VERSION ""

NS_ :

BS_:

BU_: ARM APIM_CDC APIM_CISM APIM ESPM DSP APIM_CIM FCIMB RACM_RCIM HUD_ADV WCM TRM_ITRM ACM GWM _delete IPC GENERIC TSTR
VAL_TABLE_ PwSysULoFalt_D_Stat 15 "Not_Used_6" 14 "LowBatterySOC" 13 "PSS_Shed2_Contin" 12 "Not_Used_4" 11 "Not_Used_3" 10 "Not_Used_2" 9 "BattMonitoringSensorFault" 8 "LowBattVoltDuringPwSrcOn" 7 "LowBatt2_PowerSaveMode" 6 "LowBatt1_Warning" 5 "Overvoltage" 4 "Fault_NoOutput" 3 "Fault_ReducedOutput" 2 "Fault_Nonspecific" 1 "Cluster_Proveout" 0 "No_Fault" ;
VAL_TABLE_ AccStopMde_D_Rq 3 "Stop_Mode_Active" 2 "EPBApplyOrBrakeReleaseWarn" 1 "Limit_Rolling_Speed" 0 "Stop_Mode_Not_Active" ;
VAL_TABLE_ Eng_D_Stat 3 "NotUsed" 2 "EngAutoStopped" 1 "EngOn" 0 "EngOff" ;
VAL_TABLE_ ElPw_D_Stat 7 "NotUsed_3" 6 "NotUsed_2" 5 "NotUsed_1" 4 "Fault_Limited" 3 "LV_Event_In_Progress" 2 "Not_Supported_Imminent" 1 "Supported" 0 "Not_Supported" ;
VAL_TABLE_ PwPckTq_D_Stat 3 "PwPckOn_TqAvailable" 2 "StartInPrgrss_TqNotAvail" 1 "PwPckOn_TqNotAvailable" 0 "PwPckOff_TqNotAvailable" ;
VAL_TABLE_ BattTracCool_D_Falt 3 "NotUsed" 2 "CoolSysPartialyOperational" 1 "Cooling_System_Faulted" 0 "Cooling_System_Operational" ;
VAL_TABLE_ Fault_FF 255 "Fault" ;
VAL_TABLE_ ElCmprOverTe_D_Stat 3 "OverTempStop" 2 "OverTempWarning" 1 "Normal" 0 "Undefined" ;
VAL_TABLE_ ElCmprUHi_D_Stat 3 "Overvoltage" 2 "Undervoltage" 1 "InRange" 0 "Undetermined" ;
VAL_TABLE_ ElCmpr_D_Stat 7 "Signal_Invalid" 6 "Comp_Off_ActlSpd_Abnormal" 5 "Comp_Off_TrgtSpd_OutRange" 4 "Comp_Shutdown" 3 "Comp_Stopped_Self_Protect" 2 "Comp_Degraded" 1 "Comp_On" 0 "Comp_Off" ;
VAL_TABLE_ Southern_Northern 3 "Fault" 2 "Northern" 1 "Southern" 0 "Invalid" ;
VAL_TABLE_ PsngrFrntDetct_D_Actl 3 "Unknown" 2 "Empty" 0 "Faulty" 1 "Occupied" ;
VAL_TABLE_ Inactive_Supported_NotSup 3 "Not_Used" 2 "Not_Supported" 1 "Supported" 0 "Inactive" ;
VAL_TABLE_ Normal_Mode1_2 3 "Undefined" 2 "Mode2" 1 "Mode1" 0 "Normal_Mode" ;
VAL_TABLE_ LaActvAvail 3 "LKA_LCA_LDW_Avail" 2 "LCA_LKA_Avail_LDW_Suppress" 1 "LCA_LKA_Suppress_LDW_Avail" 0 "LCA_LKA_LDW_Suppress" ;
VAL_TABLE_ LA_NotDenied 1 "LA_Denied" 0 "LA_Not_Denied" ;
VAL_TABLE_ HandsOn_Off 1 "Hands_Off" 0 "Hands_On" ;
VAL_TABLE_ Fault_3FF 1023 "Fault" ;
VAL_TABLE_ VedsEvnt_6 5 "Unused_3" 4 "Unused_2" 3 "Unused_1" 2 "NotBelted" 1 "Belted" 0 "NoEvent" 7 "Fault" 6 "NotSupported" ;
VAL_TABLE_ VedsEvnt_5 7 "Fault" 6 "NotSupported" 5 "Unused_3" 4 "Unused_2" 3 "Unused_1" 2 "ChildNotDetected" 1 "ChildDetected" 0 "NoEvent" ;
VAL_TABLE_ VedsEvnt_4 7 "Fault" 6 "NotSupported" 5 "Unused_3" 4 "Unused_2" 3 "Unused_1" 2 "NotDeployed" 1 "Deployed" 0 "NoEvent" ;
VAL_TABLE_ VedsEvnt_3 0 "NoEvent" 255 "Fault" 254 "NotSupported" ;
VAL_TABLE_ VedsEvnt_2 7 "Fault" 6 "NotSupported" 5 "Unused_3" 4 "Unused_2" 3 "Unused_1" 2 "Yes" 1 "No" 0 "NoEvent" ;
VAL_TABLE_ VedsEvnt_1 7 "Fault" 6 "NotSupported" 5 "Unused" 4 "Rolllover" 3 "Rear" 2 "Side" 1 "Frontal" 0 "NoEvent" ;
VAL_TABLE_ Fault_F 15 "Fault" ;
VAL_TABLE_ Fault_1F 31 "Fault" ;
VAL_TABLE_ TmsStatRqDsply 15 "Reserved4" 14 "Reserved3" 13 "Reserved2" 12 "Crawl_Mode_4LOW_Reqd" 11 "Economy_Mode_Select" 10 "ModeChangeNotAvailable" 9 "Terrain_Sys_Not_Avail" 8 "Terrain_System_Fault" 7 "Mode_Change_InProgress" 6 "Dynamics_Mode_Select" 5 "Rock_Crawl_Mode_Select" 4 "Sand_Mode_Select" 3 "Mud_Ruts_Mode_Select" 2 "Low_Mu_Mode_Select" 1 "Special_Modes_Off" 0 "No_Message" ;
VAL_TABLE_ LockInhibit 1 "Inhibit" 0 "No_Inhibit" ;
VAL_TABLE_ Temp_Units 2 "Fahrenheit" 1 "Celsius" 0 "Off" ;
VAL_TABLE_ DieslFuelBio_B_ActlDrv 1 "Biodiesel_User" 0 "Non_Biodiesel_User" ;
VAL_TABLE_ Invalid_FFF 4095 "Invalid" ;
VAL_TABLE_ Off_0x0 0 "Off" ;
VAL_TABLE_ ParkAid_Chime 15 "Zone15_Chime" 14 "Zone14_Chime" 13 "Zone13_Chime" 12 "Zone12_Chime" 11 "Zone11_Chime" 10 "Zone10_Chime" 9 "Zone9_Chime" 8 "Zone8_Chime" 7 "Zone7_Chime" 6 "Zone6_Chime" 5 "Zone5_Chime" 4 "Zone4_Chime" 3 "Zone3_Chime" 2 "Zone2_Chime" 1 "Zone1_Chime" 0 "No_Chime" ;
VAL_TABLE_ Shed_Feature_Group_ID 16 "PtcHeater" 30 "NotUsed_7" 29 "NotUsed_6" 28 "NotUsed_5" 27 "NotUsed_4" 26 "NotUsed_3" 25 "NotUsed_2" 24 "NotUsed_1" 23 "Dcac" 22 "UpFitter_6" 21 "UpFitter_5" 20 "UpFitter_4" 19 "UpFitter_3" 18 "UpFitter_2" 17 "UpFitter_1" 14 "HtdMirr" 13 "HvacRearBlwr_Third" 12 "HvacRearBlwr_Second" 11 "HvacRearBlwr_First" 31 "All LSHED1 Features" 10 "Htd_Windscrn" 9 "SpltHtdBcklight_HtdMirr" 8 "HtdBcklight_HtdMirr" 7 "HtdCoolSeat_FrtDriver" 6 "HtdCoolSeat_FrtPass" 5 "HtdCoolSeat_RearPass" 4 "HtdCoolSeat_RearDriver" 3 "SmartTrlrTowBattCharge" 2 "Htd_StrWhl" 1 "Htd_Washer_Fluid" 0 "No_LSHED1_Features" 15 "Engine_Coolant_Fan" ;
VAL_TABLE_ CoolantFanStepAct 31 "Unused7" 30 "Unused6" 29 "Unused5" 28 "Unused4" 27 "Unused3" 26 "Unused2" 25 "Unused1" 23 "Step23" 22 "Step22" 21 "Step21" 20 "Step20" 19 "Step19" 18 "Step18" 17 "Step17" 16 "Step16" 15 "Step15" 14 "Step14" 13 "Step13" 12 "Step12" 11 "Step11" 10 "Step10" 9 "Step9" 8 "Step8" 7 "Step7" 6 "Step6" 5 "Step5" 4 "Step4" 3 "Step3" 2 "Step2" 1 "Step1" 24 "Max_Fan_Speed_Req" 0 "Fan_Cmd_Off" ;
VAL_TABLE_ Null_Cancel 1 "Cancel" 0 "Null" ;
VAL_TABLE_ Null_Drive_EasyEntry 2 "Easy_Entry" 1 "Drive" 0 "Null" ;
VAL_TABLE_ Veh_Lock_Requestor 31 "Walk_Away_Locking" 30 "Remote_Park_Assist" 29 "DoorsOffToOn_Smart_Unlock" 28 "Rgtm_Shutlock_Switch" 27 "Boundary_Alert" 26 "Transit_Vehicle_Relock" 25 "Transit_Cargo_Relock" 24 "Transit_Ajar_Lock" 23 "Diagnostics" 22 "Console_Lock" 21 "Child_Lock" 20 "Double_Lock" 19 "Passive_Pasenger" 18 "Passive_Driver" 17 "Slam_Lock_Protect" 16 "SYNC" 15 "Passport" 14 "Passive_Smart_Unlock" 13 "Autorelock" 12 "RemoteStart" 0 "Null" 1 "Autolock" 11 "Smart_Unlock" 10 "Sliding_Door" 9 "Passive" 8 "Remote" 7 "Programming" 6 "Powerslide" 5 "Keypad" 4 "Key_Cylinder" 3 "Interior" 2 "Auto_Unlock" ;
VAL_TABLE_ EPAS_FAILURE 3 "SERVICE_POWER_STEERING_NOW" 2 "SERVICE_POWER_STEERING" 1 "POWER_STRG_ASSIST_FAULT" 0 "EPAS_OK_NO_MESSAGE" ;
VAL_TABLE_ Perimeter_Alarm_Mode 3 "Activated" 2 "Armed" 1 "Prearmed" 0 "Disarmed" ;
VAL_TABLE_ Invalid_FFFF 65535 "Invalid" ;
VAL_TABLE_ OilPressureWarning 1 "Low_Pressure_Lamp_On" 0 "Normal_Pressure_Lamp_Off" ;
VAL_TABLE_ MyKey_KeyTypeChangeReq 3 "Search_PE_BackupSlot" 2 "Clear_All_MyKeys" 1 "Request_New_MyKey" 0 "None" ;
VAL_TABLE_ MyKey_Key_Count 13 "Thirteen" 12 "Twelve" 11 "Eleven" 10 "Ten" 9 "Nine" 8 "Eight" 7 "Seven" 6 "Six" 5 "Five" 4 "Four" 3 "Three" 2 "Two" 1 "One" 0 "Zero" 15 "Invalid" 14 "Unlimited" ;
VAL_TABLE_ GearEngag_D_Actl 7 "Undefined" 6 "Fwd_Clutch_Fully_Engaged" 5 "Neutral_Idle" 4 "Disengaged_to_Neutral_Idle" 3 "Disengaged_to_Neutral_Park" 2 "Engagement_in_Progress" 1 "InitializeFwdClutchEngagmt" 0 "Park_Neutral" ;
VAL_TABLE_ Shed_Level_Req 7 "SHED3" 6 "Loads_On" 5 "SHED_ENG_OFF" 4 "SOON_ENG_OFF" 3 "SHED2_CONTIN" 2 "SHED2_TRANS" 1 "SHED1" 0 "NO_SHED" ;
VAL_TABLE_ BpedMove_D_Actl 3 "Unknown" 2 "DriverApplyingBrakePedal" 1 "NoAutonomousBrkPdlMovement" 0 "AutonomousBrkPedalMove" ;
VAL_TABLE_ Eastern_Western 0 "Invalid" 1 "Eastern" 2 "Western" 3 "Fault" ;
VAL_TABLE_ EATC_Temp_Digit3 2 "_5" 1 "_0" 0 "OFF" ;
VAL_TABLE_ EATC_Units 2 "Fahrenheit" 1 "Celsius" 0 "Off" ;
VAL_TABLE_ Invalid_1FF 511 "Invalid" ;
VAL_TABLE_ ChargeMode 7 "Undefined_2" 6 "Undefined_1" 5 "Battery_Identify" 4 "Battery_Refresh" 3 "SlowRegenAllowNoDischarge" 2 "Fast_Regen_Allowed" 1 "Slow_Regen_Allowed" 0 "Conventional_Charging" ;
VAL_TABLE_ Unknown_FFFE_Invalid_FFFF 65535 "Invalid" 65534 "Unknown" ;
VAL_TABLE_ eCallNotification 3 "Not_Used" 2 "Active" 1 "Normal" 0 "Not_Supported" ;
VAL_TABLE_ eCallConfirmation 7 "Unused_2" 6 "CallComplete_DTMF_Timeout" 5 "eCall_Configured_Off" 4 "Call_Unsuccessful" 3 "Call_Cancelled" 2 "Call_Completed" 1 "Call_In_Progress" 0 "Normal" ;
VAL_TABLE_ SAPPAngleControlStat5 1 "StrgColTorqueExceed_EAROn" 0 "ExternalSigContentOKforEAC" ;
VAL_TABLE_ Closed_Open_Active_Fault 3 "Fault" 2 "Active" 1 "Open" 0 "Closed" ;
VAL_TABLE_ SAPPAngleControlStat2 1 "Rel_ExtSteeringAngleReqx" 0 "NoRel_ExtSteeringAngleReqx" ;
VAL_TABLE_ SAPPAngleControlStat3 1 "EARactiveNoReverseEngage" 0 "ExternalSigContentOKforEAC" ;
VAL_TABLE_ RstrnImpactEvntStatus 7 "Invalid" 6 "Not_Used_4" 5 "Threshold_2_Exceeded" 4 "Not_Used_3" 3 "Threshold_1_Exceeded" 2 "Not_Used_2" 1 "Not_Used_1" 0 "Normal" ;
VAL_TABLE_ EDRTriggerEvntSync 1 "Threshold_Exceeded" 0 "Normal" ;
VAL_TABLE_ EngTeColdPrtct_D_Stats 3 "Engine_Warm_RdcPwr" 2 "OK_to_Drive" 1 "Engine_Warm_PlsWait" 0 "Normal_Operation" ;
VAL_TABLE_ HILL_DESC_MC 7 "Fault_Detected" 6 "Cooling_Down" 5 "Abort_Apply_Brakes" 4 "Active" 3 "Disabled" 2 "Enabled" 1 "Off_Road" 0 "Normal" ;
VAL_TABLE_ Closed_Ajar 1 "Ajar" 0 "Closed" ;
VAL_TABLE_ CADS_Autio_Mute 7 "Unknown" 6 "Attenuation_6" 5 "Attenuation_5" 4 "Attenuation_4" 3 "Attenuation_3" 2 "Attenuation_2" 1 "Attenuation_1" 0 "No_Attenuation_of_Audio" ;
VAL_TABLE_ Quality_Factor 3 "OK" 2 "Not_Within_Specifications" 1 "No_Data_Exists" 0 "Faulty" ;
VAL_TABLE_ Null_Day_Night 3 "NotUsed" 2 "Night" 1 "Day" 0 "Null" ;
VAL_TABLE_ Null_Flash_High 3 "NotUsed" 2 "High" 1 "Flash_to_Pass" 0 "Null" ;
VAL_TABLE_ GearPos_D_Actl 15 "Unknown" 14 "Reverse" 13 "Undefined_5" 12 "Undefined_4" 11 "Undefined_3" 10 "Tenth" 9 "Ninth" 8 "Eighth" 7 "Seventh" 6 "Sixth" 5 "Fifth" 4 "Fourth" 3 "Third" 2 "Second" 1 "First" 0 "Neutral" ;
VAL_TABLE_ OffOn_SlowFast_Flash 3 "Fast_Flash" 2 "Slow_Flash" 1 "On" 0 "Off" ;
VAL_TABLE_ AwdStat_D_RqDsply 31 "Rear_Diff_Lock_Not_Avail" 30 "_4wd_Lock_Required" 29 "Cfg_Perf_Redc_See_Manual" 28 "To_Engage_4x4_Release_Aped" 27 "To_Engage_4x4_Slow_To_3MPH" 26 "Shift_To_Neutral" 25 "Lkr_Mode_Unavail_TMS" 24 " _4x4_Mode_Unavail_TMS" 23 "Out_of_4Low_Crawl" 22 "AWD_PTU_Oil_Changed" 21 "Change_AWD_PTU_Oil" 20 "Neutral_Tow_Disabled" 19 "Neutral_Tow_Enabled" 18 "AWD_OFF" 17 "_4x4_Off_Road_Speed" 16 "_4x4_Extreme_Off_Road_Mode" 15 "_4x4_Exiting_Off_Road" 14 "_4x4_Off_Road_Mode" 10 "_4x4_Locked_Temporarily" 9 "Shift_In_Progress" 13 "Blocked_Shift_Assist" 12 "_4x4_Auto_Restored" 11 "_4x4_Disabled_Temporarily" 7 "Out_of_4Low__Neutral" 6 "Out_of_4Low__Brake" 5 "Out_of_4Low__Speed" 4 "Into_4Low__Clutch" 3 "Into_4Low__Neutral" 2 "Into_4Low__Brake" 1 "Into_4Low__Speed" 0 "Normal__No_Message" 8 "Out_of_4Low__Clutch" ;
VAL_TABLE_ AngleReached 1 "RequestedAngleNotReached" 0 "RequestedAngleCanBeReached" ;
VAL_TABLE_ WhlDir 3 "Faulty" 2 "NoDataExists" 1 "Backward" 0 "Forward" ;
VAL_TABLE_ VehVLimStat_D_Actl 7 "Undefined_3" 6 "Undefined_2" 5 "Undefined_1" 4 "ASL_Fault_Condition" 3 "Active_and_Limiting" 2 "Active_but_Not_Limiting" 1 "Standby" 0 "Off" ;
VAL_TABLE_ Unknown_Fault_1FE_1FF 511 "Fault" 510 "Unknown" ;
VAL_TABLE_ Fault_NoFault 1 "Fault" 0 "No_Fault" ;
VAL_TABLE_ TrnIpcDsplyMde_D_Actl 7 "Manual_3" 6 "Manual_2" 5 "Manual_1_Low" 4 "Sport" 3 "Drive" 2 "Neutral" 1 "Reverse" 0 "Park" ;
VAL_TABLE_ TrnIpcDsplyMde_D_Stat 3 "Reserved_Blank_No_Display" 2 "Flash" 1 "On" 0 "Blank_No_Display" ;
VAL_TABLE_ TrnIpcDsplyGear_D_Actl 15 "No_Gear_Selected" 14 "_14th_Gear" 13 "_13th_Gear" 12 "_12th_Gear" 11 "_11th_Gear" 10 "_10th_Gear" 9 "_9th_Gear" 8 "_8th_Gear" 7 "_7th_Gear" 6 "_6th_Gear" 5 "_5th_Gear" 4 "_4th_Gear" 3 "_3rd_Gear" 2 "_2nd_Gear" 1 "_1st_Gear" 0 "Neutral" ;
VAL_TABLE_ TerrMde_D_Actl 7 "Fail_Safe_Default" 6 "Dynamic_Mode" 5 "Rock_Crawl_Mode" 4 "Mud_Ruts_Mode" 3 "Sand_Mode" 2 "Undefined" 1 "Low_Mu_Mode" 0 "Special_Operating_Mode_Off" ;
VAL_TABLE_ TerrMdeChng_D_Rdy 7 "Fault" 6 "Undefined_2" 5 "Undefined_1" 4 "ModeUnavailDrInputRqd" 3 "SpOpModes_NotSupported" 2 "ModeUnavailDynamicCond" 1 "Module_In_Initialization" 0 "Mode_Change_Available" ;
VAL_TABLE_ Unknown_Fault_FFFE_FFFF 65535 "Fault" 65534 "Unknown" ;
VAL_TABLE_ Invalid_FFFFFF 16777215 "Invalid" ;
VAL_TABLE_ AutoParkSpdExitCond 1 "SpeedLimitExceededEAROn" 0 "ExternalSigContentOKforEAC" ;
VAL_TABLE_ EngOilLvlDsply_D_Rq 15 "EngOil_LevelSys_CheckFault" 14 "Reserved_2" 13 "Reserved_1" 12 "Conditions_Unsuitable" 11 "Dipstick_Below_Minimum" 10 "Dipstick_Above_Maximum" 9 "Dipstick_Minimum" 8 "Dipstick_12_5_MinMaxRange" 7 "Dipstick_25_MinMaxRange" 6 "Dipstick_37_5_MinMaxRange" 5 "Dipstick_50_MinMaxRange" 4 "Dipstick_62_5_MinMaxRange" 3 "Dipstick_75_MinMaxRange" 2 "Dipstick_87_5_MinMaxRange" 1 "Dipstick_Maximum_Displayed" 0 "No_Message" ;
VAL_TABLE_ HdcMde_D_Actl 7 "Fault" 6 "Temporarily_Unavailable" 5 "NotEnabled_WrongGearSel" 4 "NotEnabled_SpdLimitExceed" 3 "Active_Braking" 2 "Not_Active_Braking" 1 "Off" 0 "Undefined" ;
VAL_TABLE_ GearLvrPos_D_Actl 15 "Fault" 14 "Unknown_Position" 13 "Undefined_Treat_as__Fault" 12 "Undefined_Treat_as_Fault" 11 "sixth" 10 "fifth" 9 "fourth" 8 "third" 7 "second" 6 "first" 5 "Low" 4 "Sport_DriveSport" 3 "Drive" 2 "Neutral" 1 "Reverse" 0 "Park" ;
VAL_TABLE_ FcwMsgTxt_D_Rq 7 "Undefined_3" 6 "Undefined_2" 5 "Low_Visibility" 4 "Unavailable_DueTo_LowSpeed" 3 "Available" 2 "Unavailable" 1 "Off" 0 "No_Text" ;
VAL_TABLE_ FcwSens_B_Actl 3 "FCW_Sensitivity_3" 2 "FCW_Sensitivity_2" 1 "FCW_Sensitivity_1" 0 "Not_Used" ;
VAL_TABLE_ EngTurboMde_D_Actl 3 "Fault" 2 "One_Turbo_Active" 1 "Two_Turbos_Active" 0 "Initializing" ;
VAL_TABLE_ DrvHdcMsg_D_Rq 7 "Undefined" 6 "Speed_too_High" 5 "Temporarily_Unavailable" 4 "System_Fault" 3 "Select_Gear" 2 "Off" 1 "On" 0 "No_Message" ;
VAL_TABLE_ CcStat_D_Actl 7 "Undefined_2" 6 "Undefined_1" 5 "Active" 4 "Active_Que_Assist" 3 "Standby" 2 "Standby_Denied" 1 "Denied" 0 "Off" ;
VAL_TABLE_ BpedDrvAppl_D_Actl 3 "_Not_Allowed" 2 "Driver_Braking" 1 "Driver_Not_Braking" 0 "Not_Allowed" ;
VAL_TABLE_ AslIconDsply_D_Rq 3 "On_Passive_Overridden" 2 "On_Active" 1 "On_Passive" 0 "Off" ;
VAL_TABLE_ Unknown_Fault_3E_3F 63 "Fault" 62 "Unknown" ;
VAL_TABLE_ AccWarn_D_Dsply 3 "BrakeReleaseWarn_In_StopMd" 2 "Brake_Capacity_Warning" 1 "Cancel_Warning" 0 "No_Warning" ;
VAL_TABLE_ AccTrgDist2_D_Dsply 15 "DIST_ACTIVE_13_Farthest" 14 "DIST_ACTIVE_12" 13 "DIST_ACTIVE_11" 12 "DIST_ACTIVE_10" 11 "DIST_ACTIVE_9" 10 "DIST_ACTIVE_8" 9 "DIST_ACTIVE_7" 8 "DIST_ACTIVE_6" 7 "DIST_ACTIVE_5" 6 "DIST_ACTIVE_4" 5 "DIST_ACTIVE_3" 4 "DIST_ACTIVE_2" 3 "DIST_ACTIVE_1_Closest" 2 "DIST_ACTIVE_No_Target" 1 "DIST_STANDBY" 0 "DIST_OFF" ;
VAL_TABLE_ AccTGap_D_Dsply 7 "Undefined_2" 6 "Undefined_1" 5 "Time_Gap_5" 4 "Time_Gap_4" 3 "Time_Gap_3" 2 "Time_Gap_2" 1 "Time_Gap_1" 0 "Not_Used" ;
VAL_TABLE_ AccEngStat_D_Actl 7 "Undefined_2" 6 "Undefined_1" 5 "ACCSoonCancel_due_Low_Spd" 4 "Shift_Down_Recommendation" 3 "Shift_Up_Recommendation" 2 "ACCNotAllowedToBeActivated" 1 "ACCStandby_due_Auto_Cancel" 0 "Normal_Operation" ;
VAL_TABLE_ NotPressed_Pressed 1 "Pressed" 0 "Not_Pressed" ;
VAL_TABLE_ TrnGear_D_RqDrv 31 "Fault" 30 "NotUsed_25" 29 "NotUsed_24" 28 "NotUsed_23" 27 "NotUsed_22" 26 "NotUsed_21" 25 "NotUsed_20" 24 "NotUsed_19" 23 "NotUsed_18" 22 "NotUsed_17" 21 "Return_To_Park" 20 "NotUsed_15" 19 "NotUsed_14" 18 "NotUsed_13" 17 "NotUsed_12" 16 "Manual" 15 "Not_Used11" 14 "Not_Used10" 13 "NotUsed_9" 12 "NotUsed_8" 11 "NotUsed_7" 10 "NotUsed_6" 9 "NotUsed_5" 8 "Drive" 7 "NotUsed_4" 6 "NotUsed_3" 5 "NotUsed_2" 4 "Neutral" 3 "NotUsed_1" 2 "Reverse" 1 "Park" 0 "No_Gear" ;
VAL_TABLE_ Open_Close 1 "Close" 0 "Open" ;
VAL_TABLE_ DasWarn 3 "Undefined" 2 "Warning_Level_2" 1 "Warning_Level_1" 0 "No_Warning" ;
VAL_TABLE_ DasAlert 5 "Alertness_Level_5" 4 "Alertness_Level_4" 3 "Alertness_Level_3" 2 "Alertness_Level_2" 1 "Alertness_Level_1" 0 "Undefined" ;
VAL_TABLE_ DasStat 3 "Available" 2 "Unavailable_Other" 1 "Feedback_due_to_Speed" 0 "Off" ;
VAL_TABLE_ No_Crank_Req 1 "Crank_Request" 0 "No_Crank_Request" ;
VAL_TABLE_ DrvSlipCtlMde_D_Rq 3 "App_Specific_Off_Mode_3" 2 "App_Specific_Off_Mode_2" 1 "App_Specific_Off_Mode_1" 0 "Default_Mode" ;
VAL_TABLE_ AwdOffRoadMode 3 "Invalid" 2 "Extreme_Off_Road" 1 "Off_Road" 0 "Normal_Mode" ;
VAL_TABLE_ NotQuiet_Quiet 1 "Quiet" 0 "Not_Quiet" ;
VAL_TABLE_ Normal_AdaptiveCruise 1 "Adaptive_Cruise" 0 "Normal_Cruise" ;
VAL_TABLE_ Remote_Device_Feedback 7 "Unused3" 6 "Unused2" 5 "Unused1" 4 "Shutdown" 3 "Running" 2 "Starting" 1 "Acknowledge" 0 "Null" ;
VAL_TABLE_ TrnManShif_D_IndDrv 7 "Undefined_3" 6 "Undefined_2" 5 "Shift_to_Neutral" 4 "Downshift_Recommendation" 3 "Upshift_Warning" 2 "Upshift_Performance" 1 "Upshift_Fuel_Economy" 0 "No_Indication" ;
VAL_TABLE_ Unlock_Lock 1 "Locked" 0 "Unlock" ;
VAL_TABLE_ DieslPrtc_D_RqDsply 7 "Unused_2" 6 "Unused_1" 5 "DPF_SOOT_Level3_Blocked" 4 "DPFSootLvl2_SevereOverload" 3 "DPFRegen_ExhFilterComplete" 2 "DPFRegen_CleanExhFilter" 1 "DPF_Soot_Level1_Overloaded" 0 "DPF_OK_Normal_Operation" ;
VAL_TABLE_ PE_BackupSlot_Status 3 "No_Valid_FOB_In_Slot" 2 "MyKey_FOB_In_Slot" 1 "Standard_FOB_In_Slot" 0 "Null" ;
VAL_TABLE_ Unknown_Fault_FFE_FFF 4095 "Fault" 4094 "Unknown" ;
VAL_TABLE_ Unknown_Fault_1FFE_1FFF 8191 "Fault" 8190 "Unknown" ;
VAL_TABLE_ TrnCnvtClu_D_Actl 3 "Transition_or_Micro_Slip" 2 "Lock_Up_Fixed" 1 "Lock_Up_Slip" 0 "No_Lock_Up" ;
VAL_TABLE_ InhibitNoinhibit 1 "Inhibit" 0 "No_Inibit" ;
VAL_TABLE_ DisableEnable 1 "Enable" 0 "Disable" ;
VAL_TABLE_ Unknown_Fault_7FFE_7FFF 32767 "Fault" 32766 "Unknown" ;
VAL_TABLE_ Side_Detect_Sn_State 3 "Second_Warning_Audio" 2 "System_Failure" 1 "Blocked" 0 "Clear" ;
VAL_TABLE_ Litval_values 255 "Invalid" 254 "Unknown" 5 "Day" 4 "Twilight_4" 3 "Twilight_3" 2 "Twilight_2" 1 "Twilight_1" 0 "Night" ;
VAL_TABLE_ Dimming_Lvl 255 "Invalid" 254 "Unknown" 18 "Day_6" 17 "Day_5" 16 "Day_4" 15 "Day_3" 14 "Day_2" 13 "Day_1" 12 "Night_12" 11 "Night_11" 10 "Night_10" 9 "Night_9" 8 "Night_8" 7 "Night_7" 6 "Night_6" 5 "Night_5" 4 "Night_4" 3 "Night_3" 2 "Night_2" 1 "Night_1" 0 "Off" ;
VAL_TABLE_ NotOperating 1 "Operating" 0 "Not_Operating" ;
VAL_TABLE_ CamraStat 3 "FrtCam_TempUnavailOther" 2 "FrtCam_TempUnavailVisibile" 1 "Front_Camera_Service_Reqd" 0 "Front_Camera_OK" ;
VAL_TABLE_ EngPtoMde_D_Actl 7 "Undefined" 6 "Split_Shaft_Stationary" 5 "Not_Used_2" 4 "PTO_Mobile" 3 "Not_Used_1" 2 "PTO_Stationary" 1 "BCP" 0 "Off" ;
VAL_TABLE_ ManRgen_D_Rq 3 "NotUsed2" 2 "NotUsed1" 1 "CustInitManExhFilterClean" 0 "No_Customer_Request" ;
VAL_TABLE_ Remote_Start_Status 3 "Invalid" 2 "Unknown" 1 "Remote" 0 "Null" ;
VAL_TABLE_ Enabled_Active_Disabled 3 "Unused" 2 "Disabled" 1 "Active" 0 "Enabled_Inactive" ;
VAL_TABLE_ Lock_Subld 15 "Unused7" 14 "Unused6" 13 "Unused5" 12 "Unused4" 11 "Unused3" 10 "Unused2" 9 "Unused1" 8 "Customer_8" 7 "Customer_7" 6 "Customer_6" 5 "Customer_5" 4 "Customer_4" 3 "Customer_3" 2 "Customer_2" 1 "Customer_1" 0 "Null" ;
VAL_TABLE_ Brake_Fluid 3 "Invalid" 2 "Unknown" 1 "Low" 0 "OK" ;
VAL_TABLE_ Unknown_Invalid_FE_FF 255 "Invalid" 254 "Unknown" ;
VAL_TABLE_ Invalid_FF 255 "Invalid" ;
VAL_TABLE_ NotLow_Low 1 "Low" 0 "Not_Low" ;
VAL_TABLE_ Disabled_Enabled_Status 2 "Status" 3 "NotUsed" 1 "Enabled" 0 "Disabled" ;
VAL_TABLE_ Key_In_Ignition_Status 1 "In" 0 "Out" ;
VAL_TABLE_ Ignition_Status 0 "Unknown" 1 "Off" 15 "Invalid" 8 "Start" 4 "Run" 2 "Accessory" ;
VAL_TABLE_ Disabled_Enabled_Faulted 3 "Faulted" 2 "Unused" 1 "Enabled" 0 "Disabled" ;
VAL_TABLE_ Disabled_Enabled_NoSupport 2 "Unused" 3 "Not_Supported" 1 "Enabled" 0 "Disabled" ;
VAL_TABLE_ Unknown_Fault_FE_FF 255 "Fault" 254 "Unknown" ;
VAL_TABLE_ Null_Unlock 1 "Unlock" 0 "Null" ;
VAL_TABLE_ Null_Active 1 "Active" 0 "Null" ;
VAL_TABLE_ MemoryCmd 7 "Recall_3" 4 "Store_4" 3 "Store_3" 6 "Recall_2" 5 "Recall_1" 2 "Store_2" 1 "Store_1" 0 "Null" 8 "Recall_4" ;
VAL_TABLE_ HsaStat_D_Actl 7 "Faulty" 6 "FaultyWithDriverIndication" 5 "SlowRelease" 4 "FastRelease" 3 "ActiveBrakePedalReleased" 2 "ActiveBrakePedalPressed" 1 "FindingGradient" 0 "Inactive" ;
VAL_TABLE_ Off_Auto_Manual 3 "Undefined" 2 "Manual" 1 "Automatic" 0 "Off" ;
VAL_TABLE_ HsaStat_D_Dsply 7 "NotUsed3" 6 "NotUsed2" 5 "NotUsed1" 4 "NotAvailable" 3 "SlowReleaseWithChime" 2 "SlowReleaseWithoutChime" 1 "Active" 0 "Inactive" ;
VAL_TABLE_ EngMsgTxt_D_Rq 3 "Undefined_2" 2 "Undefined_1" 1 "Power_Reduced_to_LowerTemp" 0 "No_Message" ;
VAL_TABLE_ PassRstrnInd_Stat 7 "Invalid" 6 "Unused_2" 5 "Unused_1" 4 "Both_Indicators_Faulted" 3 "AirbagOff_Indicator_fault" 2 "AirbagOn_Indicator_fault" 1 "Normal" 0 "Not_Supported" ;
VAL_TABLE_ PassRstrnInd_Req 3 "ABOnNotIllum_OffNotIllum" 2 "AirbagOnNot_Illum_OffIllum" 1 "AirbagOn_Illum_OffNotIllum" 0 "AirbagOn_Illum_Off_Illum" ;
VAL_TABLE_ RearDiffLckMsg_D_Rq 7 "Locker_Disabled" 6 "Locker_Enabled" 5 "Locker_Accel_Pedal" 4 "Speed4" 3 "Speed3" 2 "Spee2" 1 "Speed1" 0 "Normal__No_Message " ;
VAL_TABLE_ GPS_dimension 2 "_3D" 1 "_2D" 0 "No_Fix" ;
VAL_TABLE_ GPS_Compass_dirctn 7 "NorthWest" 6 "West" 5 "SouthWest" 4 "South" 3 "SouthEast" 2 "East" 1 "NorthEast" 0 "North" ;
VAL_TABLE_ GPS_Actual_Infer 1 "Inferred_Position" 0 "Actual_Postition" ;
VAL_TABLE_ DrvHdcWarnInfo_D_Rq 3 "Undefined" 2 "Lamp_On_Continuously" 1 "Lamp_Flashing" 0 "Lamp_Off_Continuously" ;
VAL_TABLE_ DieslPrtcRgen_D_Actl 3 "Undefined" 2 "Regen_Level_2" 1 "Regen_Level_1" 0 "No_regen" ;
VAL_TABLE_ Off_On 1 "On" 0 "Off" ;
VAL_TABLE_ CcMde_D_Actl 7 "TapDownWaiting" 6 "TapUpWaiting" 5 "Resuming_Low" 4 "Resuming_High" 3 "Decelerating" 2 "Accelerating" 1 "Keeping_Speed" 0 "Not_Active" ;
VAL_TABLE_ InactiveActive 1 "Active" 0 "Inactive" ;
VAL_TABLE_ ManRgenTxt_D_RqDsply 7 "NotUsed3" 6 "NotUsed2" 5 "NotUsed1" 4 "Cleaning_Aborted_Stopped" 3 "Cleaning_Completed" 2 "Cleaning_In_Progress" 1 "Cleaning_Allowed" 0 "Cleaning_Not_Allowed" ;
VAL_TABLE_ Fault_FFFF 65535 "Fault" ;
VAL_TABLE_ Fault_7F 127 "Fault" ;
VAL_TABLE_ EngOilLvlWarn_D_Rq 7 "Undefined_3" 6 "Undefined_2" 5 "Engine_Oil_Monitor_Fault" 3 "Engine_Oil_High" 2 "Engine_Oil_Critical_Low" 1 "Engine_Oil_Low" 0 "No_Message" 4 "Engine_Oil_Critical_High" ;
VAL_TABLE_ UreaQltySys_D_RqDsply 7 "Undefined" 6 "ZZ_Overrides" 5 "EngineIdled" 4 "Engine_Idle_Upon_Refuel" 3 "SPEED_LIMITED_to_YY_mph" 2 "YY_MPH_MAX_UPON_Restart" 1 "CONTAMINATED_ExhFluid" 0 "NoQualityProblem" ;
VAL_TABLE_ Unknown_Invalid_1E_1F 31 "Invalid" 30 "Unknown" ;
VAL_TABLE_ Unknown_Invalid_3FFE_3FFF 16383 "Invalid" 16382 "Unknown" ;
VAL_TABLE_ NoYes 1 "Yes" 0 "No" ;
VAL_TABLE_ AwdRnge_D_Actl 7 "Unknown" 6 "High_Range_2wd" 5 "High_Range_Auto" 4 "High_Range_Locked" 3 "Neutral" 2 "Low_Range_2wd" 1 "Low_Range_Auto" 0 "Low_Range_Locked" ;
VAL_TABLE_ AwdLck_D_Stat 9 "Undefined" 8 "Under_External_Torque_Ctrl" 7 "Torque_Limited_by_Cmd" 6 "Fully_Locked_by_Cmd" 5 "Disabled" 4 "Warning" 3 "Fault" 2 "Inactive" 1 "Completely_Opened_by_Cmd" 0 "OK" ;
VAL_TABLE_ Unknown_Fault_3FE_3FF 1023 "Fault" 1022 "Unknown" ;
VAL_TABLE_ LockSwStat 3 "Invalid" 2 "Unlock" 1 "Lock" 0 "Null" ;
VAL_TABLE_ Null_Override 1 "Override" 0 "Null" ;
VAL_TABLE_ Off_On_Flash 3 "Not_Used" 2 "Flash" 1 "On" 0 "Off" ;
VAL_TABLE_ BeltBuckle 3 "Unknown" 2 "Unbelted" 1 "Belted" 0 "Faulty" ;
VAL_TABLE_ RILStat 3 "Fault" 2 "Plant_Mode" 1 "On" 0 "Off" ;
VAL_TABLE_ RILReqCoding 3 "Not_Used" 2 "Plant_Mode" 1 "On" 0 "Off" ;
VAL_TABLE_ Update_Bit 1 "Fresh_data" 0 "Unchanged_data" ;
VAL_TABLE_ Tire_Pressure_Stat 4 "Alert" 15 "Not_Supported" 3 "Fault" 2 "Low" 1 "Normal" 0 "Unknown" ;
VAL_TABLE_ Tire_Pressure_System2 13 "Training_Complete" 12 "Train_InsideLeftRear_tire" 11 "Train_OutsideLeftRear_tire" 10 "Train_LeftRear_tire" 9 "Train_InsideRtRear_tire" 8 "Train_OutsideRtRear_tire" 7 "Train_RightRear_tire" 14 "Tires_not_trained" 6 "Train_RightFront_tire" 5 "Train_LeftFront_tire" 4 "Systm_Activ_Composite_Stat" 3 "Low_Composite_Stat" 2 "Sensr_Fault_Composite_Stat" 1 "Systm_Fault_Composite_Stat" 0 "Unknown_Composite_Stat" ;
VAL_TABLE_ Running_Board 3 "Unused" 2 "Manually_Deployed" 1 "All_Enabled" 0 "All_Disabled" ;
VAL_TABLE_ Turn_Seq 3 "Seq" 2 "On" 1 "Off" 0 "Null" ;
VAL_TABLE_ Invalid_Active_Inactive 3 "Not_Used" 2 "Inactive" 1 "Active" 0 "Invalid" ;
VAL_TABLE_ Rvc_Zoom 7 "Unknown" 6 "Invalid" 5 "Zoom_Level_V" 4 "Zoom_Level_IV" 3 "Zoom_Level_III" 2 "Zoom_Level_II" 1 "Zoom_Level_I" 0 "Off" ;
VAL_TABLE_ NotPark 1 "Park" 0 "Not_Park" ;
VAL_TABLE_ Electric_EOH 1 "Electric_Over_Hydraulic" 0 "Electric" ;
VAL_TABLE_ PersOptIn 1 "OPTED_IN" 0 "NOT_OPTED_IN" ;
VAL_TABLE_ PersonalSetUp 3 "Non_Moveable_Person" 2 "Moveable_Person" 1 "Vehicle" 0 "Factory" ;
VAL_TABLE_ Full_Limited 1 "Limited" 0 "Full" ;
VAL_TABLE_ NoConflict_Conflict 1 "Conflict" 0 "No_Conflict" ;
VAL_TABLE_ Assoc_Confirm 0 "None" 7 "Associate" 6 "Keycode_Rejected" 5 "Keycode_Accepted" 4 "In_Progress" 3 "Erase" 2 "Duplicate" 1 "Disassociate" ;
VAL_TABLE_ Check_KeyCode 7 "Unused_2" 6 "Cancel" 5 "Set_Keycode" 4 "RKE" 3 "Null" 2 "Key" 1 "Erase_KeyCode" 0 "Check_KeyCode" ;
VAL_TABLE_ Complete_Inprogress 3 "Unused" 2 "Null" 1 "InProgress" 0 "Complete" ;
VAL_TABLE_ Null_Pers1_4 7 "Unused_3" 6 "Unused_2" 5 "Unused_1" 4 "PERS_4" 3 "PERS_3" 2 "PERS_2" 1 "PERS_1" 0 "Null" ;
VAL_TABLE_ Pers1_4 7 "Unused_3" 6 "Unused_2" 5 "Unused_1" 4 "Vehicle" 3 "PERS_4" 2 "PERS_3" 1 "PERS_2" 0 "PERS_1" ;
VAL_TABLE_ Null_Query 7 "Unused_2" 6 "Unused_1" 5 "Copy" 4 "Restore" 3 "Upload" 2 "Set" 1 "Query" 0 "Null" ;
VAL_TABLE_ EngExhBrkMde_D_Actl 6 "ExhBrkDisable_NoError" 5 "ExhBrkActive_AUTO" 4 "ExhBrkActive_ON" 3 "ExhBrkRequest_AUTO" 2 "ExhBrkRequest_ON" 1 "ExhBrkNoRequest_OFF" 0 "ExhBrkUnavailable_Error" ;
VAL_TABLE_ UreaLvlTxt_D_RqDsply 15 "NotUsed_4" 14 "NotUsed_3" 13 "NotUsed_2" 12 "NotUsed_1" 11 "System_Error" 10 "Engine_Idled_See_Manual" 9 "Engine_Idled_Upon_Refuel" 8 "Speed_Limited_To_XX_mph" 7 "XXmph_Max_Upon_Restart" 6 "Speed_Limited_To_YY_mph" 5 "YYmph_Max_Upon_Restart" 4 "SpdLimtd_YYmph_In_XXmiles" 3 "ExFlRange_XXMiles_ScndWarn" 2 "Exh_Fluid_Range_XX_Miles" 1 "Exh_Fluid_Under_Half_Full" 0 "Exh_Fluid_Over_Half_Full" ;
VAL_TABLE_ RearDiffFalt_D_Stat 3 "Diff_Failed_Closed" 2 "Diff_Failed_Open" 1 "Fault_Non_Specific" 0 "No_Fault" ;
VAL_TABLE_ CCOverridden 1 "Cruise_Overridden" 0 "Cruise_Req_Not_Overridden" ;
VAL_TABLE_ Ign_Key_Device_Type 15 "Invalid" 14 "Unknown" 3 "Key_Not_Prgrm_Read_Failure" 2 "Key_In_Ign_My_Key" 1 "Key_In_Ign_Standard_Key" 0 "Key_Read_In_Progress" ;
VAL_TABLE_ Off_No_Eff_Unknown_Invalid 3 "Invalid" 2 "Unknown" 1 "No_Effect" 0 "Off" ;
VAL_TABLE_ Null_Out 1 "Out" 0 "Null" ;
VAL_TABLE_ FUEL_SENSORS 1 "Dual_Sensors" 0 "Single_Sensor" ;

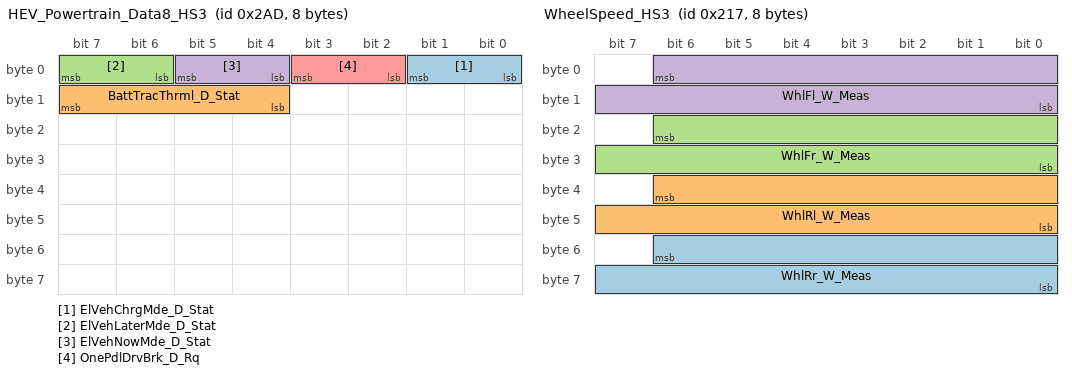
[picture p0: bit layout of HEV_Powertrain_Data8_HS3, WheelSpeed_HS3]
BO_ 685 HEV_Powertrain_Data8_HS3: 8 GWM
 SG_ ElVehChrgMde_D_Stat : 1|2@0+ (1,0) [0|3] "SED"  APIM
 SG_ BattTracThrml_D_Stat : 15|4@0+ (1,0) [0|15] "SED" Vector__XXX
 SG_ ElVehLaterMde_D_Stat : 7|2@0+ (1,0) [0|3] "SED" Vector__XXX
 SG_ ElVehNowMde_D_Stat : 5|2@0+ (1,0) [0|3] "SED" Vector__XXX
 SG_ OnePdlDrvBrk_D_Rq : 3|2@0+ (1,0) [0|3] "SED" Vector__XXX

BO_ 535 WheelSpeed_HS3: 8 GWM
 SG_ WhlRr_W_Meas : 54|15@0+ (0.01,0) [0|327.65] "rad/s"  ARM
 SG_ WhlRl_W_Meas : 38|15@0+ (0.01,0) [0|327.65] "rad/s"  ARM
 SG_ WhlFr_W_Meas : 22|15@0+ (0.01,0) [0|327.65] "rad/s"  ARM
 SG_ WhlFl_W_Meas : 6|15@0+ (0.01,0) [0|327.65] "rad/s"  ARM

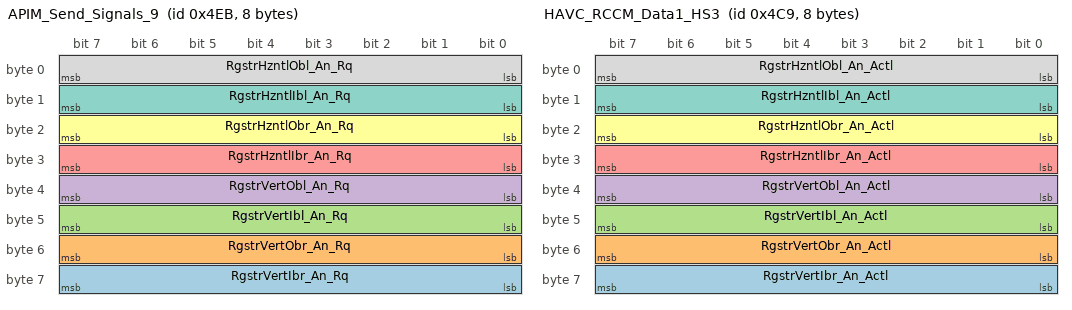
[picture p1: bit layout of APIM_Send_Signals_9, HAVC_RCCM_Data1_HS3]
BO_ 1259 APIM_Send_Signals_9: 8 APIM_CISM
 SG_ RgstrVertIbr_An_Rq : 63|8@0+ (1,0) [0|255] "degree"  GWM
 SG_ RgstrVertObr_An_Rq : 55|8@0+ (1,0) [0|255] "degree"  GWM
 SG_ RgstrVertIbl_An_Rq : 47|8@0+ (1,0) [0|255] "degree"  GWM
 SG_ RgstrVertObl_An_Rq : 39|8@0+ (1,0) [0|255] "degree"  GWM
 SG_ RgstrHzntlIbr_An_Rq : 31|8@0+ (1,0) [0|255] "degree"  GWM
 SG_ RgstrHzntlObr_An_Rq : 23|8@0+ (1,0) [0|255] "degree"  GWM
 SG_ RgstrHzntlIbl_An_Rq : 15|8@0+ (1,0) [0|255] "degree"  GWM
 SG_ RgstrHzntlObl_An_Rq : 7|8@0+ (1,0) [0|255] "degree"  GWM

BO_ 1225 HAVC_RCCM_Data1_HS3: 8 GWM
 SG_ RgstrVertIbr_An_Actl : 63|8@0+ (1,0) [0|255] "degree"  APIM,APIM_CDC,APIM_CIM,APIM_CISM
 SG_ RgstrVertObr_An_Actl : 55|8@0+ (1,0) [0|255] "degree"  APIM,APIM_CDC,APIM_CIM,APIM_CISM
 SG_ RgstrVertIbl_An_Actl : 47|8@0+ (1,0) [0|255] "degree"  APIM,APIM_CDC,APIM_CIM,APIM_CISM
 SG_ RgstrVertObl_An_Actl : 39|8@0+ (1,0) [0|255] "degree"  APIM,APIM_CDC,APIM_CIM,APIM_CISM
 SG_ RgstrHzntlIbr_An_Actl : 31|8@0+ (1,0) [0|255] "degree"  APIM,APIM_CDC,APIM_CIM,APIM_CISM
 SG_ RgstrHzntlObr_An_Actl : 23|8@0+ (1,0) [0|255] "degree"  APIM,APIM_CDC,APIM_CIM,APIM_CISM
 SG_ RgstrHzntlIbl_An_Actl : 15|8@0+ (1,0) [0|255] "degree"  APIM,APIM_CDC,APIM_CIM,APIM_CISM
 SG_ RgstrHzntlObl_An_Actl : 7|8@0+ (1,0) [0|255] "degree"  APIM,APIM_CDC,APIM_CIM,APIM_CISM

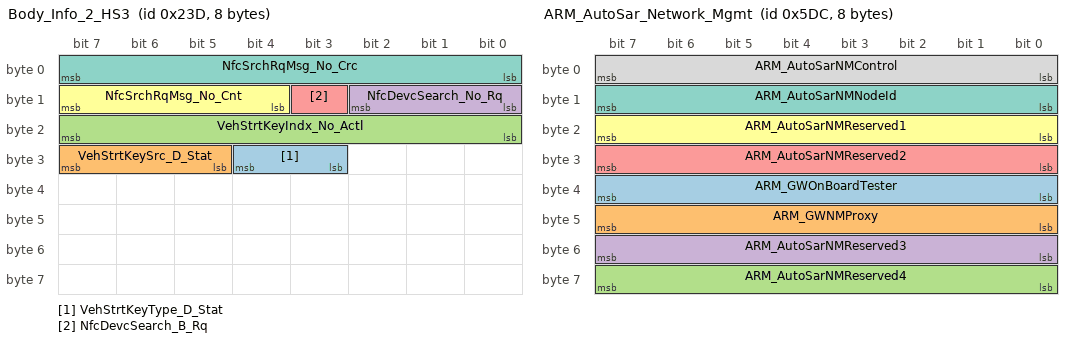
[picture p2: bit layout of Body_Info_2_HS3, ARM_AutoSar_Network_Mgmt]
BO_ 573 Body_Info_2_HS3: 8 GWM
 SG_ VehStrtKeyType_D_Stat : 28|2@0+ (1,0) [0|3] "SED"  APIM
 SG_ VehStrtKeySrc_D_Stat : 31|3@0+ (1,0) [0|7] "SED"  APIM
 SG_ VehStrtKeyIndx_No_Actl : 23|8@0+ (1,0) [0|255] "unitless"  APIM
 SG_ NfcDevcSearch_No_Rq : 10|3@0+ (1,0) [0|7] "unitless" Vector__XXX
 SG_ NfcDevcSearch_B_Rq : 11|1@0+ (1,0) [0|1] "SED" Vector__XXX
 SG_ NfcSrchRqMsg_No_Cnt : 15|4@0+ (1,0) [0|15] "unitless" Vector__XXX
 SG_ NfcSrchRqMsg_No_Crc : 7|8@0+ (1,0) [0|255] "unitless" Vector__XXX

BO_ 1500 ARM_AutoSar_Network_Mgmt: 8 ARM
 SG_ ARM_GWOnBoardTester : 39|8@0+ (1,0) [0|255] "unitless"  GENERIC
 SG_ ARM_GWNMProxy : 47|8@0+ (1,0) [0|255] "unitless"  GENERIC
 SG_ ARM_AutoSarNMReserved4 : 63|8@0+ (1,0) [0|255] "unitless"  GENERIC
 SG_ ARM_AutoSarNMReserved3 : 55|8@0+ (1,0) [0|255] "unitless"  GENERIC
 SG_ ARM_AutoSarNMReserved2 : 31|8@0+ (1,0) [0|255] "unitless"  GENERIC
 SG_ ARM_AutoSarNMReserved1 : 23|8@0+ (1,0) [0|255] "unitless"  GENERIC
 SG_ ARM_AutoSarNMNodeId : 15|8@0+ (1,0) [0|255] "unitless"  GENERIC
 SG_ ARM_AutoSarNMControl : 7|8@0+ (1,0) [0|255] "unitless"  GENERIC

BO_ 1885 TesterPhysicalResARM: 8 ARM
 SG_ TesterPhysicalResARM : 7|64@0+ (1,0) [0|1.84467E+019] "unitless"  TSTR

BO_ 1877 TesterPhysicalReqARM: 8 TSTR
 SG_ TesterPhysicalReqARM : 7|64@0+ (1,0) [0|1.84467E+019] "unitless"  ARM

BO_ 2610049240 OTAPhysGWM_ECGtoRACM: 8 GWM
 SG_ OTAPhysGWM_ECGtoRACM : 7|29@0+ (1,0) [0|536870911] "unitless"  RACM_RCIM

BO_ 2610126988 OTAPhysRACMtoGWM_ECG: 8 RACM_RCIM
 SG_ OTAPhysRACMtoGWM_ECG : 7|29@0+ (1,0) [0|536870911] "unitless"  GWM

BO_ 2611097816 PARSEDPhysGWM_ECGtoRACM: 8 GWM
 SG_ PARSEDPhysGWM_ECGtoRACM : 7|29@0+ (1,0) [0|536870911] "unitless"  RACM_RCIM

BO_ 2611175564 PARSEDPhysRACMtoGWM_ECG: 8 RACM_RCIM
 SG_ PARSEDPhysRACMtoGWM_ECG : 7|29@0+ (1,0) [0|536870911] "unitless"  GWM

BO_ 2612146392 PARSEDPushFcGWM_ECGtoRACM: 8 GWM
 SG_ PARSEDPushFcGWM_ECGtoRACM : 7|29@0+ (1,0) [0|536870911] "unitless"  RACM_RCIM

BO_ 2612224140 PARSEDPushRACMtoGWM_ECG: 8 RACM_RCIM
 SG_ PARSEDPushRACMtoGWM_ECG : 7|29@0+ (1,0) [0|536870911] "unitless"  GWM

BO_ 2613194968 SymKeyPhysGWM_ECGtoRACM: 8 GWM
 SG_ SymKeyPhysGWM_ECGtoRACM : 7|29@0+ (1,0) [0|536870911] "unitless"  RACM_RCIM

BO_ 2613272716 SymKeyPhysRACMtoGWM_ECG: 8 RACM_RCIM
 SG_ SymKeyPhysRACMtoGWM_ECG : 7|29@0+ (1,0) [0|536870911] "unitless"  GWM

BO_ 1212 Body_Info_19_HS3: 8 GWM
 SG_ PersPrfl_D_Stat : 39|3@0+ (1,0) [0|7] "SED"  APIM,APIM_CDC,APIM_CIM
 SG_ PersDgtlKey4_D_Stat : 31|8@0+ (1,0) [0|255] "SED"  APIM,APIM_CDC,APIM_CIM
 SG_ PersDgtlKey3_D_Stat : 23|8@0+ (1,0) [0|255] "SED"  APIM,APIM_CDC,APIM_CIM
 SG_ PersDgtlKey2_D_Stat : 15|8@0+ (1,0) [0|255] "SED"  APIM,APIM_CDC,APIM_CIM
 SG_ PersDgtlKey1_D_Stat : 7|8@0+ (1,0) [0|255] "SED"  APIM,APIM_CDC,APIM_CIM

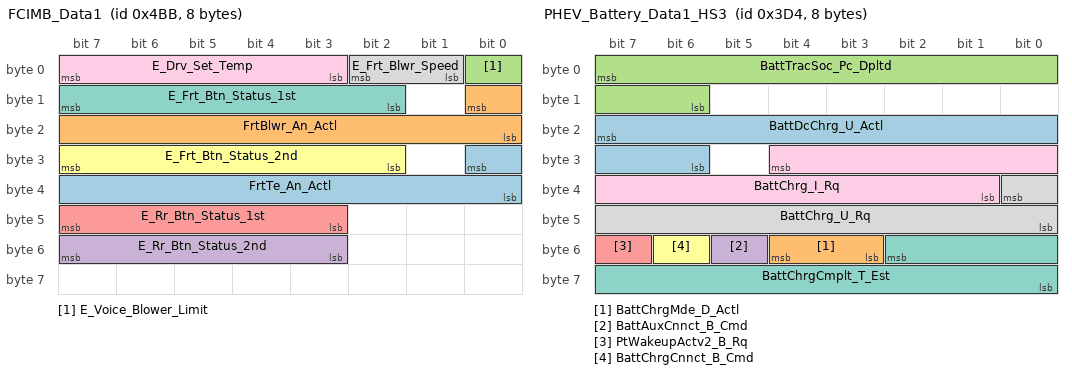
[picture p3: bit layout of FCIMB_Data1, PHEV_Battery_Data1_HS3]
BO_ 1211 FCIMB_Data1: 8 FCIMB
 SG_ FrtTe_An_Actl : 24|9@0+ (1,0) [0|510] "degrees"  GWM
 SG_ FrtBlwr_An_Actl : 8|9@0+ (1,0) [0|510] "degrees"  GWM
 SG_ E_Voice_Blower_Limit : 0|1@0+ (1,0) [0|1] "SED"  GWM
 SG_ E_Rr_Btn_Status_2nd : 55|5@0+ (1,0) [0|31] "SED"  GWM
 SG_ E_Rr_Btn_Status_1st : 47|5@0+ (1,0) [0|31] "SED"  GWM
 SG_ E_Frt_Btn_Status_2nd : 31|6@0+ (1,0) [0|63] "SED"  GWM
 SG_ E_Frt_Btn_Status_1st : 15|6@0+ (1,0) [0|63] "SED"  GWM
 SG_ E_Frt_Blwr_Speed : 2|2@0+ (1,0) [0|3] "SED"  GWM
 SG_ E_Drv_Set_Temp : 7|5@0+ (1,0) [0|31] "SED"  GWM

BO_ 509 Cluster_Info_2: 8 IPC
 SG_ TrakAppl_D_Stat : 7|3@0+ (1,0) [0|7] "SED"  APIM,APIM_CISM,GWM

BO_ 980 PHEV_Battery_Data1_HS3: 8 GWM
 SG_ BattDcChrg_U_Actl : 23|10@0+ (0.5,0) [0|510.5] "volt" Vector__XXX
 SG_ BattChrgMde_D_Actl : 52|2@0+ (1,0) [0|3] "SED" Vector__XXX
 SG_ BattTracSoc_Pc_Dpltd : 7|10@0+ (0.1,0) [0|102.3] "percent"  APIM_CDC,APIM,APIM_CIM,APIM_CISM
 SG_ BattAuxCnnct_B_Cmd : 53|1@0+ (1,0) [0|1] "SED" Vector__XXX
 SG_ PtWakeupActv2_B_Rq : 55|1@0+ (1,0) [0|1] "SED" Vector__XXX
 SG_ BattChrgCnnct_B_Cmd : 54|1@0+ (1,0) [0|1] "SED" Vector__XXX
 SG_ BattChrgCmplt_T_Est : 50|11@0+ (1,0) [0|2047] "minute" Vector__XXX
 SG_ BattChrg_U_Rq : 32|9@0+ (1,0) [0|511] "volt" Vector__XXX
 SG_ BattChrg_I_Rq : 28|12@0+ (0.1,0) [0|409.5] "ampere" Vector__XXX

BO_ 1310 GWM_Network_MgmtM_HS3: 8 GWM
 SG_ GWM_Network_Mgmt_HS3 : 7|64@0+ (1,0) [0|1.84467440737096E+019] "unitless"  GENERIC

BO_ 1304 RACM_REM3_Network_MgmtM: 8 RACM_RCIM
 SG_ RACM_REM3_Network_Mgmt : 7|64@0+ (1,0) [0|1.84467440737096E+019] "unitless"  GENERIC

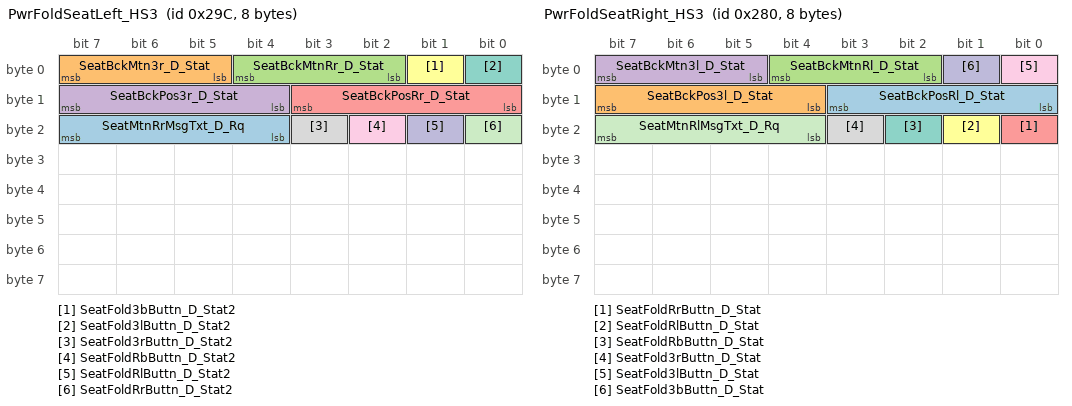
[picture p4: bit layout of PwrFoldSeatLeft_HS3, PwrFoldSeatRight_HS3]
BO_ 668 PwrFoldSeatLeft_HS3: 8 GWM
 SG_ SeatMtnRrMsgTxt_D_Rq : 23|4@0+ (1,0) [0|15] "SED"  APIM_CDC,APIM,APIM_CIM,APIM_CISM,IPC
 SG_ SeatBckMtn3r_D_Stat : 7|3@0+ (1,0) [0|7] "SED" Vector__XXX
 SG_ SeatBckMtnRr_D_Stat : 4|3@0+ (1,0) [0|7] "SED" Vector__XXX
 SG_ SeatBckPos3r_D_Stat : 15|4@0+ (1,0) [0|15] "SED" Vector__XXX
 SG_ SeatBckPosRr_D_Stat : 11|4@0+ (1,0) [0|15] "SED" Vector__XXX
 SG_ SeatFold3bButtn_D_Stat2 : 1|1@0+ (1,0) [0|1] "SED" Vector__XXX
 SG_ SeatFold3lButtn_D_Stat2 : 0|1@0+ (1,0) [0|1] "SED" Vector__XXX
 SG_ SeatFold3rButtn_D_Stat2 : 19|1@0+ (1,0) [0|1] "SED" Vector__XXX
 SG_ SeatFoldRbButtn_D_Stat2 : 18|1@0+ (1,0) [0|1] "SED" Vector__XXX
 SG_ SeatFoldRlButtn_D_Stat2 : 17|1@0+ (1,0) [0|1] "SED" Vector__XXX
 SG_ SeatFoldRrButtn_D_Stat2 : 16|1@0+ (1,0) [0|1] "SED" Vector__XXX

BO_ 640 PwrFoldSeatRight_HS3: 8 GWM
 SG_ SeatBckPosRl_D_Stat : 11|4@0+ (1,0) [0|15] "SED" Vector__XXX
 SG_ SeatBckPos3l_D_Stat : 15|4@0+ (1,0) [0|15] "SED" Vector__XXX
 SG_ SeatBckMtnRl_D_Stat : 4|3@0+ (1,0) [0|7] "SED" Vector__XXX
 SG_ SeatBckMtn3l_D_Stat : 7|3@0+ (1,0) [0|7] "SED" Vector__XXX
 SG_ SeatFoldRrButtn_D_Stat : 16|1@0+ (1,0) [0|1] "SED" Vector__XXX
 SG_ SeatFoldRlButtn_D_Stat : 17|1@0+ (1,0) [0|1] "SED" Vector__XXX
 SG_ SeatFoldRbButtn_D_Stat : 18|1@0+ (1,0) [0|1] "SED" Vector__XXX
 SG_ SeatFold3rButtn_D_Stat : 19|1@0+ (1,0) [0|1] "SED" Vector__XXX
 SG_ SeatFold3lButtn_D_Stat : 0|1@0+ (1,0) [0|1] "SED" Vector__XXX
 SG_ SeatFold3bButtn_D_Stat : 1|1@0+ (1,0) [0|1] "SED" Vector__XXX
 SG_ SeatMtnRlMsgTxt_D_Rq : 23|4@0+ (1,0) [0|15] "SED"  APIM_CDC,APIM,APIM_CIM,APIM_CISM,IPC

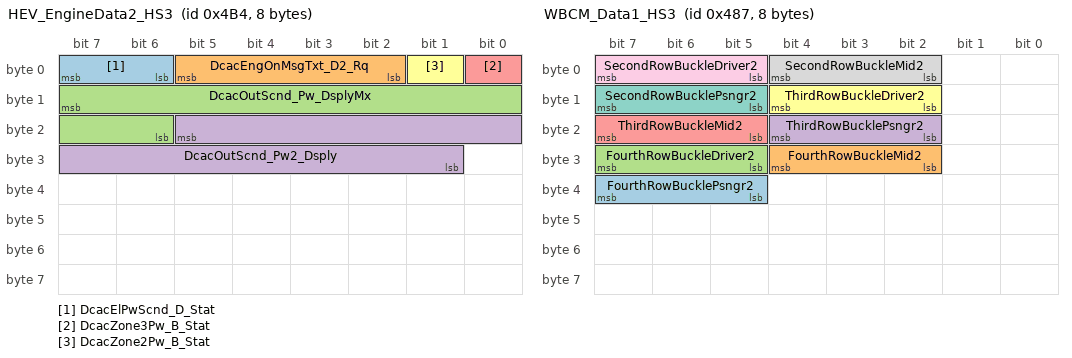
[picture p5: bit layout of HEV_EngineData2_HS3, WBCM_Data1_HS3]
BO_ 1204 HEV_EngineData2_HS3: 8 GWM
 SG_ DcacElPwScnd_D_Stat : 7|2@0+ (1,0) [0|3] "SED"  APIM_CDC,APIM,APIM_CIM
 SG_ DcacEngOnMsgTxt_D2_Rq : 5|4@0+ (1,0) [0|15] "SED"  APIM_CDC,APIM,APIM_CIM
 SG_ DcacOutScnd_Pw_DsplyMx : 15|10@0+ (10,0) [0|10220] "watts"  APIM_CDC,APIM,APIM_CIM
 SG_ DcacOutScnd_Pw2_Dsply : 21|13@0+ (1,0) [0|8189] "watts"  APIM_CDC,APIM,APIM_CIM
 SG_ DcacZone3Pw_B_Stat : 0|1@0+ (1,0) [0|1] "SED"  APIM_CDC,APIM,APIM_CIM
 SG_ DcacZone2Pw_B_Stat : 1|1@0+ (1,0) [0|1] "SED"  APIM_CDC,APIM,APIM_CIM

BO_ 826 Memory_Sw_StatM_HS3: 8 GWM
 SG_ Memory_3_Sw_Stat : 4|1@0+ (1,0) [0|1] "SED" Vector__XXX
 SG_ Memory_2_Sw_Stat : 5|1@0+ (1,0) [0|1] "SED" Vector__XXX
 SG_ Memory_1_Sw_Stat : 6|1@0+ (1,0) [0|1] "SED" Vector__XXX
 SG_ Mirror_Manual_Override : 0|1@0+ (1,0) [0|1] "SED"  APIM_CISM,APIM_CIM

BO_ 1159 WBCM_Data1_HS3: 8 GWM
 SG_ FourthRowBucklePsngr2 : 39|3@0+ (1,0) [0|7] "SED"  IPC
 SG_ FourthRowBuckleMid2 : 28|3@0+ (1,0) [0|7] "SED"  IPC
 SG_ FourthRowBuckleDriver2 : 31|3@0+ (1,0) [0|7] "SED"  IPC
 SG_ ThirdRowBucklePsngr2 : 20|3@0+ (1,0) [0|7] "SED"  IPC
 SG_ ThirdRowBuckleMid2 : 23|3@0+ (1,0) [0|7] "SED"  IPC
 SG_ ThirdRowBuckleDriver2 : 12|3@0+ (1,0) [0|7] "SED"  IPC
 SG_ SecondRowBucklePsngr2 : 15|3@0+ (1,0) [0|7] "SED"  IPC
 SG_ SecondRowBuckleMid2 : 4|3@0+ (1,0) [0|7] "SED"  IPC
 SG_ SecondRowBuckleDriver2 : 7|3@0+ (1,0) [0|7] "SED"  IPC

BO_ 1258 IPMB_Data1_HS3: 8 GWM
 SG_ TrlrCamraCalib_D_Stat : 3|2@0+ (1,0) [0|3] "SED"  APIM_CDC,APIM,APIM_CIM,APIM_CISM
 SG_ TrlrCamraView_D_Stat : 7|4@0+ (1,0) [0|15] "SED"  APIM_CDC,APIM,APIM_CIM,APIM_CISM

BO_ 648 APIM_Send_Signals_5: 8 APIM
 SG_ TrlrCamraCalib_D_Rq : 31|2@0+ (1,0) [0|3] "SED"  GWM
 SG_ HitchToTrlrBox_L_Actl : 23|7@0+ (25,0) [0|3175] "millimeter"  GWM
 SG_ TrlrWidth_L_Actl : 15|7@0+ (25,0) [0|3175] "millimeter"  GWM
 SG_ TrlrCamraHght_L_Actl : 7|8@0+ (25,0) [0|6375] "millimeter"  GWM

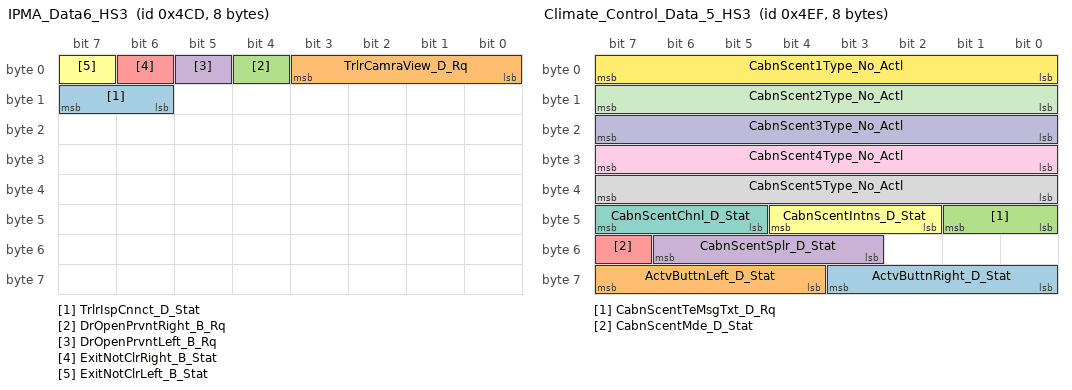
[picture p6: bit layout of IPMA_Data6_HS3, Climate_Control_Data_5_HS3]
BO_ 1229 IPMA_Data6_HS3: 8 GWM
 SG_ TrlrIspCnnct_D_Stat : 15|2@0+ (1,0) [0|3] "SED"  APIM_CDC,APIM,APIM_CIM,APIM_CISM
 SG_ TrlrCamraView_D_Rq : 3|4@0+ (1,0) [0|15] "SED" Vector__XXX
 SG_ DrOpenPrvntRight_B_Rq : 4|1@0+ (1,0) [0|1] "SED" Vector__XXX
 SG_ DrOpenPrvntLeft_B_Rq : 5|1@0+ (1,0) [0|1] "SED" Vector__XXX
 SG_ ExitNotClrRight_B_Stat : 6|1@0+ (1,0) [0|1] "SED" Vector__XXX
 SG_ ExitNotClrLeft_B_Stat : 7|1@0+ (1,0) [0|1] "SED" Vector__XXX

BO_ 1246 TRM_Data1: 8 TRM_ITRM
 SG_ TrlrBrkCtl2_B_Falt : 11|1@0+ (1,0) [0|1] "SED"  IPC,GWM
 SG_ TrlrBrkCtl2BFalt_No_Cnt : 15|4@0+ (1,0) [0|15] "unitless"  IPC,GWM
 SG_ TrlrBrkCtl2BFalt_No_Cs : 7|8@0+ (1,0) [0|255] "unitless"  IPC,GWM

BO_ 1157 BTT5GLH_Data1_HS3: 8 GWM
 SG_ SodAltLeft_D2_StatAft : 7|2@0+ (1,0) [0|3] "SED"  APIM_CDC,APIM,APIM_CIM,APIM_CISM

BO_ 1158 BTT5GRH_Data1_HS3: 8 GWM
 SG_ SodAltRight_D2_StatAft : 7|2@0+ (1,0) [0|3] "SED"  APIM_CDC,APIM,APIM_CIM,APIM_CISM

BO_ 1208 APIM_Send_Signals_4: 8 APIM
 SG_ StopStrtImccSel_B_Rq : 12|1@0+ (1,0) [0|1] "SED"  GWM
 SG_ StopStrtImccTxt_D_Stat : 15|3@0+ (1,0) [0|7] "SED"  GWM
 SG_ StopStrtImccSel_B_Falt : 0|1@0+ (1,0) [0|1] "SED"  GWM
 SG_ Btt_L2_Actl2 : 7|7@0+ (0.1,5.1) [5.1|17.6] "meter"  GWM

BO_ 1266 APIM_Send_Signals_8: 8 APIM_CISM
 SG_ CabnScentCalbType_No_Rq : 7|8@0+ (1,0) [0|0] "SED"  GWM
 SG_ CabnScentCalibVal_No_Rq : 23|16@0+ (1,0) [0|65535] "unitless"  GWM

BO_ 1263 Climate_Control_Data_5_HS3: 8 GWM
 SG_ ActvButtnRight_D_Stat : 59|4@0+ (1,0) [0|15] "SED"  APIM,APIM_CDC,APIM_CIM,APIM_CISM
 SG_ ActvButtnLeft_D_Stat : 63|4@0+ (1,0) [0|15] "SED"  APIM,APIM_CDC,APIM_CIM,APIM_CISM
 SG_ CabnScentTeMsgTxt_D_Rq : 41|2@0+ (1,0) [0|3] "SED"  APIM_CDC,APIM,APIM_CIM,APIM_CISM
 SG_ CabnScentSplr_D_Stat : 54|4@0+ (1,0) [0|15] "SED"  APIM_CDC,APIM,APIM_CIM,APIM_CISM
 SG_ CabnScentMde_D_Stat : 55|1@0+ (1,0) [0|1] "SED"  APIM_CDC,APIM,APIM_CIM,APIM_CISM
 SG_ CabnScentIntns_D_Stat : 44|3@0+ (1,0) [0|7] "SED"  APIM_CDC,APIM,APIM_CIM,APIM_CISM
 SG_ CabnScentChnl_D_Stat : 47|3@0+ (1,0) [0|7] "SED"  APIM_CDC,APIM,APIM_CIM,APIM_CISM
 SG_ CabnScent5Type_No_Actl : 39|8@0+ (1,0) [0|255] "unitless"  APIM_CDC,APIM,APIM_CIM,APIM_CISM
 SG_ CabnScent4Type_No_Actl : 31|8@0+ (1,0) [0|255] "unitless"  APIM_CDC,APIM,APIM_CIM,APIM_CISM
 SG_ CabnScent3Type_No_Actl : 23|8@0+ (1,0) [0|255] "unitless"  APIM_CDC,APIM,APIM_CIM,APIM_CISM
 SG_ CabnScent2Type_No_Actl : 15|8@0+ (1,0) [0|255] "unitless"  APIM_CDC,APIM,APIM_CIM,APIM_CISM
 SG_ CabnScent1Type_No_Actl : 7|8@0+ (1,0) [0|255] "unitless"  APIM_CDC,APIM,APIM_CIM,APIM_CISM

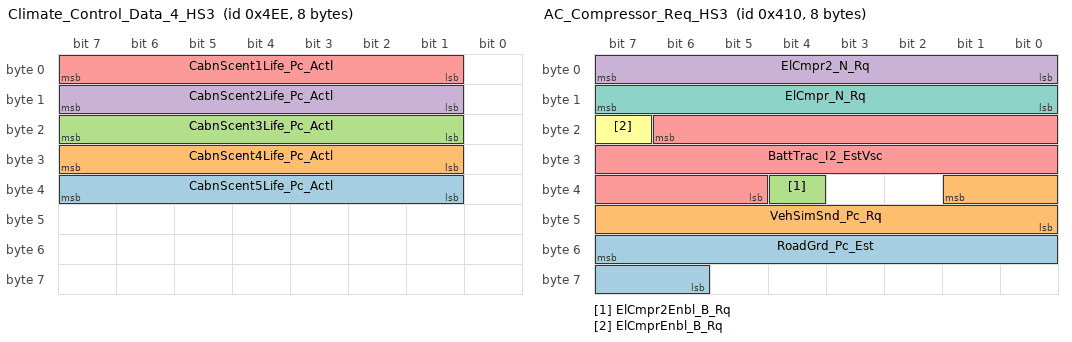
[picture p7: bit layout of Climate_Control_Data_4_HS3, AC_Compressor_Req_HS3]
BO_ 1262 Climate_Control_Data_4_HS3: 8 GWM
 SG_ CabnScent5Life_Pc_Actl : 39|7@0+ (1,0) [0|127] "unitless"  APIM_CDC,APIM,APIM_CIM,APIM_CISM
 SG_ CabnScent4Life_Pc_Actl : 31|7@0+ (1,0) [0|127] "unitless"  APIM_CDC,APIM,APIM_CIM,APIM_CISM
 SG_ CabnScent3Life_Pc_Actl : 23|7@0+ (1,0) [0|127] "unitless"  APIM_CDC,APIM,APIM_CIM,APIM_CISM
 SG_ CabnScent2Life_Pc_Actl : 15|7@0+ (1,0) [0|127] "unitless"  APIM_CDC,APIM,APIM_CIM,APIM_CISM
 SG_ CabnScent1Life_Pc_Actl : 7|7@0+ (1,0) [0|127] "unitless"  APIM_CDC,APIM,APIM_CIM,APIM_CISM

BO_ 667 APIM_NFAM_Word_Rx_HS3: 8 GWM
 SG_ APIM_NFAM_Word_Rx : 7|64@0+ (1,0) [0|1.84467440737096E+019] "unitless"  APIM,APIM_CISM,APIM_CIM

BO_ 659 APIM_NFAM_Word_Tx: 8 APIM_CIM
 SG_ APIM_NFAM_Word_Tx : 7|64@0+ (1,0) [0|1.84467440737096E+019] "unitless"  GWM

BO_ 645 ECG_Data5_HS3: 8 GWM
 SG_ VehImpactCode_No2_Actl : 7|16@0+ (1,0) [0|65535] "unitless"  APIM_CDC,APIM,APIM_CIM,APIM_CISM

BO_ 1040 AC_Compressor_Req_HS3: 8 GWM
 SG_ RoadGrd_Pc_Est : 55|10@0+ (0.2,-102) [-102|102.4] "percent" Vector__XXX
 SG_ VehSimSnd_Pc_Rq : 33|10@0+ (0.2,-102.2) [-102.2|102.4] "percent"  APIM_CISM,ACM,APIM_CIM
 SG_ ElCmpr2Enbl_B_Rq : 36|1@0+ (1,0) [0|1] "SED" Vector__XXX
 SG_ ElCmpr2_N_Rq : 7|8@0+ (50,0) [0|12750] "RPM" Vector__XXX
 SG_ BattTrac_I2_EstVsc : 22|18@0+ (0.05,-6553.52) [-6553.52|6553.53] "ampere" Vector__XXX
 SG_ ElCmprEnbl_B_Rq : 23|1@0+ (1,0) [0|1] "SED" Vector__XXX
 SG_ ElCmpr_N_Rq : 15|8@0+ (50,0) [0|12750] "RPM" Vector__XXX

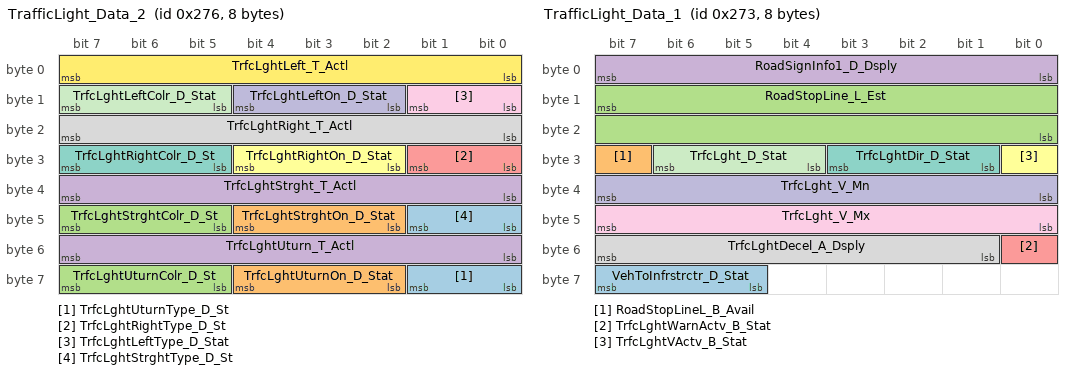
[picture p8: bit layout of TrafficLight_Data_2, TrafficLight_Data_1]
BO_ 630 TrafficLight_Data_2: 8 APIM_CIM
 SG_ TrfcLghtUturnType_D_St : 57|2@0+ (1,0) [0|3] "SED"  IPC,GWM
 SG_ TrfcLghtUturnOn_D_Stat : 60|3@0+ (1,0) [0|7] "SED"  IPC,GWM
 SG_ TrfcLghtUturnColr_D_St : 63|3@0+ (1,0) [0|7] "SED"  IPC,GWM
 SG_ TrfcLghtUturn_T_Actl : 55|8@0+ (1,0) [0|253] "second"  IPC,GWM
 SG_ TrfcLghtRightType_D_St : 25|2@0+ (1,0) [0|3] "SED"  IPC,GWM
 SG_ TrfcLghtRightOn_D_Stat : 28|3@0+ (1,0) [0|7] "SED"  IPC,GWM
 SG_ TrfcLghtRightColr_D_St : 31|3@0+ (1,0) [0|7] "SED"  IPC,GWM
 SG_ TrfcLghtRight_T_Actl : 23|8@0+ (1,0) [0|253] "second"  IPC,GWM
 SG_ TrfcLghtLeftType_D_Stat : 9|2@0+ (1,0) [0|3] "SED"  IPC,GWM
 SG_ TrfcLghtLeftOn_D_Stat : 12|3@0+ (1,0) [0|7] "SED"  IPC,GWM
 SG_ TrfcLghtLeftColr_D_Stat : 15|3@0+ (1,0) [0|7] "SED"  IPC,GWM
 SG_ TrfcLghtLeft_T_Actl : 7|8@0+ (1,0) [0|253] "second"  IPC,GWM
 SG_ TrfcLghtStrghtType_D_St : 41|2@0+ (1,0) [0|3] "SED"  IPC,GWM
 SG_ TrfcLghtStrghtOn_D_Stat : 44|3@0+ (1,0) [0|7] "SED"  IPC,GWM
 SG_ TrfcLghtStrghtColr_D_St : 47|3@0+ (1,0) [0|7] "SED"  IPC,GWM
 SG_ TrfcLghtStrght_T_Actl : 39|8@0+ (1,0) [0|253] "second"  IPC,GWM

BO_ 627 TrafficLight_Data_1: 8 APIM_CIM
 SG_ VehToInfrstrctr_D_Stat : 63|3@0+ (1,0) [0|7] "SED"  IPC,GWM
 SG_ RoadStopLineL_B_Avail : 31|1@0+ (1,0) [0|1] "SED"  IPC,GWM
 SG_ RoadStopLine_L_Est : 15|16@0+ (1,0) [0|65533] "cm"  IPC,GWM
 SG_ RoadSignInfo1_D_Dsply : 7|8@0+ (1,0) [0|255] "SED"  IPC,GWM
 SG_ TrfcLghtWarnActv_B_Stat : 48|1@0+ (1,0) [0|1] "SED"  IPC,GWM
 SG_ TrfcLghtVActv_B_Stat : 24|1@0+ (1,0) [0|1] "SED"  IPC,GWM
 SG_ TrfcLghtDir_D_Stat : 27|3@0+ (1,0) [0|7] "SED"  IPC,GWM
 SG_ TrfcLghtDecel_A_Dsply : 55|7@0+ (1,0) [0|125] "km/hour"  IPC,GWM
 SG_ TrfcLght_V_Mx : 47|8@0+ (1,0) [0|253] "km/hour"  IPC,GWM
 SG_ TrfcLght_V_Mn : 39|8@0+ (1,0) [0|253] "km/hour"  IPC,GWM
 SG_ TrfcLght_D_Stat : 30|3@0+ (1,0) [0|7] "SED"  IPC,GWM

BO_ 874 RemoteClimate_Data_HS3: 8 FCIMB
 SG_ E_Rr_Btn_Status_2nd : 55|5@0+ (1,0) [0|31] "SED"  APIM_CDC,APIM,APIM_CIM,GWM,APIM_CISM
 SG_ E_Rr_Btn_Status_1st : 47|5@0+ (1,0) [0|31] "SED"  APIM_CDC,APIM,APIM_CIM,GWM,APIM_CISM
 SG_ E_Frt_Btn_Status_2nd : 39|6@0+ (1,0) [0|63] "SED"  APIM_CDC,APIM,APIM_CIM,GWM,APIM_CISM
 SG_ E_Frt_Btn_Status_1st : 30|6@0+ (1,0) [0|63] "SED"  APIM_CDC,APIM,APIM_CIM,GWM,APIM_CISM

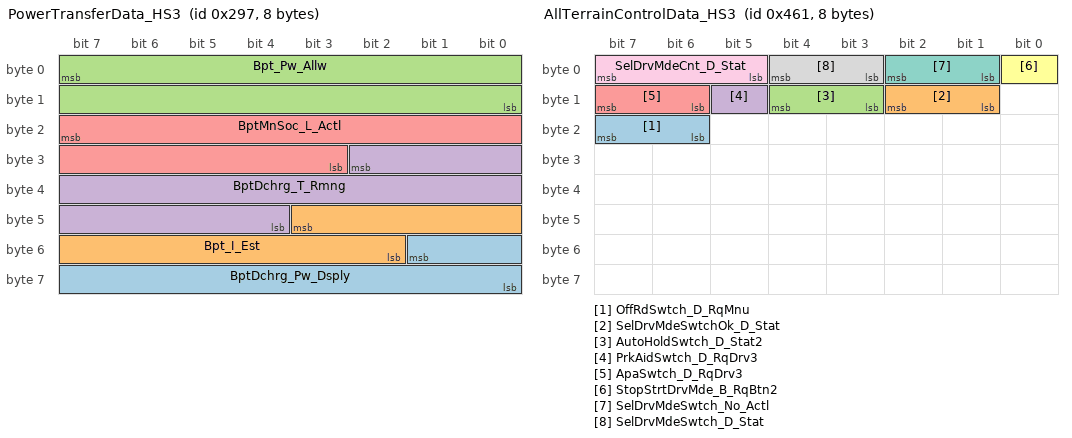
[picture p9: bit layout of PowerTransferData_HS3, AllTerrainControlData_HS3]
BO_ 663 PowerTransferData_HS3: 8 GWM
 SG_ BptDchrg_Pw_Dsply : 49|10@0+ (0.1,0) [0|102.1] "kilowatt"  APIM_CDC,APIM,APIM_CIM,APIM_CISM
 SG_ Bpt_I_Est : 43|10@0+ (1,-510) [-510|511] "ampere"  APIM_CDC,APIM_CIM,APIM_CISM
 SG_ Bpt_Pw_Allw : 7|16@0+ (0.1,0) [0|6553.3] "kilowatt"  APIM_CDC,APIM,APIM_CIM,APIM_CISM
 SG_ BptDchrg_T_Rmng : 26|15@0+ (1,0) [0|32765] "minute"  APIM_CDC,APIM,APIM_CIM,APIM_CISM
 SG_ BptMnSoc_L_Actl : 23|13@0+ (0.1,0) [0|818.9] "kilometer"  APIM_CDC,APIM,APIM_CIM,APIM_CISM

BO_ 1161 HEV_Data_Monitor_22_HS3: 8 GWM
 SG_ BattTracUMxArry_No_Actl : 52|5@0+ (1,0) [0|30] "unitless" Vector__XXX
 SG_ BattTracCellUMx_No_Actl : 63|8@0+ (1,0) [0|253] "unitless" Vector__XXX
 SG_ BattChrgUMx_B_Falt : 53|1@0+ (1,0) [0|1] "SED" Vector__XXX
 SG_ BattTracCellUMn_No_Actl : 15|8@0+ (1,0) [0|253] "unitless" Vector__XXX
 SG_ BattTracCellCnt_No_Actl : 7|8@0+ (1,0) [0|253] "unitless" Vector__XXX
 SG_ BattChrgIsltn_B_Falt : 47|1@0+ (1,0) [0|1] "SED" Vector__XXX
 SG_ BattTracCellDiff_B_Falt : 43|1@0+ (1,0) [0|1] "SED" Vector__XXX
 SG_ BattChrgSocMx_B_Falt : 44|1@0+ (1,0) [0|1] "SED"  APIM_CDC,APIM,APIM_CIM,APIM_CISM
 SG_ BattChrgSocMn_B_Falt : 45|1@0+ (1,0) [0|1] "SED"  APIM_CDC,APIM,APIM_CIM,APIM_CISM
 SG_ BattChrgSocErrtc_B_Falt : 46|1@0+ (1,0) [0|1] "SED" Vector__XXX
 SG_ BattTracUMx_B_Falt : 54|1@0+ (1,0) [0|1] "SED" Vector__XXX
 SG_ BattTracUMn_B_Falt : 55|1@0+ (1,0) [0|1] "SED" Vector__XXX
 SG_ BattTracTeMx_No_Actl : 39|8@0+ (1,0) [0|253] "unitless" Vector__XXX
 SG_ BattTracTeMx_B_Falt : 40|1@0+ (1,0) [0|1] "SED" Vector__XXX
 SG_ BattTracTeMn_No_Actl : 31|8@0+ (1,0) [0|253] "unitless" Vector__XXX
 SG_ BattTracTeDelta_B_Falt : 41|1@0+ (1,0) [0|1] "SED" Vector__XXX
 SG_ BattTracTeCnt_No_Actl : 23|8@0+ (1,0) [0|253] "unitless" Vector__XXX
 SG_ BattTracSoftware_B_Falt : 42|1@0+ (1,0) [0|1] "SED" Vector__XXX

BO_ 1121 AllTerrainControlData_HS3: 8 GWM
 SG_ OffRdSwtch_D_RqMnu : 23|2@0+ (1,0) [0|3] "SED"  APIM_CDC,APIM,APIM_CIM,APIM_CISM
 SG_ SelDrvMdeSwtchOk_D_Stat : 10|2@0+ (1,0) [0|3] "SED" Vector__XXX
 SG_ AutoHoldSwtch_D_Stat2 : 12|2@0+ (1,0) [0|3] "SED" Vector__XXX
 SG_ PrkAidSwtch_D_RqDrv3 : 13|1@0+ (1,0) [0|1] "SED" Vector__XXX
 SG_ ApaSwtch_D_RqDrv3 : 15|2@0+ (1,0) [0|3] "SED" Vector__XXX
 SG_ StopStrtDrvMde_B_RqBtn2 : 0|1@0+ (1,0) [0|1] "SED" Vector__XXX
 SG_ SelDrvMdeSwtch_No_Actl : 2|2@0+ (1,0) [0|3] "unitless" Vector__XXX
 SG_ SelDrvMdeSwtch_D_Stat : 4|2@0+ (1,0) [0|3] "SED" Vector__XXX
 SG_ SelDrvMdeCnt_D_Stat : 7|3@0+ (1,0) [0|7] "Counts" Vector__XXX

BO_ 669 Pass_Dr_Stat2_HS3: 8 GWM
 SG_ DrHandleOuterRr_D_Stat : 4|3@0+ (1,0) [0|7] "SED"  APIM_CDC,APIM_CIM,IPC
 SG_ DrHandleOuterFr_D_Stat : 7|3@0+ (1,0) [0|7] "SED"  APIM_CDC,APIM_CIM,IPC

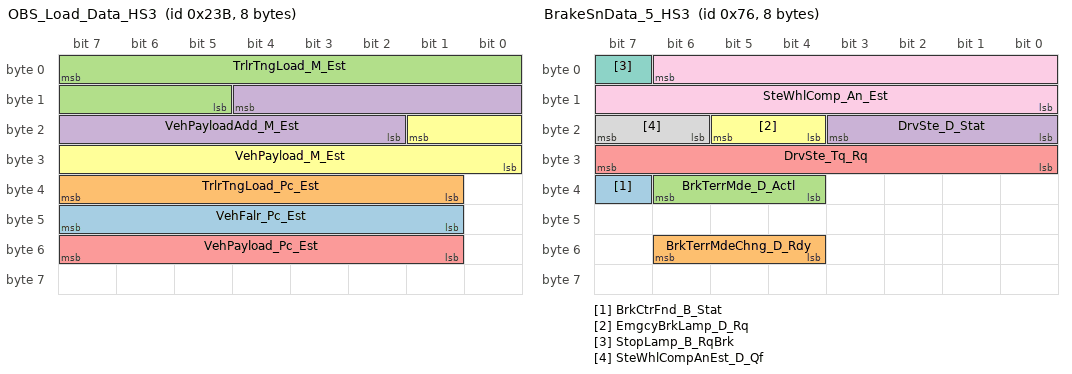
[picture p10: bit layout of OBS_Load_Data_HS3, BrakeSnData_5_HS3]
BO_ 571 OBS_Load_Data_HS3: 8 GWM
 SG_ VehFalr_Pc_Est : 47|7@0+ (1,0) [0|125] "percent"  APIM_CDC,APIM,APIM_CIM,APIM_CISM
 SG_ TrlrTngLoad_Pc_Est : 39|7@0+ (1,0) [0|125] "percent"  APIM_CDC,APIM,APIM_CIM,APIM_CISM
 SG_ TrlrTngLoad_M_Est : 7|11@0+ (10,-10240) [-10240|10210] "kilogram"  APIM_CDC,APIM,APIM_CIM,APIM_CISM
 SG_ VehPayloadAdd_M_Est : 12|11@0+ (5,-5115) [-5115|5110] "kilogram"  APIM_CDC,APIM,APIM_CIM,APIM_CISM
 SG_ VehPayload_Pc_Est : 55|7@0+ (1,0) [0|125] "percent"  APIM_CDC,APIM,APIM_CIM,APIM_CISM
 SG_ VehPayload_M_Est : 17|10@0+ (5,0) [0|5105] "kilogram"  APIM_CDC,APIM,APIM_CIM,APIM_CISM

BO_ 118 BrakeSnData_5_HS3: 8 GWM
 SG_ BrkCtrFnd_B_Stat : 39|1@0+ (1,0) [0|1] "SED" Vector__XXX
 SG_ BrkTerrMdeChng_D_Rdy : 54|3@0+ (1,0) [0|7] "SED" Vector__XXX
 SG_ BrkTerrMde_D_Actl : 38|3@0+ (1,0) [0|7] "SED" Vector__XXX
 SG_ DrvSte_D_Stat : 19|4@0+ (1,0) [0|15] "SED" Vector__XXX
 SG_ DrvSte_Tq_Rq : 31|8@0+ (0.0625,-8) [-8|7.8125] "Nm" Vector__XXX
 SG_ EmgcyBrkLamp_D_Rq : 21|2@0+ (1,0) [0|3] "SED" Vector__XXX
 SG_ StopLamp_B_RqBrk : 7|1@0+ (1,0) [0|1] "SED" Vector__XXX
 SG_ SteWhlCompAnEst_D_Qf : 23|2@0+ (1,0) [0|3] "SED"  APIM_CDC,APIM,APIM_CISM,APIM_CIM,IPC
 SG_ SteWhlComp_An_Est : 6|15@0+ (0.1,-1600) [-1600|1676.7] "degrees"  APIM_CDC,APIM,APIM_CISM,APIM_CIM,IPC

BO_ 868 Clmt_Button_Stat6_HS3: 8 GWM
 SG_ Rr_Blower_Indicate_Stat : 7|4@0+ (1,0) [0|15] "SED"  GENERIC

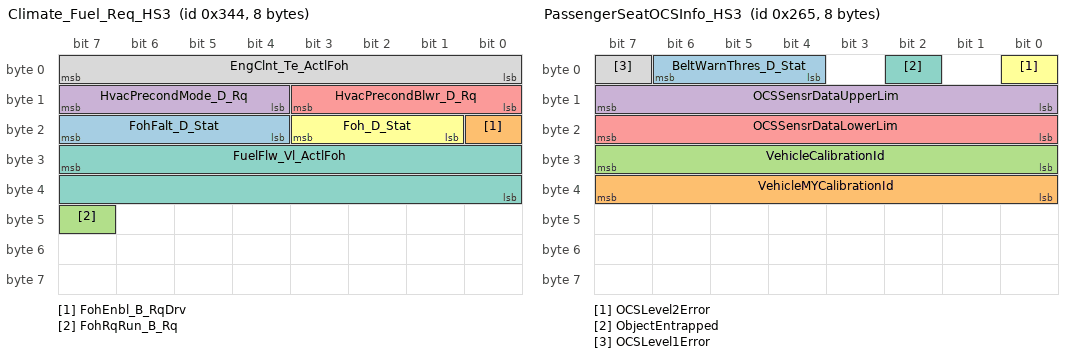
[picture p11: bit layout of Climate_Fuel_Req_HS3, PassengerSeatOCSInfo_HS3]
BO_ 836 Climate_Fuel_Req_HS3: 8 GWM
 SG_ FohFalt_D_Stat : 23|4@0+ (1,0) [0|15] "SED" Vector__XXX
 SG_ FohEnbl_B_RqDrv : 16|1@0+ (1,0) [0|1] "SED" Vector__XXX
 SG_ FohRqRun_B_Rq : 47|1@0+ (1,0) [0|1] "SED" Vector__XXX
 SG_ HvacPrecondMode_D_Rq : 15|4@0+ (1,0) [0|15] "SED" Vector__XXX
 SG_ HvacPrecondBlwr_D_Rq : 11|4@0+ (1,0) [0|15] "SED" Vector__XXX
 SG_ Foh_D_Stat : 19|3@0+ (1,0) [0|7] "SED" Vector__XXX
 SG_ FuelFlw_Vl_ActlFoh : 31|16@0+ (25,0) [0|1638375] "microlitre"  APIM_CDC,APIM,APIM_CISM,APIM_CIM,IPC
 SG_ EngClnt_Te_ActlFoh : 7|8@0+ (1,-50) [-50|204] "degC" Vector__XXX

BO_ 613 PassengerSeatOCSInfo_HS3: 8 GWM
 SG_ BeltWarnThres_D_Stat : 6|3@0+ (1,0) [0|7] "SED" Vector__XXX
 SG_ VehicleMYCalibrationId : 39|8@0+ (1,0) [0|254] "SED" Vector__XXX
 SG_ VehicleCalibrationId : 31|8@0+ (1,0) [0|254] "SED" Vector__XXX
 SG_ OCSSensrDataUpperLim : 15|8@0+ (1,0) [0|254] "SED" Vector__XXX
 SG_ OCSSensrDataLowerLim : 23|8@0+ (1,0) [0|254] "SED" Vector__XXX
 SG_ OCSLevel2Error : 0|1@0+ (1,0) [0|1] "SED" Vector__XXX
 SG_ ObjectEntrapped : 2|1@0+ (1,0) [0|1] "SED"  APIM_CDC,APIM_CIM,IPC
 SG_ OCSLevel1Error : 7|1@0+ (1,0) [0|1] "SED" Vector__XXX

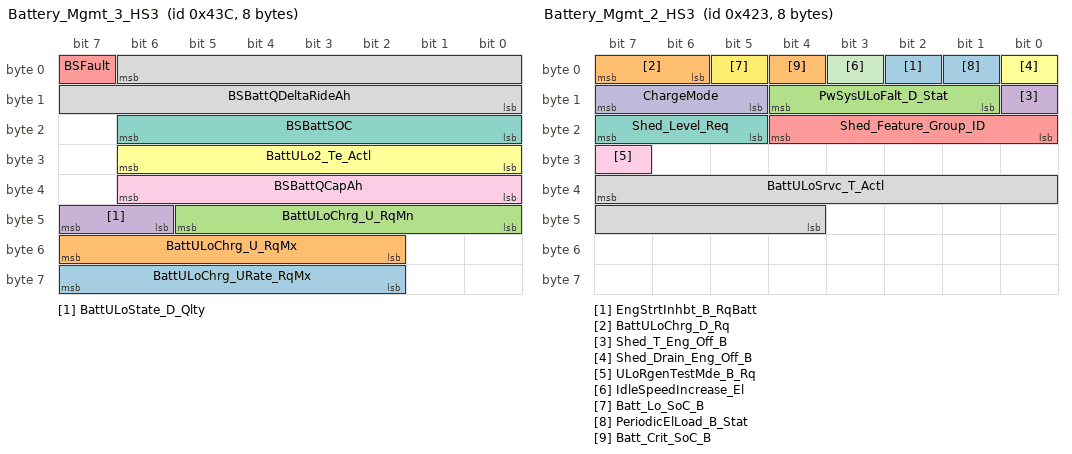
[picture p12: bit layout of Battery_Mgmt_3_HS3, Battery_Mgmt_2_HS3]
BO_ 1084 Battery_Mgmt_3_HS3: 8 GWM
 SG_ BattULoChrg_URate_RqMx : 63|6@0+ (0.1,0) [0|6.3] "volts/second" Vector__XXX
 SG_ BattULoChrg_U_RqMx : 55|6@0+ (0.1,10.6) [10.6|16.9] "volt" Vector__XXX
 SG_ BattULoChrg_U_RqMn : 45|6@0+ (0.1,10.6) [10.6|16.9] "volt" Vector__XXX
 SG_ BattULoState_D_Qlty : 47|2@0+ (1,0) [0|3] "SED" Vector__XXX
 SG_ BSFault : 7|1@0+ (1,0) [0|1] "SED" Vector__XXX
 SG_ BattULo2_Te_Actl : 30|7@0+ (1,-40) [-40|86] "degC" Vector__XXX
 SG_ BSBattSOC : 22|7@0+ (1,0) [0|127] "%"  APIM_CDC,APIM,APIM_CIM,APIM_CISM
 SG_ BSBattQDeltaRideAh : 6|15@0+ (0.0078125,-100) [-100|155.9921875] "ampere*hour" Vector__XXX
 SG_ BSBattQCapAh : 38|7@0+ (1,0) [0|127] "ampere*hour" Vector__XXX

BO_ 1059 Battery_Mgmt_2_HS3: 8 GWM
 SG_ EngStrtInhbt_B_RqBatt : 2|1@0+ (1,0) [0|1] "SED" Vector__XXX
 SG_ BattULoChrg_D_Rq : 7|2@0+ (1,0) [0|3] "SED" Vector__XXX
 SG_ PwSysULoFalt_D_Stat : 12|4@0+ (1,0) [0|15] "SED"  APIM_CDC,APIM_CIM,IPC
 SG_ Shed_T_Eng_Off_B : 8|1@0+ (1,0) [0|1] "SED"  APIM_CDC,APIM,APIM_CIM,APIM_CISM,TRM_ITRM
 SG_ Shed_Feature_Group_ID : 20|5@0+ (1,0) [0|31] "SED"  TRM_ITRM
 SG_ Shed_Drain_Eng_Off_B : 0|1@0+ (1,0) [0|1] "SED"  APIM_CDC,APIM,APIM_CIM,APIM_CISM,TRM_ITRM
 SG_ Shed_Level_Req : 23|3@0+ (1,0) [0|7] "SED"  APIM_CDC,APIM,APIM_CISM,TRM_ITRM,APIM_CIM,IPC
 SG_ BattULoSrvc_T_Actl : 39|12@0+ (1,0) [0|4095] "day" Vector__XXX
 SG_ ULoRgenTestMde_B_Rq : 31|1@0+ (1,0) [0|1] "SED" Vector__XXX
 SG_ ChargeMode : 15|3@0+ (1,0) [0|7] "SED" Vector__XXX
 SG_ IdleSpeedIncrease_El : 3|1@0+ (1,0) [0|1] "SED" Vector__XXX
 SG_ Batt_Lo_SoC_B : 5|1@0+ (1,0) [0|1] "SED"  APIM_CDC,APIM,APIM_CIM,APIM_CISM,TRM_ITRM,IPC
 SG_ PeriodicElLoad_B_Stat : 1|1@0+ (1,0) [0|1] "SED" Vector__XXX
 SG_ Batt_Crit_SoC_B : 4|1@0+ (1,0) [0|1] "SED"  APIM_CDC,APIM,APIM_CISM,TRM_ITRM,APIM_CIM,IPC

BO_ 131 Steering_Data_HS3: 8 GWM
 SG_ ElPwAsstSte_B_RqDactv : 7|1@0+ (1,0) [0|1] "SED" Vector__XXX
 SG_ HeadLghtHiCtrl_D_RqAhb : 43|3@0+ (1,0) [0|7] "SED" Vector__XXX
 SG_ AhbStat_B_Dsply : 33|1@0+ (1,0) [0|1] "SED"  APIM_CDC,APIM_CISM,APIM_CIM,IPC
 SG_ WiprFrontSwtch_D_Stat : 47|4@0+ (1,0) [0|15] "SED" Vector__XXX
 SG_ HeadLghtHiOn_B_StatAhb : 34|1@0+ (1,0) [0|1] "SED"  APIM_CDC,APIM,APIM_CISM,APIM_CIM,IPC
 SG_ HeadLghtHiFlash_D_Actl : 36|2@0+ (1,0) [0|3] "SED" Vector__XXX
 SG_ TjaButtnOnOffPress : 40|1@0+ (1,0) [0|1] "SED" Vector__XXX
 SG_ AccButtnGapTogglePress : 32|1@0+ (1,0) [0|1] "SED" Vector__XXX
 SG_ WiprFront_D_Stat : 3|4@0+ (1,0) [0|15] "SED"  APIM_CDC,APIM,APIM_CIM,APIM_CISM
 SG_ TurnLghtSwtch_D_Stat : 5|2@0+ (1,0) [0|3] "SED"  ARM,APIM_CDC,APIM,APIM_CISM,APIM_CIM,IPC
 SG_ LghtAmb_D_Sns : 15|3@0+ (1,0) [0|7] "SED" Vector__XXX
 SG_ AccButtnGapIncPress : 11|1@0+ (1,0) [0|1] "SED" Vector__XXX
 SG_ AccButtnGapDecPress : 12|1@0+ (1,0) [0|1] "SED" Vector__XXX
 SG_ AslButtnOnOffPress : 9|1@0+ (1,0) [0|1] "SED" Vector__XXX
 SG_ AslButtnOnOffCnclPress : 10|1@0+ (1,0) [0|1] "SED" Vector__XXX
 SG_ CcButtnOnPress : 37|1@0+ (1,0) [0|1] "SED" Vector__XXX
 SG_ CcButtnOnOffPress : 38|1@0+ (1,0) [0|1] "SED" Vector__XXX
 SG_ CcButtnOnOffCnclPress : 39|1@0+ (1,0) [0|1] "SED" Vector__XXX
 SG_ CcButtnOffPress : 24|1@0+ (1,0) [0|1] "SED" Vector__XXX
 SG_ CcAsllButtnResPress : 25|1@0+ (1,0) [0|1] "SED" Vector__XXX
 SG_ CcAslButtnSetPress : 26|1@0+ (1,0) [0|1] "SED" Vector__XXX
 SG_ CcAslButtnSetIncPress : 27|1@0+ (1,0) [0|1] "SED" Vector__XXX
 SG_ CcAslButtnSetDecPress : 28|1@0+ (1,0) [0|1] "SED" Vector__XXX
 SG_ CcAslButtnResIncPress : 29|1@0+ (1,0) [0|1] "SED" Vector__XXX
 SG_ CcAslButtnResDecPress : 30|1@0+ (1,0) [0|1] "SED" Vector__XXX
 SG_ CcAslButtnOnPress : 31|1@0+ (1,0) [0|1] "SED" Vector__XXX
 SG_ CcAslButtnOnOffCncl : 16|1@0+ (1,0) [0|1] "SED" Vector__XXX
 SG_ CcAslButtnOffCnclPress : 17|1@0+ (1,0) [0|1] "SED" Vector__XXX
 SG_ CcAslButtnIndxIncPress : 18|1@0+ (1,0) [0|1] "SED" Vector__XXX
 SG_ CcAslButtnIndxDecPress : 19|1@0+ (1,0) [0|1] "SED" Vector__XXX
 SG_ CcAslButtnDeny_B_Actl : 20|1@0+ (1,0) [0|1] "SED" Vector__XXX
 SG_ CcAslButtnCnclResPress : 21|1@0+ (1,0) [0|1] "SED" Vector__XXX
 SG_ CcAslButtnCnclPress : 8|1@0+ (1,0) [0|1] "SED" Vector__XXX
 SG_ LaSwtchPos_D_Stat : 23|2@0+ (1,0) [0|3] "SED" Vector__XXX

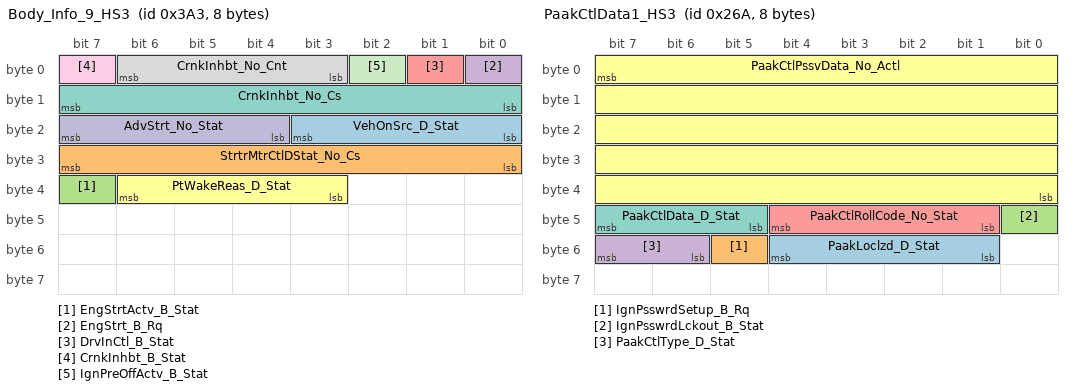
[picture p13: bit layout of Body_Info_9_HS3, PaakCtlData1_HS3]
BO_ 931 Body_Info_9_HS3: 8 GWM
 SG_ VehOnSrc_D_Stat : 19|4@0+ (1,0) [0|15] "SED"  APIM_CDC,APIM,APIM_CISM,IPC,APIM_CIM
 SG_ StrtrMtrCtlDStat_No_Cs : 31|8@0+ (1,0) [0|255] "unitless" Vector__XXX
 SG_ EngStrtActv_B_Stat : 39|1@0+ (1,0) [0|1] "SED" Vector__XXX
 SG_ EngStrt_B_Rq : 0|1@0+ (1,0) [0|1] "SED" Vector__XXX
 SG_ DrvInCtl_B_Stat : 1|1@0+ (1,0) [0|1] "SED" Vector__XXX
 SG_ PtWakeReas_D_Stat : 38|4@0+ (1,0) [0|15] "SED" Vector__XXX
 SG_ CrnkInhbt_No_Cs : 15|8@0+ (1,0) [0|255] "unitless" Vector__XXX
 SG_ CrnkInhbt_No_Cnt : 6|4@0+ (1,0) [0|15] "unitless" Vector__XXX
 SG_ CrnkInhbt_B_Stat : 7|1@0+ (1,0) [0|1] "SED" Vector__XXX
 SG_ AdvStrt_No_Stat : 23|4@0+ (1,0) [0|15] "unitless" Vector__XXX
 SG_ IgnPreOffActv_B_Stat : 2|1@0+ (1,0) [0|1] "SED" Vector__XXX

BO_ 618 PaakCtlData1_HS3: 8 GWM
 SG_ PaakLoclzd_D_Stat : 52|4@0+ (1,0) [0|15] "SED" Vector__XXX
 SG_ IgnPsswrdSetup_B_Rq : 53|1@0+ (1,0) [0|1] "SED"  APIM_CDC,APIM,APIM_CISM,APIM_CIM
 SG_ IgnPsswrdLckout_B_Stat : 40|1@0+ (1,0) [0|1] "SED"  APIM_CDC,APIM,APIM_CISM,APIM_CIM
 SG_ PaakCtlType_D_Stat : 55|2@0+ (1,0) [0|3] "SED" Vector__XXX
 SG_ PaakCtlRollCode_No_Stat : 44|4@0+ (1,0) [0|15] "unitless" Vector__XXX
 SG_ PaakCtlPssvData_No_Actl : 7|40@0+ (1,0) [0|1099511627775] "unitless" Vector__XXX
 SG_ PaakCtlData_D_Stat : 47|3@0+ (1,0) [0|7] "SED" Vector__XXX

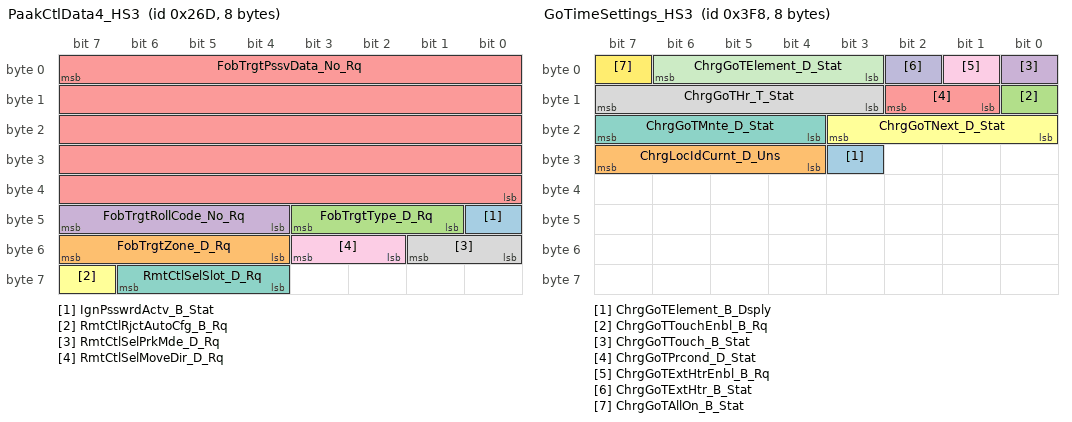
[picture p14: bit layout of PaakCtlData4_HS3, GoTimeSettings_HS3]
BO_ 621 PaakCtlData4_HS3: 8 GWM
 SG_ IgnPsswrdActv_B_Stat : 40|1@0+ (1,0) [0|1] "SED"  APIM_CDC,APIM,APIM_CISM,APIM_CIM
 SG_ FobTrgtZone_D_Rq : 55|4@0+ (1,0) [0|15] "SED" Vector__XXX
 SG_ FobTrgtType_D_Rq : 43|3@0+ (1,0) [0|7] "SED" Vector__XXX
 SG_ FobTrgtRollCode_No_Rq : 47|4@0+ (1,0) [0|15] "unitless" Vector__XXX
 SG_ FobTrgtPssvData_No_Rq : 7|40@0+ (1,0) [0|1099511627775] "Encrypted" Vector__XXX
 SG_ RmtCtlRjctAutoCfg_B_Rq : 63|1@0+ (1,0) [0|1] "SED" Vector__XXX
 SG_ RmtCtlSelSlot_D_Rq : 62|3@0+ (1,0) [0|7] "SED" Vector__XXX
 SG_ RmtCtlSelPrkMde_D_Rq : 49|2@0+ (1,0) [0|3] "SED" Vector__XXX
 SG_ RmtCtlSelMoveDir_D_Rq : 51|2@0+ (1,0) [0|3] "SED" Vector__XXX

BO_ 1016 GoTimeSettings_HS3: 8 GWM
 SG_ ChrgGoTElement_B_Dsply : 27|1@0+ (1,0) [0|1] "SED"  APIM_CDC,APIM,APIM_CISM,APIM_CIM
 SG_ ChrgLocIdCurnt_D_Uns : 31|4@0+ (1,0) [0|15] "unitless"  APIM_CDC,APIM,APIM_CISM,APIM_CIM
 SG_ ChrgGoTTouchEnbl_B_Rq : 8|1@0+ (1,0) [0|1] "SED"  APIM_CDC,APIM,APIM_CIM,APIM_CISM
 SG_ ChrgGoTTouch_B_Stat : 0|1@0+ (1,0) [0|1] "SED"  APIM_CDC,APIM,APIM_CISM,APIM_CIM
 SG_ ChrgGoTPrcond_D_Stat : 10|2@0+ (1,0) [0|3] "SED"  APIM_CDC,APIM,APIM_CISM,APIM_CIM
 SG_ ChrgGoTNext_D_Stat : 19|4@0+ (1,0) [0|15] "unitless"  APIM_CDC,APIM,APIM_CISM,APIM_CIM
 SG_ ChrgGoTMnte_D_Stat : 23|4@0+ (1,0) [0|15] "SED"  APIM_CDC,APIM,APIM_CISM,APIM_CIM
 SG_ ChrgGoTHr_T_Stat : 15|5@0+ (1,0) [0|29] "hour"  APIM_CDC,APIM,APIM_CISM,APIM_CIM
 SG_ ChrgGoTExtHtrEnbl_B_Rq : 1|1@0+ (1,0) [0|1] "SED" Vector__XXX
 SG_ ChrgGoTExtHtr_B_Stat : 2|1@0+ (1,0) [0|1] "SED"  APIM_CDC,APIM,APIM_CISM,APIM_CIM
 SG_ ChrgGoTElement_D_Stat : 6|4@0+ (1,0) [0|15] "unitless"  APIM_CDC,APIM,APIM_CISM,APIM_CIM
 SG_ ChrgGoTAllOn_B_Stat : 7|1@0+ (1,0) [0|1] "SED"  APIM_CDC,APIM,APIM_CISM,APIM_CIM

BO_ 773 PassengerSeat_Data_HS3: 8 GWM
 SG_ StmsScrnPsngrOn_B_Rq : 1|1@0+ (1,0) [0|1] "SED"  APIM_CDC,APIM,APIM_CIM,APIM_CISM
 SG_ SeatScrnPsngrOn_B_Rq : 6|1@0+ (1,0) [0|1] "SED"  APIM_CDC,APIM,APIM_CISM,APIM_CIM
 SG_ SeatPsngrMem_D_Cmd : 5|4@0+ (1,0) [0|15] "SED" Vector__XXX
 SG_ MemSwtchPsngrFdbck_B_Rq : 7|1@0+ (1,0) [0|1] "SED" Vector__XXX

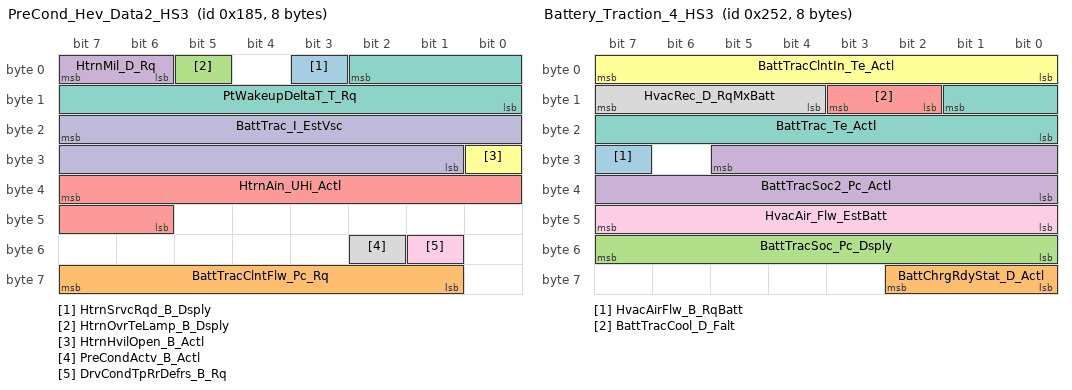
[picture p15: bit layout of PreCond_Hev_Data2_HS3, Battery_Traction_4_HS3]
BO_ 389 PreCond_Hev_Data2_HS3: 8 GWM
 SG_ HtrnSrvcRqd_B_Dsply : 3|1@0+ (1,0) [0|1] "SED"  APIM_CDC,APIM_CISM,APIM_CIM,IPC
 SG_ BattTracClntFlw_Pc_Rq : 63|7@0+ (1,0) [0|127] "percent" Vector__XXX
 SG_ HtrnOvrTeLamp_B_Dsply : 5|1@0+ (1,0) [0|1] "SED"  APIM_CDC,APIM_CIM,IPC,APIM_CISM
 SG_ HtrnMil_D_Rq : 7|2@0+ (1,0) [0|3] "SED" Vector__XXX
 SG_ HtrnAin_UHi_Actl : 39|10@0+ (0.5,0) [0|510.5] "volt" Vector__XXX
 SG_ HtrnHvilOpen_B_Actl : 24|1@0+ (1,0) [0|1] "SED" Vector__XXX
 SG_ PtWakeupDeltaT_T_Rq : 2|11@0+ (1,0) [0|2045] "minute" Vector__XXX
 SG_ PreCondActv_B_Actl : 50|1@0+ (1,0) [0|1] "SED" Vector__XXX
 SG_ DrvCondTpRrDefrs_B_Rq : 49|1@0+ (1,0) [0|1] "SED" Vector__XXX
 SG_ BattTrac_I_EstVsc : 23|15@0+ (0.05,-750) [-750|888.25] "Amps" Vector__XXX

BO_ 1128 BatteryCharge_Data2_HS3: 8 GWM
 SG_ DgtlCommGtwyMde_D_Rq : 48|4@0+ (1,0) [0|15] "SED" Vector__XXX
 SG_ ChrgrDcOvrVolt_B_Falt : 50|1@0+ (1,0) [0|1] "SED" Vector__XXX
 SG_ ChrgrDcOvrCurnt_B_Falt : 56|1@0+ (1,0) [0|1] "SED" Vector__XXX
 SG_ ExtChrgNowButtn_B_Rq : 49|1@0+ (1,0) [0|1] "SED" Vector__XXX
 SG_ CoolFanChrgr_D_Rq : 45|2@0+ (1,0) [0|3] "SED" Vector__XXX
 SG_ ChrgrPncEnbl_D_Stat : 58|2@0+ (1,0) [0|3] "SED" Vector__XXX
 SG_ ChrgrClntFlw_D_Rq : 31|2@0+ (1,0) [0|3] "SED" Vector__XXX
 SG_ PlgStatEvnt_B_Stat : 46|1@0+ (1,0) [0|1] "SED" Vector__XXX
 SG_ ChrgrCnnctPwr_B_Stat : 47|1@0+ (1,0) [0|1] "SED" Vector__XXX
 SG_ ChrgrAvailEvnt_B_Stat : 32|1@0+ (1,0) [0|1] "SED" Vector__XXX
 SG_ ChrgrSrvcRqd_B_Rq : 0|1@0+ (1,0) [0|1] "SED"  APIM_CDC,APIM_CIM,IPC
 SG_ ChrgrS2Swtch_B_Stat : 42|1@0+ (1,0) [0|1] "SED" Vector__XXX
 SG_ ChrgChngEvnt_B_Stat : 33|1@0+ (1,0) [0|1] "SED" Vector__XXX
 SG_ ChrgrCc2Cnnct_B_Falt : 59|1@0+ (1,0) [0|1] "SED" Vector__XXX
 SG_ ChrgPortDcTeMx_B_Falt : 60|1@0+ (1,0) [0|1] "SED" Vector__XXX
 SG_ ChrgCordLck_D_Stat : 7|3@0+ (1,0) [0|7] "SED"  APIM_CDC,APIM,APIM_CIM,APIM_CISM
 SG_ ChrgrInPwMde_D_Actl : 4|4@0+ (1,0) [0|15] "SED" Vector__XXX
 SG_ ChrgPortDrOpen_B_Stat : 43|1@0+ (1,0) [0|1] "SED"  APIM_CDC,APIM_CIM,IPC
 SG_ ChrgCordChlng2_No_Actl : 23|8@0+ (1,0) [0|255] "unitless" Vector__XXX
 SG_ AcChrgRdy_B_Stat : 51|1@0+ (1,0) [0|1] "SED" Vector__XXX
 SG_ BptTgl_B_Complt : 29|1@0+ (1,0) [0|1] "SED" Vector__XXX
 SG_ ChrgCordChlng1_No_Actl : 15|8@0+ (1,0) [0|255] "unitless" Vector__XXX
 SG_ ChrgCrdLck_D_Falt : 41|2@0+ (1,0) [0|3] "SED"  APIM_CDC,APIM,APIM_CISM,IPC,APIM_CIM

BO_ 594 Battery_Traction_4_HS3: 8 GWM
 SG_ HvacAirFlw_B_RqBatt : 31|1@0+ (1,0) [0|1] "SED" Vector__XXX
 SG_ BattChrgRdyStat_D_Actl : 58|3@0+ (1,0) [0|7] "SED" Vector__XXX
 SG_ BattTracSoc_Pc_Dsply : 55|8@0+ (0.5,0) [0|126.5] "Percent"  APIM_CDC,APIM,APIM_CIM,HUD_ADV,IPC,APIM_CISM
 SG_ BattTracSoc2_Pc_Actl : 29|14@0+ (0.01,0) [0|163.81] "%" Vector__XXX
 SG_ BattTracCool_D_Falt : 11|2@0+ (1,0) [0|3] "SED" Vector__XXX
 SG_ BattTracClntIn_Te_Actl : 7|8@0+ (1,-50) [-50|204] "degC" Vector__XXX
 SG_ BattTrac_Te_Actl : 9|10@0+ (0.5,-50) [-50|460.5] "degC" Vector__XXX
 SG_ HvacRec_D_RqMxBatt : 15|4@0+ (1,0) [0|15] "SED" Vector__XXX
 SG_ HvacAir_Flw_EstBatt : 47|8@0+ (0.5,0) [0|127] "liter/second" Vector__XXX

BO_ 2614099160 SymKeyFuncGWM_ECG_HS3: 8 GWM
 SG_ SymKeyFuncGWM_ECG : 7|29@0+ (1,0) [0|536870911] "unitless"  RACM_RCIM,WCM,IPC,ESPM

BO_ 2610117848 OTAPhysGWM_ECGtoESPM: 8 GWM
 SG_ OTAPhysGWM_ECGtoESPM : 7|29@0+ (1,0) [0|536870911] "unitless"  ESPM

BO_ 2610127055 OTAPhysESPMtoGWM_ECG: 8 ESPM
 SG_ OTAPhysESPMtoGWM_ECG : 7|29@0+ (1,0) [0|536870911] "unitless"  GWM

BO_ 2611175631 PARSEDPhysESPMtoGWM_ECG: 8 ESPM
 SG_ PARSEDPhysESPMtoGWM_ECG : 7|29@0+ (1,0) [0|536870911] "unitless"  GWM

BO_ 2612215000 PARSEDPushFcGWM_ECGtoESPM: 8 GWM
 SG_ PARSEDPushFcGWM_ECGtoESPM : 7|29@0+ (1,0) [0|536870911] "unitless"  ESPM

BO_ 2612224207 PARSEDPushESPMoGWM_ECG: 8 ESPM
 SG_ PARSEDPushESPMoGWM_ECG : 7|29@0+ (1,0) [0|536870911] "unitless"  ESPM

BO_ 2613263576 SymKeyPhysGWM_ECGtoESPM: 8 GWM
 SG_ SymKeyPhysGWM_ECGtoESPM : 7|29@0+ (1,0) [0|536870911] "unitless"  ESPM

BO_ 2613272783 SymKeyPhysESPMtoGWM_ECG: 8 ESPM
 SG_ SymKeyPhysESPMtoGWM_ECG : 7|29@0+ (1,0) [0|536870911] "unitless"  GWM

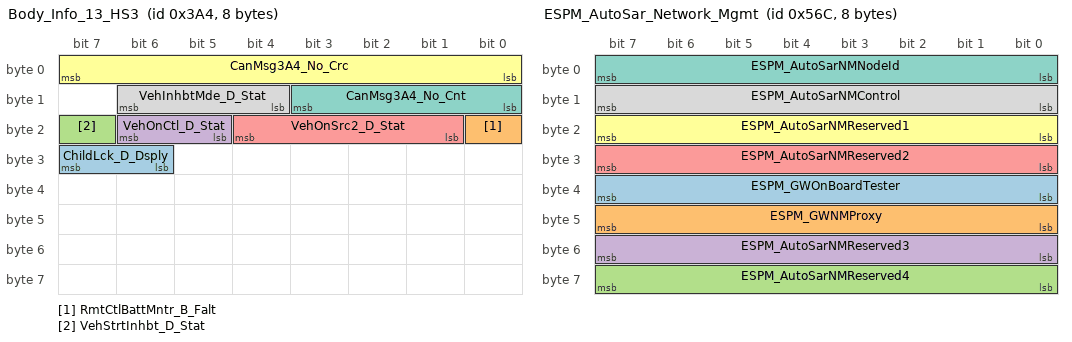
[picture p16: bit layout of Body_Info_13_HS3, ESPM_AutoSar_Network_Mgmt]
BO_ 932 Body_Info_13_HS3: 8 GWM
 SG_ ChildLck_D_Dsply : 31|2@0+ (1,0) [0|3] "SED" Vector__XXX
 SG_ RmtCtlBattMntr_B_Falt : 16|1@0+ (1,0) [0|1] "SED" Vector__XXX
 SG_ VehStrtInhbt_D_Stat : 23|1@0+ (1,0) [0|1] "SED"  ESPM
 SG_ VehOnCtl_D_Stat : 22|2@0+ (1,0) [0|3] "SED" Vector__XXX
 SG_ VehOnSrc2_D_Stat : 20|4@0+ (1,0) [0|15] "SED"  ESPM
 SG_ CanMsg3A4_No_Crc : 7|8@0+ (1,0) [0|255] "unitless" Vector__XXX
 SG_ CanMsg3A4_No_Cnt : 11|4@0+ (1,0) [0|15] "unitless" Vector__XXX
 SG_ VehInhbtMde_D_Stat : 14|3@0+ (1,0) [0|7] "SED" Vector__XXX

BO_ 1388 ESPM_AutoSar_Network_Mgmt: 8 ESPM
 SG_ ESPM_GWOnBoardTester : 39|8@0+ (1,0) [0|255] "unitless"  GENERIC
 SG_ ESPM_GWNMProxy : 47|8@0+ (1,0) [0|255] "unitless"  GENERIC
 SG_ ESPM_AutoSarNMReserved4 : 63|8@0+ (1,0) [0|255] "unitless"  GENERIC
 SG_ ESPM_AutoSarNMReserved3 : 55|8@0+ (1,0) [0|255] "unitless"  GENERIC
 SG_ ESPM_AutoSarNMReserved2 : 31|8@0+ (1,0) [0|255] "unitless"  GENERIC
 SG_ ESPM_AutoSarNMReserved1 : 23|8@0+ (1,0) [0|255] "unitless"  GENERIC
 SG_ ESPM_AutoSarNMNodeId : 7|8@0+ (1,0) [0|255] "unitless"  GENERIC
 SG_ ESPM_AutoSarNMControl : 15|8@0+ (1,0) [0|255] "unitless"  GENERIC

BO_ 1769 TesterPhysicalResESPM: 8 ESPM
 SG_ TesterPhysicalResESPM : 7|64@0+ (1,0) [0|1.84467E+019] "unitless"  TSTR

BO_ 1761 TesterPhysicalReqESPM: 8 TSTR
 SG_ TesterPhysicalReqESPM : 7|64@0+ (1,0) [0|1.84467E+019] "unitless"  ESPM

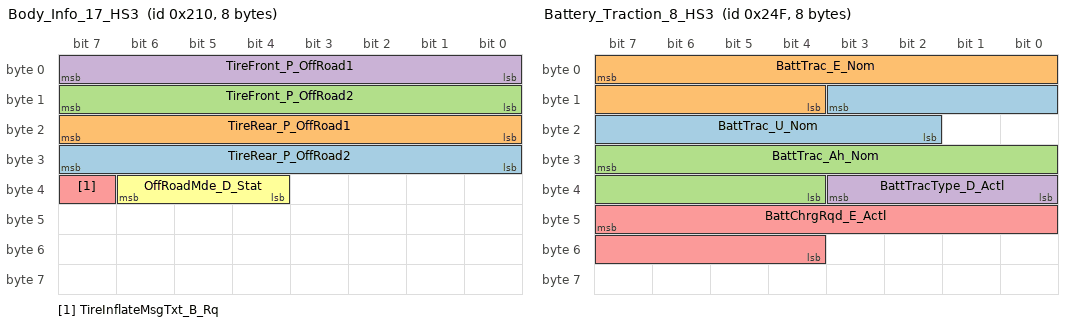
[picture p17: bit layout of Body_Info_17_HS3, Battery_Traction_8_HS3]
BO_ 528 Body_Info_17_HS3: 8 GWM
 SG_ TireRear_P_OffRoad2 : 31|8@0+ (1,0) [0|255] "pounds/inch^2"  IPC
 SG_ TireRear_P_OffRoad1 : 23|8@0+ (1,0) [0|255] "pounds/inch^2"  IPC
 SG_ TireFront_P_OffRoad2 : 15|8@0+ (1,0) [0|255] "pounds/inch^2"  IPC
 SG_ TireFront_P_OffRoad1 : 7|8@0+ (1,0) [0|255] "pounds/inch^2"  IPC
 SG_ TireInflateMsgTxt_B_Rq : 39|1@0+ (1,0) [0|1] "SED"  IPC
 SG_ OffRoadMde_D_Stat : 38|3@0+ (1,0) [0|7] "SED"  IPC

BO_ 591 Battery_Traction_8_HS3: 8 GWM
 SG_ BattTrac_U_Nom : 11|10@0+ (0.5,0) [0|510.5] "volt" Vector__XXX
 SG_ BattTrac_E_Nom : 7|12@0+ (50,0) [0|204650] "watt*hr"  APIM_CDC,APIM,APIM_CIM,APIM_CISM
 SG_ BattTrac_Ah_Nom : 31|12@0+ (0.1,0) [0|409.4] "ampere*hour" Vector__XXX
 SG_ BattTracType_D_Actl : 35|4@0+ (1,0) [0|15] "SED" Vector__XXX
 SG_ BattChrgRqd_E_Actl : 47|12@0+ (50,0) [0|204650] "watt*hour" Vector__XXX

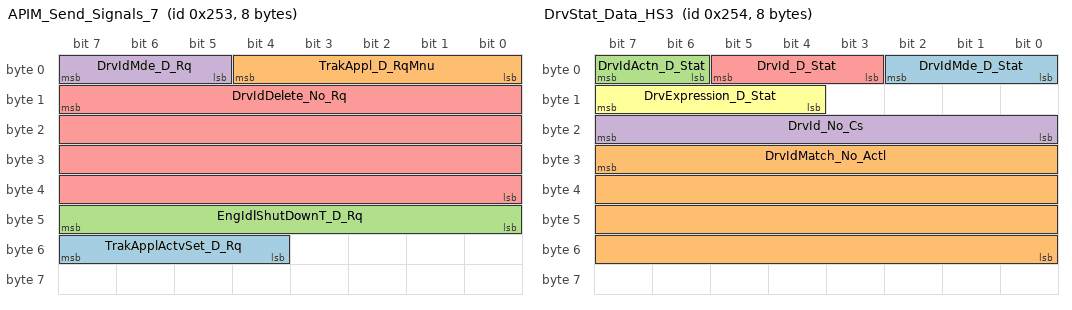
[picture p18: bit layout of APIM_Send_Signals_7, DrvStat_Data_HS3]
BO_ 595 APIM_Send_Signals_7: 8 APIM_CIM
 SG_ TrakApplActvSet_D_Rq : 55|4@0+ (1,0) [0|15] "SED"  IPC,GWM
 SG_ TrakAppl_D_RqMnu : 4|5@0+ (1,0) [0|31] "SED"  IPC,GWM
 SG_ EngIdlShutDownT_D_Rq : 47|8@0+ (1,0) [0|255] "SED"  GWM
 SG_ DrvIdMde_D_Rq : 7|3@0+ (1,0) [0|7] "SED"  GWM
 SG_ DrvIdDelete_No_Rq : 15|32@0+ (1,0) [0|4294967295] "Unitless"  GWM

BO_ 596 DrvStat_Data_HS3: 8 GWM
 SG_ DrvIdMde_D_Stat : 2|3@0+ (1,0) [0|7] "SED"  APIM_CDC,APIM,APIM_CIM,APIM_CISM
 SG_ DrvIdMatch_No_Actl : 31|32@0+ (1,0) [0|4294967295] "Unitless"  APIM_CDC,APIM,APIM_CIM,APIM_CISM
 SG_ DrvIdActn_D_Stat : 7|2@0+ (1,0) [0|3] "SED"  APIM_CDC,APIM,APIM_CIM,APIM_CISM
 SG_ DrvId_No_Cs : 23|8@0+ (1,0) [0|255] "unitless"  APIM_CDC,APIM,APIM_CIM,APIM_CISM
 SG_ DrvId_D_Stat : 5|3@0+ (1,0) [0|7] "SED"  APIM_CDC,APIM,APIM_CIM,APIM_CISM
 SG_ DrvExpression_D_Stat : 15|4@0+ (1,0) [0|15] "SED"  APIM_CDC,APIM,APIM_CIM,APIM_CISM

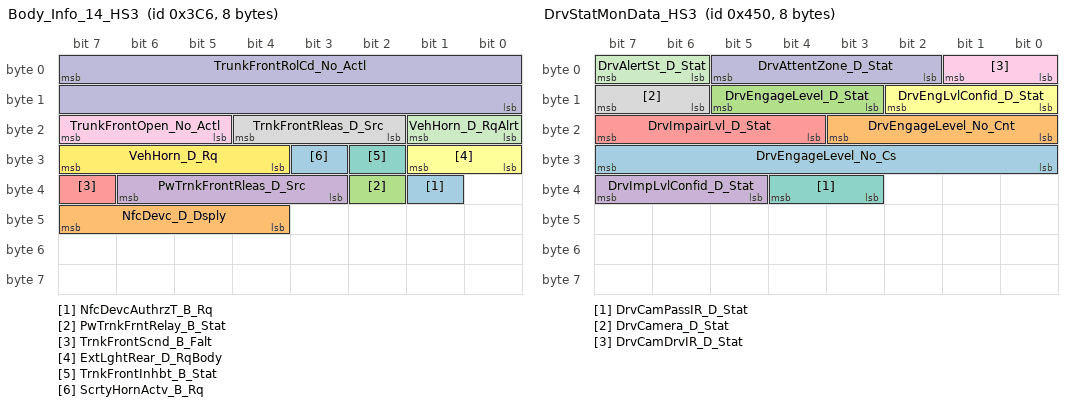
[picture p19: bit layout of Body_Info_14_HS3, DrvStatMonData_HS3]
BO_ 966 Body_Info_14_HS3: 8 GWM
 SG_ NfcDevcAuthrzT_B_Rq : 33|1@0+ (1,0) [0|1] "SED" Vector__XXX
 SG_ NfcDevc_D_Dsply : 47|4@0+ (1,0) [0|15] "SED"  IPC
 SG_ PwTrnkFrntRelay_B_Stat : 34|1@0+ (1,0) [0|1] "SED" Vector__XXX
 SG_ PwTrnkFrontRleas_D_Src : 38|4@0+ (1,0) [0|15] "SED" Vector__XXX
 SG_ TrnkFrontScnd_B_Falt : 39|1@0+ (1,0) [0|1] "SED"  APIM_CDC,APIM_CIM,IPC
 SG_ ExtLghtRear_D_RqBody : 25|2@0+ (1,0) [0|3] "SED" Vector__XXX
 SG_ TrnkFrontInhbt_B_Stat : 26|1@0+ (1,0) [0|1] "SED" Vector__XXX
 SG_ TrnkFrontRleas_D_Src : 20|3@0+ (1,0) [0|7] "SED" Vector__XXX
 SG_ TrunkFrontOpen_No_Actl : 23|3@0+ (1,0) [0|7] "unitless" Vector__XXX
 SG_ TrunkFrontRolCd_No_Actl : 7|16@0+ (1,0) [0|65535] "unitless" Vector__XXX
 SG_ VehHorn_D_RqAlrt : 17|2@0+ (1,0) [0|3] "SED" Vector__XXX
 SG_ VehHorn_D_Rq : 31|4@0+ (1,0) [0|15] "SED" Vector__XXX
 SG_ ScrtyHornActv_B_Rq : 27|1@0+ (1,0) [0|1] "SED" Vector__XXX

BO_ 1104 DrvStatMonData_HS3: 8 GWM
 SG_ DrvEngageLevel_No_Cs : 31|8@0+ (1,0) [0|255] "unitless" Vector__XXX
 SG_ DrvEngageLevel_No_Cnt : 19|4@0+ (1,0) [0|15] "unitless" Vector__XXX
 SG_ DrvEngageLevel_D_Stat : 13|3@0+ (1,0) [0|7] "SED" Vector__XXX
 SG_ DrvImpLvlConfid_D_Stat : 39|3@0+ (1,0) [0|7] "SED" Vector__XXX
 SG_ DrvImpairLvl_D_Stat : 23|4@0+ (1,0) [0|15] "SED" Vector__XXX
 SG_ DrvEngLvlConfid_D_Stat : 10|3@0+ (1,0) [0|7] "SED" Vector__XXX
 SG_ DrvCamPassIR_D_Stat : 36|2@0+ (1,0) [0|3] "SED"  APIM_CDC,APIM,APIM_CIM,APIM_CISM
 SG_ DrvCamera_D_Stat : 15|2@0+ (1,0) [0|3] "SED"  APIM_CDC,APIM,APIM_CIM,APIM_CISM
 SG_ DrvCamDrvIR_D_Stat : 1|2@0+ (1,0) [0|3] "SED"  APIM_CDC,APIM,APIM_CIM,APIM_CISM
 SG_ DrvAttentZone_D_Stat : 5|4@0+ (1,0) [0|15] "SED" Vector__XXX
 SG_ DrvAlertSt_D_Stat : 7|2@0+ (1,0) [0|3] "SED" Vector__XXX

BO_ 303 Body_Info_16_HS3: 8 GWM
 SG_ CanMsg12F_No_Crc : 7|8@0+ (1,0) [0|255] "Unitless" Vector__XXX
 SG_ CanMsg12F_No_Cnt : 11|4@0+ (1,0) [0|15] "Unitless" Vector__XXX
 SG_ DrStatHood_D2_Actl : 23|3@0+ (1,0) [0|7] "SED"  IPC

BO_ 2612224006 PARSEDPushHUDtoGWM_ECG: 8 HUD_ADV
 SG_ PARSEDPushHUDtoGWM_ECG : 7|29@0+ (1,0) [0|536870911] "unitless"  GWM

BO_ 2612009176 PARSEDPushFcGWM_ECGtoHUD: 8 GWM
 SG_ PARSEDPushFcGWM_ECGtoHUD : 7|29@0+ (1,0) [0|536870911] "unitless"  HUD_ADV

BO_ 2611175430 PARSEDPhysHUDtoGWM_ECG: 8 HUD_ADV
 SG_ PARSEDPhysHUDtoGWM_ECG : 7|29@0+ (1,0) [0|536870911] "Unitless"  GWM

BO_ 2610960600 PARSEDPhysGWM_ECGtoHUD: 8 GWM
 SG_ PARSEDPhysGWM_ECGtoHUD : 7|29@0+ (1,0) [0|536870911] "unitless"  HUD_ADV

BO_ 2610126854 OTAPhysHUDtoGWM_ECG: 8 HUD_ADV
 SG_ OTAPhysHUDtoGWM_ECG : 7|29@0+ (1,0) [0|536870911] "unitless"  GWM

BO_ 2609912024 OTAPhysGWM_ECGtoHUD: 8 GWM
 SG_ OTAPhysGWM_ECGtoHUD : 7|29@0+ (1,0) [0|536870911] "unitless"  HUD_ADV

BO_TX_BU_ 1259 : APIM,APIM_CDC,APIM_CIM,APIM_CISM;
BO_TX_BU_ 1266 : APIM,APIM_CDC,APIM_CISM;
BO_TX_BU_ 659 : APIM,APIM_CDC,APIM_CISM,APIM_CIM;
BO_TX_BU_ 630 : APIM,APIM_CDC,APIM_CISM,APIM_CIM;
BO_TX_BU_ 627 : APIM,APIM_CDC,APIM_CISM,APIM_CIM;
BO_TX_BU_ 595 : APIM,APIM_CDC,APIM_CISM,APIM_CIM;

CM_ "FNV3 HS3 CAN";
CM_ BU_ ARM "Augmented Reality Module";
CM_ BU_ APIM_CDC "Accessory Protocol Interface Module - Cockpit Domain Controller";
CM_ BU_ APIM_CISM "Accessory Protocol Interface Module - Cockpit Infotainment System Module";
CM_ BU_ APIM "Accessory Protocol Interface Module 4.0";
CM_ BU_ ESPM "Ethernet Switch Port Module";
CM_ BU_ DSP "Audio Digital Signal Processing Module";
CM_ BU_ APIM_CIM "Accessory Protocol Interface Module - Centralized Infotainment Module";
CM_ BU_ FCIMB "Front Controls Interface Module B";
CM_ BU_ RACM_RCIM "Rear Audio Control Module - Rear Controls Interface Module";
CM_ BU_ HUD_ADV "Advanced HUD";
CM_ BU_ WCM "Wireless Charging Module";
CM_ BU_ TRM_ITRM "Integrated Trailer Module with TBM on HS2 for FNV2.5";
CM_ BU_ ACM "Audio Control Module";
CM_ BU_ GWM "Gateway Module";
CM_ BU_ IPC "Instrument Panel Cluster Control Module";
CM_ BU_ GENERIC "Holding pattern ECU for developmental messages";
CM_ BU_ TSTR "Diagnostic Tester";
CM_ BO_ 1304 "RACM_REM3 - RearEntertainmentModule3 Flextronics U553";
CM_ SG_ 667 APIM_NFAM_Word_Rx "MM ISO 15765-2 Message Catalogue
Section CONMP - RDISP";
CM_ SG_ 659 APIM_NFAM_Word_Tx "MM ISO 15765-2 Message Catalogue
Section RDISP - CONMP";
CM_ SG_ 118 SteWhlCompAnEst_D_Qf "Legacy signal not supported, reserving bit locations for commodity BCM, PAM, RCM, APIM dbc files.  GWM to Tx Init value, no valid data. ";
CM_ SG_ 118 SteWhlComp_An_Est "Legacy signal not supported, reserving bit locations for commodity BCM, PAM, RCM, APIM dbc files.  GWM to Tx Init value, no valid data. ";
CM_ SG_ 836 FohFalt_D_Stat "Signal not transmitted on vehicles that do not have the Fuel operated heater feature.";
CM_ SG_ 836 FohEnbl_B_RqDrv "Signal not transmitted on vehicles that do not have the Fuel operated heater feature.";
CM_ SG_ 836 FohRqRun_B_Rq "Signal not transmitted on vehicles that do not have the Fuel operated heater feature.";
CM_ SG_ 836 HvacPrecondMode_D_Rq "Signal not transmitted on vehicles that do not have the Fuel operated heater feature.";
CM_ SG_ 836 HvacPrecondBlwr_D_Rq "Signal not transmitted on vehicles that do not have the Fuel operated heater feature.";
CM_ SG_ 836 Foh_D_Stat "Signal not transmitted on vehicles that do not have the Fuel operated heater feature.";
CM_ SG_ 836 FuelFlw_Vl_ActlFoh "Signal not transmitted on vehicles that do not have the Fuel operated heater feature.";
CM_ SG_ 836 EngClnt_Te_ActlFoh "Signal not transmitted on vehicles that do not have the Fuel operated heater feature.";
CM_ SG_ 931 CrnkInhbt_No_Cs "Signal not transmitted on gas and HEV variants.";
CM_ SG_ 931 CrnkInhbt_No_Cnt "Signal not transmitted on gas and HEV variants.";
CM_ SG_ 618 IgnPsswrdSetup_B_Rq "ABSGenSigTimeoutTime=1000";
CM_ SG_ 618 IgnPsswrdLckout_B_Stat "ABSGenSigTimeoutTime=1000";
CM_ SG_ 618 PaakCtlPssvData_No_Actl "Not transmitted on all vehicle variants";
CM_ SG_ 773 MemSwtchPsngrFdbck_B_Rq "Updated to 1 bit for CGEA, Not backwards compatible";
CM_ BO_ 932 "NOTE: START BITS 8-11 MUST BE OPEN SPEC REQUIREMENT";
CM_ SG_ 932 CanMsg3A4_No_Crc "Signal not transmitted on gas and HEV variants.";
CM_ SG_ 932 CanMsg3A4_No_Cnt "Signal not transmitted on gas and HEV variants.";
CM_ SG_ 1104 DrvEngageLevel_No_Cs "Signal not transmitted on gas variants.";
CM_ SG_ 1104 DrvEngageLevel_No_Cnt "Signal not transmitted on gas variants.";
BA_DEF_  "BusType" STRING ;
BA_DEF_ BO_  "FrameRouting" STRING ;
BA_DEF_ BO_  "NetworkInitialization" ENUM  "No","Yes";
BA_DEF_ BO_  "GenMsgStartDelayTime" INT 0 10000;
BA_DEF_ BO_  "GenMsgNrOfRepetition" INT 0 100;
BA_DEF_ BO_  "GenMsgDelayTime" INT 0 1000;
BA_DEF_ BO_  "GenMsgCycleTime" INT 0 100000;
BA_DEF_ BO_  "GenMsgSendType" ENUM  "FixedPeriodic","Event","EnabledPeriodic","NotUsed","NotUsed","EventPeriodic","NotUsed","NotUsed","NoMsgSendType";
BA_DEF_ SG_  "U_P702_MY2024_Tx" ENUM  "No","Yes";
BA_DEF_ SG_  "U_V710_MY2023_Tx" ENUM  "No","Yes";
BA_DEF_ SG_  "U_CDX74X_MY2024_Tx" ENUM  "No","Yes";
BA_DEF_ SG_  "U_CDX707_MY2023_Tx" ENUM  "No","Yes";
BA_DEF_ SG_  "U_P708_MY2023_Tx" ENUM  "No","Yes";
BA_DEF_ SG_  "U_V713AV_MY2022_Tx" ENUM  "No","Yes";
BA_DEF_ SG_  "U_V713N_MY2022_Tx" ENUM  "No","Yes";
BA_DEF_ SG_  "ECGUsedTxSignal" ENUM  "No","Yes";
BA_DEF_ SG_  "U_P702_MY2024_Rx" ENUM  "No","Yes";
BA_DEF_ SG_  "U_V710_MY2023_Rx" ENUM  "No","Yes";
BA_DEF_ SG_  "U_CDX74X_MY2024_Rx" ENUM  "No","Yes";
BA_DEF_ SG_  "U_CDX707_MY2023_Rx" ENUM  "No","Yes";
BA_DEF_ SG_  "U_P708_MY2023_Rx" ENUM  "No","Yes";
BA_DEF_ SG_  "U_V713AV_MY2022_Rx" ENUM  "No","Yes";
BA_DEF_ SG_  "U_V713N_MY2022_Rx" ENUM  "No","Yes";
BA_DEF_ SG_  "ECGUsedRxSignal" ENUM  "No","Yes";
BA_DEF_ SG_  "UsedOnPgmDBC" ENUM  "No","Yes";
BA_DEF_ SG_  "ContentDependant" ENUM  "No","Yes";
BA_DEF_ SG_  "GenSigStartValue" HEX 0 268435455;
BA_DEF_ SG_  "MetaData" ENUM  "No","Yes";
BA_DEF_ SG_  "WakeupSignal" ENUM  "No","Yes";
BA_DEF_ SG_  "GenSigInactiveValue" INT 0 100000;
BA_DEF_ SG_  "GenSigSendType" ENUM  "Cyclic","OnWrite","vector_leerstring","OnChange","vector_leerstring","IfActive","vector_leerstring","NoSigSendType";
BA_DEF_ BO_  "TpTxIndex" INT 0 536870911;
BA_DEF_ BO_  "OvtpPushApplication" ENUM  "FALSE","TRUE";
BA_DEF_ BO_  "SCP_FreshnessValueLength" INT 0 512;
BA_DEF_ BO_  "SCP_DataId" INT 0 17663;
BA_DEF_ BO_  "SCP_FreshnessValueTxLength" INT 0 512;
BA_DEF_ BO_  "SCP_AuthInfoTxLength" INT 0 512;
BA_DEF_ BO_  "SC_Message" ENUM  "No","Yes";
BA_DEF_ BO_  "GenMsgRoutingTimeoutTime" INT 0 5000;
BA_DEF_ BO_  "MessageGateway" ENUM  "No","Yes";
BA_DEF_ BO_  "NmAsrMessage" ENUM  "No","Yes";
BA_DEF_ BO_  "DiagState" ENUM  "No","Yes";
BA_DEF_ BO_  "DiagRequest" ENUM  "No","Yes";
BA_DEF_ BO_  "DiagResponse" ENUM  "No","Yes";
BA_DEF_ BO_  "NmMessage" ENUM  "No","Yes";
BA_DEF_ BO_  "GenMsgILSupport" ENUM  "No","Yes";
BA_DEF_ BU_  "OvtpOperationMode" ENUM  "SERVER","CLIENT";
BA_DEF_ BU_  "OvtpEcuAddress" INT 0 1022;
BA_DEF_ BU_  "ILUsed" ENUM  "No","Yes";
BA_DEF_ BU_  "Terminator" ENUM  "No","Yes";
BA_DEF_ BU_  "NodeWakeUpTime" INT 0 10000;
BA_DEF_ BU_  "NodeStartUpTime" INT 0 10000;
BA_DEF_ BU_  "NmAsrNodeIdentifier" HEX 0 255;
BA_DEF_ BU_  "NmAsrNode" ENUM  "No","Yes";
BA_DEF_ BU_  "PowerType" ENUM  "Switched","Latched","Sleep","vector_leerstring","vector_leerstring";
BA_DEF_ BU_  "NmStationAddress" INT 0 255;
BA_DEF_ BU_  "NosPackage" ENUM  "None","I3_1","I3_2","1.0.1","RP","EuCD","Volcano","I3_3","FNOS_Autosar";
BA_DEF_ BU_  "PackageID" STRING ;
BA_DEF_ BU_  "GatewayECU" ENUM  "No","Yes";
BA_DEF_  "NetworkSpeed" ENUM  "500kBits/s","125kBit/s";
BA_DEF_  "VersionNumber" INT 0 10000;
BA_DEF_  "StarNetworkGwType" ENUM  "0=NotDefined","1=HS1","2=HS2","3=HS3","4=HS4","5=HS5","6=MS1","7=HS6","8=HS7","9=MS2","10=FD1","11=FD2","12=FD3","13=FD4","14=FD5","15=FD6","16=FD7","17=FD8";
BA_DEF_  "CMDB_Version" STRING ;
BA_DEF_  "NmType" STRING ;
BA_DEF_  "NmAsrMessageCount" INT 128 256;
BA_DEF_  "NmAsrBaseAddress" HEX 1280 1408;
BA_DEF_  "DBName" STRING ;
BA_DEF_  "VersionDay" INT 1 31;
BA_DEF_  "Manufacturer" STRING ;
BA_DEF_  "VersionMonth" INT 1 12;
BA_DEF_  "VersionYear" INT 2000 3000;
BA_DEF_  "NmBaseAddress" HEX 1280 1280;
BA_DEF_  "NmMessageCount" INT 0 128;
BA_DEF_DEF_  "BusType" "";
BA_DEF_DEF_  "FrameRouting" "";
BA_DEF_DEF_  "NetworkInitialization" "Yes";
BA_DEF_DEF_  "GenMsgStartDelayTime" 0;
BA_DEF_DEF_  "GenMsgNrOfRepetition" 1;
BA_DEF_DEF_  "GenMsgDelayTime" 20;
BA_DEF_DEF_  "GenMsgCycleTime" 0;
BA_DEF_DEF_  "GenMsgSendType" "NoMsgSendType";
BA_DEF_DEF_  "U_P702_MY2024_Tx" "No";
BA_DEF_DEF_  "U_V710_MY2023_Tx" "No";
BA_DEF_DEF_  "U_CDX74X_MY2024_Tx" "No";
BA_DEF_DEF_  "U_CDX707_MY2023_Tx" "No";
BA_DEF_DEF_  "U_P708_MY2023_Tx" "No";
BA_DEF_DEF_  "U_V713AV_MY2022_Tx" "No";
BA_DEF_DEF_  "U_V713N_MY2022_Tx" "No";
BA_DEF_DEF_  "ECGUsedTxSignal" "No";
BA_DEF_DEF_  "U_P702_MY2024_Rx" "No";
BA_DEF_DEF_  "U_V710_MY2023_Rx" "No";
BA_DEF_DEF_  "U_CDX74X_MY2024_Rx" "No";
BA_DEF_DEF_  "U_CDX707_MY2023_Rx" "No";
BA_DEF_DEF_  "U_P708_MY2023_Rx" "No";
BA_DEF_DEF_  "U_V713AV_MY2022_Rx" "No";
BA_DEF_DEF_  "U_V713N_MY2022_Rx" "No";
BA_DEF_DEF_  "ECGUsedRxSignal" "No";
BA_DEF_DEF_  "UsedOnPgmDBC" "Yes";
BA_DEF_DEF_  "ContentDependant" "No";
BA_DEF_DEF_  "GenSigStartValue" 0;
BA_DEF_DEF_  "MetaData" "No";
BA_DEF_DEF_  "WakeupSignal" "No";
BA_DEF_DEF_  "GenSigInactiveValue" 0;
BA_DEF_DEF_  "GenSigSendType" "NoSigSendType";
BA_DEF_DEF_  "TpTxIndex" 0;
BA_DEF_DEF_  "OvtpPushApplication" "FALSE";
BA_DEF_DEF_  "SCP_FreshnessValueLength" 64;
BA_DEF_DEF_  "SCP_DataId" 0;
BA_DEF_DEF_  "SCP_FreshnessValueTxLength" 11;
BA_DEF_DEF_  "SCP_AuthInfoTxLength" 53;
BA_DEF_DEF_  "SC_Message" "No";
BA_DEF_DEF_  "GenMsgRoutingTimeoutTime" 0;
BA_DEF_DEF_  "MessageGateway" "No";
BA_DEF_DEF_  "NmAsrMessage" "No";
BA_DEF_DEF_  "DiagState" "No";
BA_DEF_DEF_  "DiagRequest" "No";
BA_DEF_DEF_  "DiagResponse" "No";
BA_DEF_DEF_  "NmMessage" "No";
BA_DEF_DEF_  "GenMsgILSupport" "Yes";
BA_DEF_DEF_  "OvtpOperationMode" "SERVER";
BA_DEF_DEF_  "OvtpEcuAddress" 0;
BA_DEF_DEF_  "ILUsed" "Yes";
BA_DEF_DEF_  "Terminator" "No";
BA_DEF_DEF_  "NodeWakeUpTime" 10;
BA_DEF_DEF_  "NodeStartUpTime" 250;
BA_DEF_DEF_  "NmAsrNodeIdentifier" 128;
BA_DEF_DEF_  "NmAsrNode" "No";
BA_DEF_DEF_  "PowerType" "Switched";
BA_DEF_DEF_  "NmStationAddress" 0;
BA_DEF_DEF_  "NosPackage" "I3_3";
BA_DEF_DEF_  "PackageID" "08.05.00.00.71.xx.xx.rr.00.00";
BA_DEF_DEF_  "GatewayECU" "No";
BA_DEF_DEF_  "NetworkSpeed" "500kBits/s";
BA_DEF_DEF_  "VersionNumber" 1;
BA_DEF_DEF_  "StarNetworkGwType" "0=NotDefined";
BA_DEF_DEF_  "CMDB_Version" "v11.01";
BA_DEF_DEF_  "NmType" "Ford-OSEK";
BA_DEF_DEF_  "NmAsrMessageCount" 128;
BA_DEF_DEF_  "NmAsrBaseAddress" 1408;
BA_DEF_DEF_  "DBName" "";
BA_DEF_DEF_  "VersionDay" 1;
BA_DEF_DEF_  "Manufacturer" "Ford";
BA_DEF_DEF_  "VersionMonth" 1;
BA_DEF_DEF_  "VersionYear" 2011;
BA_DEF_DEF_  "NmBaseAddress" 1280;
BA_DEF_DEF_  "NmMessageCount" 128;
BA_ "BusType" "CAN";
BA_ "VersionYear" 2021;
BA_ "VersionMonth" 5;
BA_ "VersionDay" 14;
BA_ "CMDB_Version" "FNV3_v21.03";
BA_ "StarNetworkGwType" 3;
BA_ "VersionNumber" 3;
BA_ "DBName" "HS3_CAN";
BA_ "NmStationAddress" BU_ ARM 220;
BA_ "PowerType" BU_ ARM 1;
BA_ "NmAsrNode" BU_ ARM 1;
BA_ "NmAsrNodeIdentifier" BU_ ARM 220;
BA_ "NodeWakeUpTime" BU_ ARM 100;
BA_ "OvtpEcuAddress" BU_ ARM 211;
BA_ "NmStationAddress" BU_ APIM_CDC 98;
BA_ "PowerType" BU_ APIM_CDC 2;
BA_ "NmAsrNode" BU_ APIM_CDC 1;
BA_ "NmAsrNodeIdentifier" BU_ APIM_CDC 226;
BA_ "NodeStartUpTime" BU_ APIM_CDC 1000;
BA_ "NodeWakeUpTime" BU_ APIM_CDC 150;
BA_ "OvtpEcuAddress" BU_ APIM_CDC 137;
BA_ "NmStationAddress" BU_ APIM_CISM 98;
BA_ "PowerType" BU_ APIM_CISM 2;
BA_ "NmAsrNode" BU_ APIM_CISM 1;
BA_ "NmAsrNodeIdentifier" BU_ APIM_CISM 226;
BA_ "NodeStartUpTime" BU_ APIM_CISM 1000;
BA_ "NodeWakeUpTime" BU_ APIM_CISM 150;
BA_ "PackageID" BU_ APIM_CISM "19.06.07.01.70.02.74.02.00.00";
BA_ "NosPackage" BU_ APIM_CISM 4;
BA_ "NmStationAddress" BU_ APIM 98;
BA_ "PowerType" BU_ APIM 2;
BA_ "NmAsrNode" BU_ APIM 1;
BA_ "NmAsrNodeIdentifier" BU_ APIM 226;
BA_ "NodeStartUpTime" BU_ APIM 1000;
BA_ "NodeWakeUpTime" BU_ APIM 150;
BA_ "PackageID" BU_ APIM "19.06.07.01.70.02.74.02.00.00";
BA_ "NosPackage" BU_ APIM 4;
BA_ "NmStationAddress" BU_ ESPM 108;
BA_ "PowerType" BU_ ESPM 2;
BA_ "NmAsrNode" BU_ ESPM 1;
BA_ "NmAsrNodeIdentifier" BU_ ESPM 108;
BA_ "NodeStartUpTime" BU_ ESPM 100;
BA_ "NodeWakeUpTime" BU_ ESPM 100;
BA_ "OvtpEcuAddress" BU_ ESPM 207;
BA_ "NmStationAddress" BU_ DSP 70;
BA_ "PowerType" BU_ DSP 2;
BA_ "NmAsrNode" BU_ DSP 1;
BA_ "NmAsrNodeIdentifier" BU_ DSP 198;
BA_ "NodeWakeUpTime" BU_ DSP 150;
BA_ "OvtpEcuAddress" BU_ DSP 9;
BA_ "NmStationAddress" BU_ APIM_CIM 98;
BA_ "PowerType" BU_ APIM_CIM 2;
BA_ "NmAsrNode" BU_ APIM_CIM 1;
BA_ "NmAsrNodeIdentifier" BU_ APIM_CIM 226;
BA_ "NodeStartUpTime" BU_ APIM_CIM 1000;
BA_ "NodeWakeUpTime" BU_ APIM_CIM 150;
BA_ "OvtpEcuAddress" BU_ APIM_CIM 137;
BA_ "NmStationAddress" BU_ FCIMB 210;
BA_ "NodeWakeUpTime" BU_ FCIMB 100;
BA_ "OvtpEcuAddress" BU_ FCIMB 71;
BA_ "NmStationAddress" BU_ RACM_RCIM 24;
BA_ "PowerType" BU_ RACM_RCIM 2;
BA_ "NmAsrNode" BU_ RACM_RCIM 1;
BA_ "NmAsrNodeIdentifier" BU_ RACM_RCIM 152;
BA_ "NodeStartUpTime" BU_ RACM_RCIM 1000;
BA_ "NodeWakeUpTime" BU_ RACM_RCIM 150;
BA_ "NmStationAddress" BU_ HUD_ADV 27;
BA_ "PowerType" BU_ HUD_ADV 2;
BA_ "NmAsrNode" BU_ HUD_ADV 1;
BA_ "NmAsrNodeIdentifier" BU_ HUD_ADV 155;
BA_ "NodeStartUpTime" BU_ HUD_ADV 74;
BA_ "NodeWakeUpTime" BU_ HUD_ADV 37;
BA_ "NmStationAddress" BU_ WCM 31;
BA_ "PowerType" BU_ WCM 2;
BA_ "NmAsrNode" BU_ WCM 1;
BA_ "NmAsrNodeIdentifier" BU_ WCM 159;
BA_ "NodeStartUpTime" BU_ WCM 1000;
BA_ "NodeWakeUpTime" BU_ WCM 150;
BA_ "NmStationAddress" BU_ TRM_ITRM 84;
BA_ "PowerType" BU_ TRM_ITRM 2;
BA_ "NmAsrNode" BU_ TRM_ITRM 1;
BA_ "NmAsrNodeIdentifier" BU_ TRM_ITRM 212;
BA_ "NodeStartUpTime" BU_ TRM_ITRM 1000;
BA_ "NodeWakeUpTime" BU_ TRM_ITRM 50;
BA_ "NmStationAddress" BU_ ACM 12;
BA_ "PowerType" BU_ ACM 2;
BA_ "NmAsrNode" BU_ ACM 1;
BA_ "NmAsrNodeIdentifier" BU_ ACM 140;
BA_ "NodeStartUpTime" BU_ ACM 1000;
BA_ "NodeWakeUpTime" BU_ ACM 150;
BA_ "NmStationAddress" BU_ GWM 30;
BA_ "PowerType" BU_ GWM 2;
BA_ "NmAsrNode" BU_ GWM 1;
BA_ "NmAsrNodeIdentifier" BU_ GWM 158;
BA_ "NodeStartUpTime" BU_ GWM 100;
BA_ "NodeWakeUpTime" BU_ GWM 100;
BA_ "Terminator" BU_ GWM 1;
BA_ "OvtpEcuAddress" BU_ GWM 216;
BA_ "OvtpOperationMode" BU_ GWM 1;
BA_ "GatewayECU" BU_ GWM 1;
BA_ "NosPackage" BU_ GWM 4;
BA_ "NodeWakeUpTime" BU_ _delete 100;
BA_ "NmStationAddress" BU_ IPC 17;
BA_ "PowerType" BU_ IPC 2;
BA_ "NmAsrNode" BU_ IPC 1;
BA_ "NmAsrNodeIdentifier" BU_ IPC 145;
BA_ "NodeStartUpTime" BU_ IPC 1000;
BA_ "NodeWakeUpTime" BU_ IPC 100;
BA_ "Terminator" BU_ IPC 1;
BA_ "OvtpEcuAddress" BU_ IPC 96;
BA_ "NosPackage" BU_ IPC 4;
BA_ "NodeWakeUpTime" BU_ GENERIC 100;
BA_ "NodeWakeUpTime" BU_ TSTR 100;
BA_ "FrameRouting" BO_ 685 "FD1_CAN,0x25E;";
BA_ "FrameRouting" BO_ 535 "FD1_CAN,0x217;";
BA_ "FrameRouting" BO_ 1225 "MS1_CAN,0x4C9;";
BA_ "FrameRouting" BO_ 573 "FD1_CAN,0x23D;";
BA_ "GenMsgILSupport" BO_ 1500 0;
BA_ "NmAsrMessage" BO_ 1500 1;
BA_ "GenMsgSendType" BO_ 1500 0;
BA_ "GenMsgCycleTime" BO_ 1500 1000;
BA_ "NetworkInitialization" BO_ 1500 0;
BA_ "GenMsgILSupport" BO_ 1885 0;
BA_ "DiagResponse" BO_ 1885 1;
BA_ "GenMsgSendType" BO_ 1885 1;
BA_ "GenMsgDelayTime" BO_ 1885 0;
BA_ "NetworkInitialization" BO_ 1885 0;
BA_ "GenMsgILSupport" BO_ 1877 0;
BA_ "DiagRequest" BO_ 1877 1;
BA_ "GenMsgSendType" BO_ 1877 1;
BA_ "GenMsgDelayTime" BO_ 1877 0;
BA_ "NetworkInitialization" BO_ 1877 0;
BA_ "TpTxIndex" BO_ 2610049240 462565592;
BA_ "GenMsgSendType" BO_ 2610049240 1;
BA_ "GenMsgDelayTime" BO_ 2610049240 0;
BA_ "NetworkInitialization" BO_ 2610049240 0;
BA_ "TpTxIndex" BO_ 2610126988 462565592;
BA_ "GenMsgSendType" BO_ 2610126988 1;
BA_ "GenMsgDelayTime" BO_ 2610126988 0;
BA_ "NetworkInitialization" BO_ 2610126988 0;
BA_ "TpTxIndex" BO_ 2611097816 463614168;
BA_ "GenMsgSendType" BO_ 2611097816 1;
BA_ "GenMsgDelayTime" BO_ 2611097816 0;
BA_ "NetworkInitialization" BO_ 2611097816 0;
BA_ "TpTxIndex" BO_ 2611175564 463614168;
BA_ "GenMsgSendType" BO_ 2611175564 1;
BA_ "GenMsgDelayTime" BO_ 2611175564 0;
BA_ "NetworkInitialization" BO_ 2611175564 0;
BA_ "OvtpPushApplication" BO_ 2612146392 1;
BA_ "TpTxIndex" BO_ 2612146392 464662744;
BA_ "GenMsgSendType" BO_ 2612146392 1;
BA_ "GenMsgDelayTime" BO_ 2612146392 0;
BA_ "NetworkInitialization" BO_ 2612146392 0;
BA_ "OvtpPushApplication" BO_ 2612224140 1;
BA_ "TpTxIndex" BO_ 2612224140 464662744;
BA_ "GenMsgSendType" BO_ 2612224140 1;
BA_ "GenMsgDelayTime" BO_ 2612224140 0;
BA_ "NetworkInitialization" BO_ 2612224140 0;
BA_ "TpTxIndex" BO_ 2613194968 465711320;
BA_ "GenMsgSendType" BO_ 2613194968 1;
BA_ "GenMsgDelayTime" BO_ 2613194968 0;
BA_ "NetworkInitialization" BO_ 2613194968 0;
BA_ "TpTxIndex" BO_ 2613272716 465711320;
BA_ "GenMsgSendType" BO_ 2613272716 1;
BA_ "GenMsgDelayTime" BO_ 2613272716 0;
BA_ "NetworkInitialization" BO_ 2613272716 0;
BA_ "FrameRouting" BO_ 1212 "FD1_CAN,0x4BC;";
BA_ "GenMsgSendType" BO_ 1211 5;
BA_ "GenMsgCycleTime" BO_ 1211 1000;
BA_ "GenMsgSendType" BO_ 509 5;
BA_ "GenMsgCycleTime" BO_ 509 500;
BA_ "FrameRouting" BO_ 980 "HS2_CAN,0x2E4;";
BA_ "GenMsgILSupport" BO_ 1310 0;
BA_ "NmMessage" BO_ 1310 1;
BA_ "GenMsgSendType" BO_ 1310 1;
BA_ "NetworkInitialization" BO_ 1310 0;
BA_ "GenMsgILSupport" BO_ 1304 0;
BA_ "NmMessage" BO_ 1304 1;
BA_ "GenMsgSendType" BO_ 1304 1;
BA_ "NetworkInitialization" BO_ 1304 0;
BA_ "FrameRouting" BO_ 668 "MS1_CAN,0x29C;";
BA_ "FrameRouting" BO_ 640 "MS1_CAN,0x280;";
BA_ "FrameRouting" BO_ 1204 "FD1_CAN,0x4B4;";
BA_ "FrameRouting" BO_ 826 "FD3_CAN,0x33A;";
BA_ "FrameRouting" BO_ 1159 "FD2_CAN,0x487;";
BA_ "FrameRouting" BO_ 1258 "MS2_CAN,0x4EA;";
BA_ "GenMsgSendType" BO_ 648 5;
BA_ "GenMsgCycleTime" BO_ 648 1000;
BA_ "FrameRouting" BO_ 1229 "FD1_CAN,0x4CD;FD3_CAN,0x4CD";
BA_ "GenMsgSendType" BO_ 1246 5;
BA_ "GenMsgCycleTime" BO_ 1246 100;
BA_ "FrameRouting" BO_ 1157 "MS2_CAN,0x485;";
BA_ "FrameRouting" BO_ 1158 "MS2_CAN,0x486;";
BA_ "GenMsgSendType" BO_ 1208 5;
BA_ "GenMsgCycleTime" BO_ 1208 1000;
BA_ "GenMsgSendType" BO_ 1266 5;
BA_ "GenMsgCycleTime" BO_ 1266 1000;
BA_ "FrameRouting" BO_ 1263 "MS1_CAN,0x4EF;";
BA_ "FrameRouting" BO_ 1262 "MS1_CAN,0x4EE;";
BA_ "TpTxIndex" BO_ 667 125;
BA_ "FrameRouting" BO_ 667 "FD2_CAN,0x29B;";
BA_ "TpTxIndex" BO_ 659 125;
BA_ "GenMsgSendType" BO_ 645 0;
BA_ "GenMsgCycleTime" BO_ 645 100;
BA_ "FrameRouting" BO_ 1040 "FD1_CAN,0x410;";
BA_ "GenMsgSendType" BO_ 630 0;
BA_ "GenMsgCycleTime" BO_ 630 100;
BA_ "GenMsgSendType" BO_ 627 0;
BA_ "GenMsgCycleTime" BO_ 627 100;
BA_ "GenMsgSendType" BO_ 874 5;
BA_ "GenMsgCycleTime" BO_ 874 1000;
BA_ "FrameRouting" BO_ 663 "FD1_CAN,0x297;";
BA_ "FrameRouting" BO_ 1161 "HS2_CAN,0x489;";
BA_ "FrameRouting" BO_ 1121 "HS2_CAN,0x461;";
BA_ "FrameRouting" BO_ 669 "FD3_CAN,0x29D;";
BA_ "FrameRouting" BO_ 571 "FD1_CAN,0x23B;";
BA_ "FrameRouting" BO_ 118 "FD1_CAN,0x76;";
BA_ "FrameRouting" BO_ 868 "MS1_CAN,0x364;";
BA_ "FrameRouting" BO_ 836 "MS1_CAN,0x344;";
BA_ "FrameRouting" BO_ 613 "HS2_CAN,0x265;";
BA_ "FrameRouting" BO_ 1084 "FD1_CAN,0x43C;";
BA_ "FrameRouting" BO_ 1059 "FD1_CAN,0x42C;";
BA_ "FrameRouting" BO_ 131 "FD3_CAN,0x83;";
BA_ "FrameRouting" BO_ 931 "FD1_CAN,0x3A3;";
BA_ "FrameRouting" BO_ 618 "FD2_CAN,0x26A;";
BA_ "FrameRouting" BO_ 621 "FD2_CAN,0x26D;";
BA_ "FrameRouting" BO_ 1016 "FD1_CAN,0x3F8;";
BA_ "FrameRouting" BO_ 773 "MS1_CAN,0x305;";
BA_ "FrameRouting" BO_ 389 "FD1_CAN,0x185;";
BA_ "FrameRouting" BO_ 1128 "HS2_CAN,0x45E;";
BA_ "FrameRouting" BO_ 594 "HS2_CAN,0x24C;";
BA_ "TpTxIndex" BO_ 2614099160 466615512;
BA_ "GenMsgSendType" BO_ 2614099160 1;
BA_ "GenMsgDelayTime" BO_ 2614099160 0;
BA_ "NetworkInitialization" BO_ 2614099160 0;
BA_ "TpTxIndex" BO_ 2610117848 462634200;
BA_ "GenMsgSendType" BO_ 2610117848 1;
BA_ "GenMsgDelayTime" BO_ 2610117848 0;
BA_ "NetworkInitialization" BO_ 2610117848 0;
BA_ "TpTxIndex" BO_ 2610127055 462634200;
BA_ "GenMsgSendType" BO_ 2610127055 1;
BA_ "GenMsgDelayTime" BO_ 2610127055 0;
BA_ "NetworkInitialization" BO_ 2610127055 0;
BA_ "TpTxIndex" BO_ 2611175631 463682776;
BA_ "GenMsgSendType" BO_ 2611175631 1;
BA_ "GenMsgDelayTime" BO_ 2611175631 0;
BA_ "NetworkInitialization" BO_ 2611175631 0;
BA_ "OvtpPushApplication" BO_ 2612215000 1;
BA_ "TpTxIndex" BO_ 2612215000 464731352;
BA_ "GenMsgSendType" BO_ 2612215000 1;
BA_ "GenMsgDelayTime" BO_ 2612215000 0;
BA_ "NetworkInitialization" BO_ 2612215000 0;
BA_ "OvtpPushApplication" BO_ 2612224207 1;
BA_ "TpTxIndex" BO_ 2612224207 464731352;
BA_ "GenMsgSendType" BO_ 2612224207 1;
BA_ "GenMsgDelayTime" BO_ 2612224207 0;
BA_ "NetworkInitialization" BO_ 2612224207 0;
BA_ "TpTxIndex" BO_ 2613263576 465779928;
BA_ "GenMsgSendType" BO_ 2613263576 1;
BA_ "GenMsgDelayTime" BO_ 2613263576 0;
BA_ "NetworkInitialization" BO_ 2613263576 0;
BA_ "TpTxIndex" BO_ 2613272783 465779928;
BA_ "GenMsgSendType" BO_ 2613272783 1;
BA_ "GenMsgDelayTime" BO_ 2613272783 0;
BA_ "NetworkInitialization" BO_ 2613272783 0;
BA_ "FrameRouting" BO_ 932 "FD1_CAN,0x3A4;";
BA_ "GenMsgILSupport" BO_ 1388 0;
BA_ "NmAsrMessage" BO_ 1388 1;
BA_ "GenMsgSendType" BO_ 1388 0;
BA_ "GenMsgCycleTime" BO_ 1388 1000;
BA_ "NetworkInitialization" BO_ 1388 0;
BA_ "DiagResponse" BO_ 1769 1;
BA_ "GenMsgSendType" BO_ 1769 1;
BA_ "GenMsgDelayTime" BO_ 1769 0;
BA_ "NetworkInitialization" BO_ 1769 0;
BA_ "DiagRequest" BO_ 1761 1;
BA_ "GenMsgSendType" BO_ 1761 1;
BA_ "GenMsgDelayTime" BO_ 1761 0;
BA_ "NetworkInitialization" BO_ 1761 0;
BA_ "FrameRouting" BO_ 528 "FD1_CAN,0x210;";
BA_ "FrameRouting" BO_ 591 "HS2_CAN,0x24F;";
BA_ "GenMsgCycleTime" BO_ 595 500;
BA_ "FrameRouting" BO_ 596 "FD3_CAN,0x254;";
BA_ "FrameRouting" BO_ 966 "FD1_CAN,0x3C6;";
BA_ "FrameRouting" BO_ 1104 "FD3_CAN,0x450;";
BA_ "FrameRouting" BO_ 303 "FD1_CAN,0x12F;";
BA_ "OvtpPushApplication" BO_ 2612224006 1;
BA_ "TpTxIndex" BO_ 2612224006 464525528;
BA_ "GenMsgSendType" BO_ 2612224006 1;
BA_ "GenMsgDelayTime" BO_ 2612224006 0;
BA_ "NetworkInitialization" BO_ 2612224006 0;
BA_ "OvtpPushApplication" BO_ 2612009176 1;
BA_ "TpTxIndex" BO_ 2612009176 464525528;
BA_ "GenMsgSendType" BO_ 2612009176 1;
BA_ "GenMsgDelayTime" BO_ 2612009176 0;
BA_ "NetworkInitialization" BO_ 2612009176 0;
BA_ "TpTxIndex" BO_ 2611175430 463476952;
BA_ "GenMsgSendType" BO_ 2611175430 1;
BA_ "GenMsgDelayTime" BO_ 2611175430 0;
BA_ "NetworkInitialization" BO_ 2611175430 0;
BA_ "TpTxIndex" BO_ 2610960600 463476952;
BA_ "GenMsgSendType" BO_ 2610960600 1;
BA_ "GenMsgDelayTime" BO_ 2610960600 0;
BA_ "NetworkInitialization" BO_ 2610960600 0;
BA_ "TpTxIndex" BO_ 2610126854 462428376;
BA_ "GenMsgSendType" BO_ 2610126854 1;
BA_ "GenMsgDelayTime" BO_ 2610126854 0;
BA_ "NetworkInitialization" BO_ 2610126854 0;
BA_ "TpTxIndex" BO_ 2609912024 462428376;
BA_ "GenMsgSendType" BO_ 2609912024 1;
BA_ "GenMsgDelayTime" BO_ 2609912024 0;
BA_ "NetworkInitialization" BO_ 2609912024 0;
BA_ "GenSigStartValue" SG_ 1259 RgstrVertIbr_An_Rq 75;
BA_ "GenSigSendType" SG_ 1259 RgstrVertIbr_An_Rq 3;
BA_ "U_P702_MY2024_Tx" SG_ 1259 RgstrVertIbr_An_Rq 1;
BA_ "GenSigStartValue" SG_ 1259 RgstrVertObr_An_Rq 75;
BA_ "GenSigSendType" SG_ 1259 RgstrVertObr_An_Rq 3;
BA_ "U_P702_MY2024_Tx" SG_ 1259 RgstrVertObr_An_Rq 1;
BA_ "GenSigStartValue" SG_ 1259 RgstrVertIbl_An_Rq 75;
BA_ "GenSigSendType" SG_ 1259 RgstrVertIbl_An_Rq 3;
BA_ "U_P702_MY2024_Tx" SG_ 1259 RgstrVertIbl_An_Rq 1;
BA_ "GenSigStartValue" SG_ 1259 RgstrVertObl_An_Rq 75;
BA_ "GenSigSendType" SG_ 1259 RgstrVertObl_An_Rq 3;
BA_ "U_P702_MY2024_Tx" SG_ 1259 RgstrVertObl_An_Rq 1;
BA_ "GenSigStartValue" SG_ 1259 RgstrHzntlIbr_An_Rq 30;
BA_ "GenSigSendType" SG_ 1259 RgstrHzntlIbr_An_Rq 3;
BA_ "U_P702_MY2024_Tx" SG_ 1259 RgstrHzntlIbr_An_Rq 1;
BA_ "GenSigStartValue" SG_ 1259 RgstrHzntlObr_An_Rq 30;
BA_ "GenSigSendType" SG_ 1259 RgstrHzntlObr_An_Rq 3;
BA_ "U_P702_MY2024_Tx" SG_ 1259 RgstrHzntlObr_An_Rq 1;
BA_ "GenSigStartValue" SG_ 1259 RgstrHzntlIbl_An_Rq 30;
BA_ "GenSigSendType" SG_ 1259 RgstrHzntlIbl_An_Rq 3;
BA_ "U_P702_MY2024_Tx" SG_ 1259 RgstrHzntlIbl_An_Rq 1;
BA_ "GenSigStartValue" SG_ 1259 RgstrHzntlObl_An_Rq 30;
BA_ "GenSigSendType" SG_ 1259 RgstrHzntlObl_An_Rq 3;
BA_ "U_P702_MY2024_Tx" SG_ 1259 RgstrHzntlObl_An_Rq 1;
BA_ "GenSigStartValue" SG_ 1225 RgstrVertIbr_An_Actl 75;
BA_ "U_P702_MY2024_Rx" SG_ 1225 RgstrVertIbr_An_Actl 1;
BA_ "GenSigStartValue" SG_ 1225 RgstrVertObr_An_Actl 75;
BA_ "U_P702_MY2024_Rx" SG_ 1225 RgstrVertObr_An_Actl 1;
BA_ "GenSigStartValue" SG_ 1225 RgstrVertIbl_An_Actl 75;
BA_ "U_P702_MY2024_Rx" SG_ 1225 RgstrVertIbl_An_Actl 1;
BA_ "GenSigStartValue" SG_ 1225 RgstrVertObl_An_Actl 75;
BA_ "U_P702_MY2024_Rx" SG_ 1225 RgstrVertObl_An_Actl 1;
BA_ "GenSigStartValue" SG_ 1225 RgstrHzntlIbr_An_Actl 30;
BA_ "U_P702_MY2024_Rx" SG_ 1225 RgstrHzntlIbr_An_Actl 1;
BA_ "GenSigStartValue" SG_ 1225 RgstrHzntlObr_An_Actl 30;
BA_ "U_P702_MY2024_Rx" SG_ 1225 RgstrHzntlObr_An_Actl 1;
BA_ "GenSigStartValue" SG_ 1225 RgstrHzntlIbl_An_Actl 30;
BA_ "U_P702_MY2024_Rx" SG_ 1225 RgstrHzntlIbl_An_Actl 1;
BA_ "GenSigStartValue" SG_ 1225 RgstrHzntlObl_An_Actl 30;
BA_ "U_P702_MY2024_Rx" SG_ 1225 RgstrHzntlObl_An_Actl 1;
BA_ "WakeupSignal" SG_ 573 VehStrtKeyType_D_Stat 1;
BA_ "WakeupSignal" SG_ 573 VehStrtKeySrc_D_Stat 1;
BA_ "WakeupSignal" SG_ 573 VehStrtKeyIndx_No_Actl 1;
BA_ "GenSigStartValue" SG_ 1500 ARM_GWOnBoardTester 255;
BA_ "GenSigStartValue" SG_ 1500 ARM_GWNMProxy 255;
BA_ "GenSigStartValue" SG_ 1500 ARM_AutoSarNMReserved4 255;
BA_ "GenSigStartValue" SG_ 1500 ARM_AutoSarNMReserved3 255;
BA_ "GenSigStartValue" SG_ 1500 ARM_AutoSarNMReserved2 255;
BA_ "GenSigStartValue" SG_ 1500 ARM_AutoSarNMReserved1 255;
BA_ "GenSigStartValue" SG_ 1500 ARM_AutoSarNMNodeId 220;
BA_ "GenSigSendType" SG_ 1885 TesterPhysicalResARM 3;
BA_ "GenSigSendType" SG_ 1877 TesterPhysicalReqARM 3;
BA_ "GenSigSendType" SG_ 2610049240 OTAPhysGWM_ECGtoRACM 3;
BA_ "ECGUsedTxSignal" SG_ 2610049240 OTAPhysGWM_ECGtoRACM 1;
BA_ "GenSigSendType" SG_ 2610126988 OTAPhysRACMtoGWM_ECG 3;
BA_ "ECGUsedRxSignal" SG_ 2610126988 OTAPhysRACMtoGWM_ECG 1;
BA_ "GenSigSendType" SG_ 2611097816 PARSEDPhysGWM_ECGtoRACM 3;
BA_ "ECGUsedTxSignal" SG_ 2611097816 PARSEDPhysGWM_ECGtoRACM 1;
BA_ "GenSigSendType" SG_ 2611175564 PARSEDPhysRACMtoGWM_ECG 3;
BA_ "ECGUsedRxSignal" SG_ 2611175564 PARSEDPhysRACMtoGWM_ECG 1;
BA_ "GenSigSendType" SG_ 2612146392 PARSEDPushFcGWM_ECGtoRACM 3;
BA_ "ECGUsedTxSignal" SG_ 2612146392 PARSEDPushFcGWM_ECGtoRACM 1;
BA_ "GenSigSendType" SG_ 2612224140 PARSEDPushRACMtoGWM_ECG 3;
BA_ "ECGUsedRxSignal" SG_ 2612224140 PARSEDPushRACMtoGWM_ECG 1;
BA_ "GenSigSendType" SG_ 2613194968 SymKeyPhysGWM_ECGtoRACM 3;
BA_ "ECGUsedTxSignal" SG_ 2613194968 SymKeyPhysGWM_ECGtoRACM 1;
BA_ "GenSigSendType" SG_ 2613272716 SymKeyPhysRACMtoGWM_ECG 3;
BA_ "ECGUsedRxSignal" SG_ 2613272716 SymKeyPhysRACMtoGWM_ECG 1;
BA_ "GenSigSendType" SG_ 1212 PersPrfl_D_Stat 3;
BA_ "U_P702_MY2024_Rx" SG_ 1212 PersPrfl_D_Stat 1;
BA_ "GenSigSendType" SG_ 1212 PersDgtlKey4_D_Stat 3;
BA_ "U_P702_MY2024_Rx" SG_ 1212 PersDgtlKey4_D_Stat 1;
BA_ "GenSigSendType" SG_ 1212 PersDgtlKey3_D_Stat 3;
BA_ "U_P702_MY2024_Rx" SG_ 1212 PersDgtlKey3_D_Stat 1;
BA_ "GenSigSendType" SG_ 1212 PersDgtlKey2_D_Stat 3;
BA_ "U_P702_MY2024_Rx" SG_ 1212 PersDgtlKey2_D_Stat 1;
BA_ "GenSigSendType" SG_ 1212 PersDgtlKey1_D_Stat 3;
BA_ "U_P702_MY2024_Rx" SG_ 1212 PersDgtlKey1_D_Stat 1;
BA_ "GenSigStartValue" SG_ 1211 FrtTe_An_Actl 511;
BA_ "GenSigSendType" SG_ 1211 FrtTe_An_Actl 3;
BA_ "GenSigStartValue" SG_ 1211 FrtBlwr_An_Actl 511;
BA_ "GenSigSendType" SG_ 1211 FrtBlwr_An_Actl 3;
BA_ "GenSigSendType" SG_ 1211 E_Voice_Blower_Limit 3;
BA_ "GenSigSendType" SG_ 1211 E_Rr_Btn_Status_2nd 3;
BA_ "U_V710_MY2023_Rx" SG_ 1211 E_Rr_Btn_Status_2nd 1;
BA_ "U_P708_MY2023_Rx" SG_ 1211 E_Rr_Btn_Status_2nd 1;
BA_ "U_P702_MY2024_Rx" SG_ 1211 E_Rr_Btn_Status_2nd 1;
BA_ "GenSigSendType" SG_ 1211 E_Rr_Btn_Status_1st 3;
BA_ "U_V710_MY2023_Rx" SG_ 1211 E_Rr_Btn_Status_1st 1;
BA_ "U_P708_MY2023_Rx" SG_ 1211 E_Rr_Btn_Status_1st 1;
BA_ "U_P702_MY2024_Rx" SG_ 1211 E_Rr_Btn_Status_1st 1;
BA_ "GenSigSendType" SG_ 1211 E_Frt_Btn_Status_2nd 3;
BA_ "U_V710_MY2023_Rx" SG_ 1211 E_Frt_Btn_Status_2nd 1;
BA_ "U_P708_MY2023_Rx" SG_ 1211 E_Frt_Btn_Status_2nd 1;
BA_ "U_P702_MY2024_Rx" SG_ 1211 E_Frt_Btn_Status_2nd 1;
BA_ "GenSigSendType" SG_ 1211 E_Frt_Btn_Status_1st 3;
BA_ "U_V710_MY2023_Rx" SG_ 1211 E_Frt_Btn_Status_1st 1;
BA_ "U_P708_MY2023_Rx" SG_ 1211 E_Frt_Btn_Status_1st 1;
BA_ "U_P702_MY2024_Rx" SG_ 1211 E_Frt_Btn_Status_1st 1;
BA_ "GenSigSendType" SG_ 1211 E_Frt_Blwr_Speed 3;
BA_ "GenSigSendType" SG_ 1211 E_Drv_Set_Temp 3;
BA_ "GenSigSendType" SG_ 509 TrakAppl_D_Stat 3;
BA_ "GenSigStartValue" SG_ 980 BattDcChrg_U_Actl 1022;
BA_ "U_P702_MY2024_Rx" SG_ 980 BattTracSoc_Pc_Dpltd 1;
BA_ "WakeupSignal" SG_ 980 PtWakeupActv2_B_Rq 1;
BA_ "GenSigSendType" SG_ 1310 GWM_Network_Mgmt_HS3 3;
BA_ "ECGUsedTxSignal" SG_ 1310 GWM_Network_Mgmt_HS3 1;
BA_ "GenSigSendType" SG_ 1304 RACM_REM3_Network_Mgmt 3;
BA_ "U_P708_MY2023_Rx" SG_ 1204 DcacElPwScnd_D_Stat 1;
BA_ "U_P702_MY2024_Rx" SG_ 1204 DcacElPwScnd_D_Stat 1;
BA_ "U_P708_MY2023_Rx" SG_ 1204 DcacEngOnMsgTxt_D2_Rq 1;
BA_ "U_P702_MY2024_Rx" SG_ 1204 DcacEngOnMsgTxt_D2_Rq 1;
BA_ "U_P708_MY2023_Rx" SG_ 1204 DcacOutScnd_Pw_DsplyMx 1;
BA_ "U_P702_MY2024_Rx" SG_ 1204 DcacOutScnd_Pw_DsplyMx 1;
BA_ "U_P708_MY2023_Rx" SG_ 1204 DcacOutScnd_Pw2_Dsply 1;
BA_ "U_P702_MY2024_Rx" SG_ 1204 DcacOutScnd_Pw2_Dsply 1;
BA_ "U_P708_MY2023_Rx" SG_ 1204 DcacZone3Pw_B_Stat 1;
BA_ "U_P702_MY2024_Rx" SG_ 1204 DcacZone3Pw_B_Stat 1;
BA_ "U_P708_MY2023_Rx" SG_ 1204 DcacZone2Pw_B_Stat 1;
BA_ "U_P702_MY2024_Rx" SG_ 1204 DcacZone2Pw_B_Stat 1;
BA_ "WakeupSignal" SG_ 826 Memory_3_Sw_Stat 1;
BA_ "WakeupSignal" SG_ 826 Memory_2_Sw_Stat 1;
BA_ "WakeupSignal" SG_ 826 Memory_1_Sw_Stat 1;
BA_ "WakeupSignal" SG_ 826 Mirror_Manual_Override 1;
BA_ "GenSigStartValue" SG_ 1159 FourthRowBucklePsngr2 4;
BA_ "GenSigStartValue" SG_ 1159 FourthRowBuckleMid2 4;
BA_ "GenSigStartValue" SG_ 1159 FourthRowBuckleDriver2 4;
BA_ "GenSigStartValue" SG_ 1159 ThirdRowBucklePsngr2 4;
BA_ "GenSigStartValue" SG_ 1159 ThirdRowBuckleMid2 4;
BA_ "GenSigStartValue" SG_ 1159 ThirdRowBuckleDriver2 4;
BA_ "GenSigStartValue" SG_ 1159 SecondRowBucklePsngr2 4;
BA_ "GenSigStartValue" SG_ 1159 SecondRowBuckleMid2 4;
BA_ "GenSigStartValue" SG_ 1159 SecondRowBuckleDriver2 4;
BA_ "U_P702_MY2024_Rx" SG_ 1258 TrlrCamraCalib_D_Stat 1;
BA_ "U_P702_MY2024_Rx" SG_ 1258 TrlrCamraView_D_Stat 1;
BA_ "GenSigSendType" SG_ 648 TrlrCamraCalib_D_Rq 3;
BA_ "GenSigSendType" SG_ 648 HitchToTrlrBox_L_Actl 3;
BA_ "GenSigSendType" SG_ 648 TrlrWidth_L_Actl 3;
BA_ "GenSigSendType" SG_ 648 TrlrCamraHght_L_Actl 3;
BA_ "U_P702_MY2024_Rx" SG_ 1229 TrlrIspCnnct_D_Stat 1;
BA_ "GenSigSendType" SG_ 1246 TrlrBrkCtl2_B_Falt 3;
BA_ "U_CDX707_MY2023_Tx" SG_ 1246 TrlrBrkCtl2_B_Falt 1;
BA_ "U_P702_MY2024_Tx" SG_ 1246 TrlrBrkCtl2_B_Falt 1;
BA_ "GenSigSendType" SG_ 1246 TrlrBrkCtl2BFalt_No_Cnt 3;
BA_ "U_CDX707_MY2023_Tx" SG_ 1246 TrlrBrkCtl2BFalt_No_Cnt 1;
BA_ "U_P702_MY2024_Tx" SG_ 1246 TrlrBrkCtl2BFalt_No_Cnt 1;
BA_ "GenSigSendType" SG_ 1246 TrlrBrkCtl2BFalt_No_Cs 3;
BA_ "U_CDX707_MY2023_Tx" SG_ 1246 TrlrBrkCtl2BFalt_No_Cs 1;
BA_ "U_P702_MY2024_Tx" SG_ 1246 TrlrBrkCtl2BFalt_No_Cs 1;
BA_ "GenSigSendType" SG_ 1208 StopStrtImccSel_B_Rq 3;
BA_ "GenSigSendType" SG_ 1208 StopStrtImccTxt_D_Stat 3;
BA_ "GenSigSendType" SG_ 1208 StopStrtImccSel_B_Falt 3;
BA_ "GenSigStartValue" SG_ 1208 Btt_L2_Actl2 124;
BA_ "GenSigSendType" SG_ 1208 Btt_L2_Actl2 3;
BA_ "GenSigSendType" SG_ 1266 CabnScentCalbType_No_Rq 3;
BA_ "U_P702_MY2024_Tx" SG_ 1266 CabnScentCalbType_No_Rq 1;
BA_ "GenSigSendType" SG_ 1266 CabnScentCalibVal_No_Rq 3;
BA_ "U_P702_MY2024_Tx" SG_ 1266 CabnScentCalibVal_No_Rq 1;
BA_ "U_P702_MY2024_Rx" SG_ 1263 ActvButtnRight_D_Stat 1;
BA_ "U_P702_MY2024_Rx" SG_ 1263 ActvButtnLeft_D_Stat 1;
BA_ "U_P702_MY2024_Rx" SG_ 1263 CabnScentTeMsgTxt_D_Rq 1;
BA_ "U_P702_MY2024_Rx" SG_ 1263 CabnScentSplr_D_Stat 1;
BA_ "U_P702_MY2024_Rx" SG_ 1263 CabnScentMde_D_Stat 1;
BA_ "U_P702_MY2024_Rx" SG_ 1263 CabnScentIntns_D_Stat 1;
BA_ "U_P702_MY2024_Rx" SG_ 1263 CabnScentChnl_D_Stat 1;
BA_ "U_P702_MY2024_Rx" SG_ 1263 CabnScent5Type_No_Actl 1;
BA_ "U_P702_MY2024_Rx" SG_ 1263 CabnScent4Type_No_Actl 1;
BA_ "U_P702_MY2024_Rx" SG_ 1263 CabnScent3Type_No_Actl 1;
BA_ "U_P702_MY2024_Rx" SG_ 1263 CabnScent2Type_No_Actl 1;
BA_ "U_P702_MY2024_Rx" SG_ 1263 CabnScent1Type_No_Actl 1;
BA_ "GenSigStartValue" SG_ 1262 CabnScent5Life_Pc_Actl 127;
BA_ "U_P702_MY2024_Rx" SG_ 1262 CabnScent5Life_Pc_Actl 1;
BA_ "GenSigStartValue" SG_ 1262 CabnScent4Life_Pc_Actl 127;
BA_ "U_P702_MY2024_Rx" SG_ 1262 CabnScent4Life_Pc_Actl 1;
BA_ "GenSigStartValue" SG_ 1262 CabnScent3Life_Pc_Actl 127;
BA_ "U_P702_MY2024_Rx" SG_ 1262 CabnScent3Life_Pc_Actl 1;
BA_ "GenSigStartValue" SG_ 1262 CabnScent2Life_Pc_Actl 127;
BA_ "U_P702_MY2024_Rx" SG_ 1262 CabnScent2Life_Pc_Actl 1;
BA_ "GenSigStartValue" SG_ 1262 CabnScent1Life_Pc_Actl 127;
BA_ "U_P702_MY2024_Rx" SG_ 1262 CabnScent1Life_Pc_Actl 1;
BA_ "U_P708_MY2023_Rx" SG_ 667 APIM_NFAM_Word_Rx 1;
BA_ "U_P708_MY2023_Tx" SG_ 659 APIM_NFAM_Word_Tx 1;
BA_ "U_P702_MY2024_Tx" SG_ 659 APIM_NFAM_Word_Tx 1;
BA_ "U_V710_MY2023_Rx" SG_ 645 VehImpactCode_No2_Actl 1;
BA_ "U_P708_MY2023_Rx" SG_ 645 VehImpactCode_No2_Actl 1;
BA_ "U_P702_MY2024_Rx" SG_ 645 VehImpactCode_No2_Actl 1;
BA_ "ECGUsedTxSignal" SG_ 645 VehImpactCode_No2_Actl 1;
BA_ "U_CDX74X_MY2024_Tx" SG_ 645 VehImpactCode_No2_Actl 1;
BA_ "U_V710_MY2023_Tx" SG_ 645 VehImpactCode_No2_Actl 1;
BA_ "GenSigStartValue" SG_ 1040 RoadGrd_Pc_Est 1023;
BA_ "GenSigStartValue" SG_ 1040 VehSimSnd_Pc_Rq 511;
BA_ "U_P708_MY2023_Rx" SG_ 1040 VehSimSnd_Pc_Rq 1;
BA_ "GenSigStartValue" SG_ 1040 BattTrac_I2_EstVsc 262142;
BA_ "U_V710_MY2023_Tx" SG_ 630 TrfcLghtUturnType_D_St 1;
BA_ "U_P708_MY2023_Tx" SG_ 630 TrfcLghtUturnType_D_St 1;
BA_ "U_P702_MY2024_Tx" SG_ 630 TrfcLghtUturnType_D_St 1;
BA_ "U_V710_MY2023_Tx" SG_ 630 TrfcLghtUturnOn_D_Stat 1;
BA_ "U_P708_MY2023_Tx" SG_ 630 TrfcLghtUturnOn_D_Stat 1;
BA_ "U_P702_MY2024_Tx" SG_ 630 TrfcLghtUturnOn_D_Stat 1;
BA_ "U_V710_MY2023_Tx" SG_ 630 TrfcLghtUturnColr_D_St 1;
BA_ "U_P708_MY2023_Tx" SG_ 630 TrfcLghtUturnColr_D_St 1;
BA_ "U_P702_MY2024_Tx" SG_ 630 TrfcLghtUturnColr_D_St 1;
BA_ "GenSigStartValue" SG_ 630 TrfcLghtUturn_T_Actl 254;
BA_ "U_V710_MY2023_Tx" SG_ 630 TrfcLghtUturn_T_Actl 1;
BA_ "U_P708_MY2023_Tx" SG_ 630 TrfcLghtUturn_T_Actl 1;
BA_ "U_P702_MY2024_Tx" SG_ 630 TrfcLghtUturn_T_Actl 1;
BA_ "U_V710_MY2023_Tx" SG_ 630 TrfcLghtRightType_D_St 1;
BA_ "U_P708_MY2023_Tx" SG_ 630 TrfcLghtRightType_D_St 1;
BA_ "U_P702_MY2024_Tx" SG_ 630 TrfcLghtRightType_D_St 1;
BA_ "U_V710_MY2023_Tx" SG_ 630 TrfcLghtRightOn_D_Stat 1;
BA_ "U_P708_MY2023_Tx" SG_ 630 TrfcLghtRightOn_D_Stat 1;
BA_ "U_P702_MY2024_Tx" SG_ 630 TrfcLghtRightOn_D_Stat 1;
BA_ "U_V710_MY2023_Tx" SG_ 630 TrfcLghtRightColr_D_St 1;
BA_ "U_P708_MY2023_Tx" SG_ 630 TrfcLghtRightColr_D_St 1;
BA_ "U_P702_MY2024_Tx" SG_ 630 TrfcLghtRightColr_D_St 1;
BA_ "GenSigStartValue" SG_ 630 TrfcLghtRight_T_Actl 254;
BA_ "U_V710_MY2023_Tx" SG_ 630 TrfcLghtRight_T_Actl 1;
BA_ "U_P708_MY2023_Tx" SG_ 630 TrfcLghtRight_T_Actl 1;
BA_ "U_P702_MY2024_Tx" SG_ 630 TrfcLghtRight_T_Actl 1;
BA_ "U_V710_MY2023_Tx" SG_ 630 TrfcLghtLeftType_D_Stat 1;
BA_ "U_P708_MY2023_Tx" SG_ 630 TrfcLghtLeftType_D_Stat 1;
BA_ "U_P702_MY2024_Tx" SG_ 630 TrfcLghtLeftType_D_Stat 1;
BA_ "U_V710_MY2023_Tx" SG_ 630 TrfcLghtLeftOn_D_Stat 1;
BA_ "U_P708_MY2023_Tx" SG_ 630 TrfcLghtLeftOn_D_Stat 1;
BA_ "U_P702_MY2024_Tx" SG_ 630 TrfcLghtLeftOn_D_Stat 1;
BA_ "U_V710_MY2023_Tx" SG_ 630 TrfcLghtLeftColr_D_Stat 1;
BA_ "U_P708_MY2023_Tx" SG_ 630 TrfcLghtLeftColr_D_Stat 1;
BA_ "U_P702_MY2024_Tx" SG_ 630 TrfcLghtLeftColr_D_Stat 1;
BA_ "GenSigStartValue" SG_ 630 TrfcLghtLeft_T_Actl 254;
BA_ "U_V710_MY2023_Tx" SG_ 630 TrfcLghtLeft_T_Actl 1;
BA_ "U_P708_MY2023_Tx" SG_ 630 TrfcLghtLeft_T_Actl 1;
BA_ "U_P702_MY2024_Tx" SG_ 630 TrfcLghtLeft_T_Actl 1;
BA_ "U_V710_MY2023_Tx" SG_ 630 TrfcLghtStrghtType_D_St 1;
BA_ "U_P708_MY2023_Tx" SG_ 630 TrfcLghtStrghtType_D_St 1;
BA_ "U_P702_MY2024_Tx" SG_ 630 TrfcLghtStrghtType_D_St 1;
BA_ "U_V710_MY2023_Tx" SG_ 630 TrfcLghtStrghtOn_D_Stat 1;
BA_ "U_P708_MY2023_Tx" SG_ 630 TrfcLghtStrghtOn_D_Stat 1;
BA_ "U_P702_MY2024_Tx" SG_ 630 TrfcLghtStrghtOn_D_Stat 1;
BA_ "U_V710_MY2023_Tx" SG_ 630 TrfcLghtStrghtColr_D_St 1;
BA_ "U_P708_MY2023_Tx" SG_ 630 TrfcLghtStrghtColr_D_St 1;
BA_ "U_P702_MY2024_Tx" SG_ 630 TrfcLghtStrghtColr_D_St 1;
BA_ "GenSigStartValue" SG_ 630 TrfcLghtStrght_T_Actl 254;
BA_ "U_V710_MY2023_Tx" SG_ 630 TrfcLghtStrght_T_Actl 1;
BA_ "U_P708_MY2023_Tx" SG_ 630 TrfcLghtStrght_T_Actl 1;
BA_ "U_P702_MY2024_Tx" SG_ 630 TrfcLghtStrght_T_Actl 1;
BA_ "GenSigStartValue" SG_ 627 VehToInfrstrctr_D_Stat 6;
BA_ "U_V710_MY2023_Tx" SG_ 627 VehToInfrstrctr_D_Stat 1;
BA_ "U_P708_MY2023_Tx" SG_ 627 VehToInfrstrctr_D_Stat 1;
BA_ "U_P702_MY2024_Tx" SG_ 627 VehToInfrstrctr_D_Stat 1;
BA_ "U_V710_MY2023_Tx" SG_ 627 RoadStopLineL_B_Avail 1;
BA_ "U_P708_MY2023_Tx" SG_ 627 RoadStopLineL_B_Avail 1;
BA_ "U_P702_MY2024_Tx" SG_ 627 RoadStopLineL_B_Avail 1;
BA_ "GenSigStartValue" SG_ 627 RoadStopLine_L_Est 65534;
BA_ "U_V710_MY2023_Tx" SG_ 627 RoadStopLine_L_Est 1;
BA_ "U_P708_MY2023_Tx" SG_ 627 RoadStopLine_L_Est 1;
BA_ "U_P702_MY2024_Tx" SG_ 627 RoadStopLine_L_Est 1;
BA_ "U_V710_MY2023_Tx" SG_ 627 RoadSignInfo1_D_Dsply 1;
BA_ "U_P708_MY2023_Tx" SG_ 627 RoadSignInfo1_D_Dsply 1;
BA_ "U_P702_MY2024_Tx" SG_ 627 RoadSignInfo1_D_Dsply 1;
BA_ "U_V710_MY2023_Tx" SG_ 627 TrfcLghtWarnActv_B_Stat 1;
BA_ "U_P708_MY2023_Tx" SG_ 627 TrfcLghtWarnActv_B_Stat 1;
BA_ "U_P702_MY2024_Tx" SG_ 627 TrfcLghtWarnActv_B_Stat 1;
BA_ "U_V710_MY2023_Tx" SG_ 627 TrfcLghtVActv_B_Stat 1;
BA_ "U_P708_MY2023_Tx" SG_ 627 TrfcLghtVActv_B_Stat 1;
BA_ "U_P702_MY2024_Tx" SG_ 627 TrfcLghtVActv_B_Stat 1;
BA_ "U_V710_MY2023_Tx" SG_ 627 TrfcLghtDir_D_Stat 1;
BA_ "U_P708_MY2023_Tx" SG_ 627 TrfcLghtDir_D_Stat 1;
BA_ "U_P702_MY2024_Tx" SG_ 627 TrfcLghtDir_D_Stat 1;
BA_ "GenSigStartValue" SG_ 627 TrfcLghtDecel_A_Dsply 126;
BA_ "U_V710_MY2023_Tx" SG_ 627 TrfcLghtDecel_A_Dsply 1;
BA_ "U_P708_MY2023_Tx" SG_ 627 TrfcLghtDecel_A_Dsply 1;
BA_ "U_P702_MY2024_Tx" SG_ 627 TrfcLghtDecel_A_Dsply 1;
BA_ "GenSigStartValue" SG_ 627 TrfcLght_V_Mx 254;
BA_ "U_V710_MY2023_Tx" SG_ 627 TrfcLght_V_Mx 1;
BA_ "U_P708_MY2023_Tx" SG_ 627 TrfcLght_V_Mx 1;
BA_ "U_P702_MY2024_Tx" SG_ 627 TrfcLght_V_Mx 1;
BA_ "GenSigStartValue" SG_ 627 TrfcLght_V_Mn 254;
BA_ "U_V710_MY2023_Tx" SG_ 627 TrfcLght_V_Mn 1;
BA_ "U_P708_MY2023_Tx" SG_ 627 TrfcLght_V_Mn 1;
BA_ "U_P702_MY2024_Tx" SG_ 627 TrfcLght_V_Mn 1;
BA_ "U_V710_MY2023_Tx" SG_ 627 TrfcLght_D_Stat 1;
BA_ "U_P708_MY2023_Tx" SG_ 627 TrfcLght_D_Stat 1;
BA_ "U_P702_MY2024_Tx" SG_ 627 TrfcLght_D_Stat 1;
BA_ "GenSigSendType" SG_ 874 E_Rr_Btn_Status_2nd 3;
BA_ "U_V710_MY2023_Rx" SG_ 874 E_Rr_Btn_Status_2nd 1;
BA_ "U_P708_MY2023_Rx" SG_ 874 E_Rr_Btn_Status_2nd 1;
BA_ "U_P702_MY2024_Rx" SG_ 874 E_Rr_Btn_Status_2nd 1;
BA_ "GenSigSendType" SG_ 874 E_Rr_Btn_Status_1st 3;
BA_ "U_V710_MY2023_Rx" SG_ 874 E_Rr_Btn_Status_1st 1;
BA_ "U_P708_MY2023_Rx" SG_ 874 E_Rr_Btn_Status_1st 1;
BA_ "U_P702_MY2024_Rx" SG_ 874 E_Rr_Btn_Status_1st 1;
BA_ "GenSigSendType" SG_ 874 E_Frt_Btn_Status_2nd 3;
BA_ "U_V710_MY2023_Rx" SG_ 874 E_Frt_Btn_Status_2nd 1;
BA_ "U_P708_MY2023_Rx" SG_ 874 E_Frt_Btn_Status_2nd 1;
BA_ "U_P702_MY2024_Rx" SG_ 874 E_Frt_Btn_Status_2nd 1;
BA_ "GenSigSendType" SG_ 874 E_Frt_Btn_Status_1st 3;
BA_ "U_V710_MY2023_Rx" SG_ 874 E_Frt_Btn_Status_1st 1;
BA_ "U_P708_MY2023_Rx" SG_ 874 E_Frt_Btn_Status_1st 1;
BA_ "U_P702_MY2024_Rx" SG_ 874 E_Frt_Btn_Status_1st 1;
BA_ "GenSigStartValue" SG_ 663 BptDchrg_Pw_Dsply 1022;
BA_ "U_V710_MY2023_Rx" SG_ 663 BptDchrg_Pw_Dsply 1;
BA_ "U_P708_MY2023_Rx" SG_ 663 BptDchrg_Pw_Dsply 1;
BA_ "U_P702_MY2024_Rx" SG_ 663 BptDchrg_Pw_Dsply 1;
BA_ "GenSigStartValue" SG_ 663 Bpt_I_Est 1022;
BA_ "U_V710_MY2023_Rx" SG_ 663 Bpt_I_Est 1;
BA_ "U_P702_MY2024_Rx" SG_ 663 Bpt_I_Est 1;
BA_ "GenSigStartValue" SG_ 663 Bpt_Pw_Allw 65534;
BA_ "U_V710_MY2023_Rx" SG_ 663 Bpt_Pw_Allw 1;
BA_ "U_P708_MY2023_Rx" SG_ 663 Bpt_Pw_Allw 1;
BA_ "U_P702_MY2024_Rx" SG_ 663 Bpt_Pw_Allw 1;
BA_ "GenSigStartValue" SG_ 663 BptDchrg_T_Rmng 32766;
BA_ "U_V710_MY2023_Rx" SG_ 663 BptDchrg_T_Rmng 1;
BA_ "U_P708_MY2023_Rx" SG_ 663 BptDchrg_T_Rmng 1;
BA_ "U_P702_MY2024_Rx" SG_ 663 BptDchrg_T_Rmng 1;
BA_ "GenSigStartValue" SG_ 663 BptMnSoc_L_Actl 8190;
BA_ "U_V710_MY2023_Rx" SG_ 663 BptMnSoc_L_Actl 1;
BA_ "U_P708_MY2023_Rx" SG_ 663 BptMnSoc_L_Actl 1;
BA_ "U_P702_MY2024_Rx" SG_ 663 BptMnSoc_L_Actl 1;
BA_ "GenSigStartValue" SG_ 1161 BattTracUMxArry_No_Actl 31;
BA_ "GenSigStartValue" SG_ 1161 BattTracCellUMx_No_Actl 254;
BA_ "GenSigStartValue" SG_ 1161 BattTracCellUMn_No_Actl 254;
BA_ "GenSigStartValue" SG_ 1161 BattTracCellCnt_No_Actl 254;
BA_ "U_V710_MY2023_Rx" SG_ 1161 BattChrgSocMx_B_Falt 1;
BA_ "U_P708_MY2023_Rx" SG_ 1161 BattChrgSocMx_B_Falt 1;
BA_ "U_P702_MY2024_Rx" SG_ 1161 BattChrgSocMx_B_Falt 1;
BA_ "U_V710_MY2023_Rx" SG_ 1161 BattChrgSocMn_B_Falt 1;
BA_ "U_P708_MY2023_Rx" SG_ 1161 BattChrgSocMn_B_Falt 1;
BA_ "U_P702_MY2024_Rx" SG_ 1161 BattChrgSocMn_B_Falt 1;
BA_ "GenSigStartValue" SG_ 1161 BattTracTeMx_No_Actl 254;
BA_ "GenSigStartValue" SG_ 1161 BattTracTeMn_No_Actl 254;
BA_ "GenSigStartValue" SG_ 1161 BattTracTeCnt_No_Actl 254;
BA_ "GenSigStartValue" SG_ 1121 OffRdSwtch_D_RqMnu 2;
BA_ "U_V710_MY2023_Rx" SG_ 1121 OffRdSwtch_D_RqMnu 1;
BA_ "U_P708_MY2023_Rx" SG_ 1121 OffRdSwtch_D_RqMnu 1;
BA_ "U_P702_MY2024_Rx" SG_ 1121 OffRdSwtch_D_RqMnu 1;
BA_ "U_P708_MY2023_Rx" SG_ 669 DrHandleOuterRr_D_Stat 1;
BA_ "U_P702_MY2024_Rx" SG_ 669 DrHandleOuterRr_D_Stat 1;
BA_ "U_P708_MY2023_Rx" SG_ 669 DrHandleOuterFr_D_Stat 1;
BA_ "U_P702_MY2024_Rx" SG_ 669 DrHandleOuterFr_D_Stat 1;
BA_ "GenSigStartValue" SG_ 571 VehFalr_Pc_Est 126;
BA_ "U_V710_MY2023_Rx" SG_ 571 VehFalr_Pc_Est 1;
BA_ "U_P708_MY2023_Rx" SG_ 571 VehFalr_Pc_Est 1;
BA_ "U_P702_MY2024_Rx" SG_ 571 VehFalr_Pc_Est 1;
BA_ "GenSigStartValue" SG_ 571 TrlrTngLoad_Pc_Est 126;
BA_ "U_V710_MY2023_Rx" SG_ 571 TrlrTngLoad_Pc_Est 1;
BA_ "U_P708_MY2023_Rx" SG_ 571 TrlrTngLoad_Pc_Est 1;
BA_ "U_P702_MY2024_Rx" SG_ 571 TrlrTngLoad_Pc_Est 1;
BA_ "GenSigStartValue" SG_ 571 TrlrTngLoad_M_Est 2046;
BA_ "U_V710_MY2023_Rx" SG_ 571 TrlrTngLoad_M_Est 1;
BA_ "U_P708_MY2023_Rx" SG_ 571 TrlrTngLoad_M_Est 1;
BA_ "U_P702_MY2024_Rx" SG_ 571 TrlrTngLoad_M_Est 1;
BA_ "GenSigStartValue" SG_ 571 VehPayloadAdd_M_Est 2046;
BA_ "U_V710_MY2023_Rx" SG_ 571 VehPayloadAdd_M_Est 1;
BA_ "U_P708_MY2023_Rx" SG_ 571 VehPayloadAdd_M_Est 1;
BA_ "U_P702_MY2024_Rx" SG_ 571 VehPayloadAdd_M_Est 1;
BA_ "GenSigStartValue" SG_ 571 VehPayload_Pc_Est 126;
BA_ "U_V710_MY2023_Rx" SG_ 571 VehPayload_Pc_Est 1;
BA_ "U_P708_MY2023_Rx" SG_ 571 VehPayload_Pc_Est 1;
BA_ "U_P702_MY2024_Rx" SG_ 571 VehPayload_Pc_Est 1;
BA_ "GenSigStartValue" SG_ 571 VehPayload_M_Est 1022;
BA_ "U_V710_MY2023_Rx" SG_ 571 VehPayload_M_Est 1;
BA_ "U_P708_MY2023_Rx" SG_ 571 VehPayload_M_Est 1;
BA_ "U_P702_MY2024_Rx" SG_ 571 VehPayload_M_Est 1;
BA_ "MetaData" SG_ 118 SteWhlCompAnEst_D_Qf 1;
BA_ "U_V713N_MY2022_Rx" SG_ 118 SteWhlCompAnEst_D_Qf 1;
BA_ "U_V713AV_MY2022_Rx" SG_ 118 SteWhlCompAnEst_D_Qf 1;
BA_ "U_P708_MY2023_Rx" SG_ 118 SteWhlCompAnEst_D_Qf 1;
BA_ "U_V710_MY2023_Rx" SG_ 118 SteWhlCompAnEst_D_Qf 1;
BA_ "U_P702_MY2024_Rx" SG_ 118 SteWhlCompAnEst_D_Qf 1;
BA_ "U_V713N_MY2022_Rx" SG_ 118 SteWhlComp_An_Est 1;
BA_ "U_V713AV_MY2022_Rx" SG_ 118 SteWhlComp_An_Est 1;
BA_ "U_P708_MY2023_Rx" SG_ 118 SteWhlComp_An_Est 1;
BA_ "U_V710_MY2023_Rx" SG_ 118 SteWhlComp_An_Est 1;
BA_ "U_P702_MY2024_Rx" SG_ 118 SteWhlComp_An_Est 1;
BA_ "GenSigStartValue" SG_ 868 Rr_Blower_Indicate_Stat 15;
BA_ "WakeupSignal" SG_ 836 HvacPrecondMode_D_Rq 1;
BA_ "WakeupSignal" SG_ 836 HvacPrecondBlwr_D_Rq 1;
BA_ "WakeupSignal" SG_ 836 Foh_D_Stat 1;
BA_ "U_V713N_MY2022_Rx" SG_ 836 FuelFlw_Vl_ActlFoh 1;
BA_ "U_V713AV_MY2022_Rx" SG_ 836 FuelFlw_Vl_ActlFoh 1;
BA_ "U_P708_MY2023_Rx" SG_ 836 FuelFlw_Vl_ActlFoh 1;
BA_ "U_V710_MY2023_Rx" SG_ 836 FuelFlw_Vl_ActlFoh 1;
BA_ "U_P702_MY2024_Rx" SG_ 836 FuelFlw_Vl_ActlFoh 1;
BA_ "GenSigStartValue" SG_ 613 BeltWarnThres_D_Stat 6;
BA_ "U_V713N_MY2022_Rx" SG_ 613 ObjectEntrapped 1;
BA_ "U_V713AV_MY2022_Rx" SG_ 613 ObjectEntrapped 1;
BA_ "U_P708_MY2023_Rx" SG_ 613 ObjectEntrapped 1;
BA_ "U_V710_MY2023_Rx" SG_ 613 ObjectEntrapped 1;
BA_ "U_P702_MY2024_Rx" SG_ 613 ObjectEntrapped 1;
BA_ "GenSigStartValue" SG_ 1084 BattULoChrg_URate_RqMx 5;
BA_ "GenSigStartValue" SG_ 1084 BattULoChrg_U_RqMx 34;
BA_ "GenSigStartValue" SG_ 1084 BattULo2_Te_Actl 127;
BA_ "U_V710_MY2023_Rx" SG_ 1084 BSBattSOC 1;
BA_ "U_P708_MY2023_Rx" SG_ 1084 BSBattSOC 1;
BA_ "U_P702_MY2024_Rx" SG_ 1084 BSBattSOC 1;
BA_ "WakeupSignal" SG_ 1059 PwSysULoFalt_D_Stat 1;
BA_ "U_V713N_MY2022_Rx" SG_ 1059 PwSysULoFalt_D_Stat 1;
BA_ "U_V713AV_MY2022_Rx" SG_ 1059 PwSysULoFalt_D_Stat 1;
BA_ "U_P708_MY2023_Rx" SG_ 1059 PwSysULoFalt_D_Stat 1;
BA_ "U_V710_MY2023_Rx" SG_ 1059 PwSysULoFalt_D_Stat 1;
BA_ "U_P702_MY2024_Rx" SG_ 1059 PwSysULoFalt_D_Stat 1;
BA_ "U_CDX74X_MY2024_Rx" SG_ 1059 Shed_T_Eng_Off_B 1;
BA_ "U_V710_MY2023_Rx" SG_ 1059 Shed_T_Eng_Off_B 1;
BA_ "U_P708_MY2023_Rx" SG_ 1059 Shed_T_Eng_Off_B 1;
BA_ "U_P702_MY2024_Rx" SG_ 1059 Shed_T_Eng_Off_B 1;
BA_ "WakeupSignal" SG_ 1059 Shed_Feature_Group_ID 1;
BA_ "U_P708_MY2023_Rx" SG_ 1059 Shed_Feature_Group_ID 1;
BA_ "U_CDX74X_MY2024_Rx" SG_ 1059 Shed_Feature_Group_ID 1;
BA_ "U_V710_MY2023_Rx" SG_ 1059 Shed_Feature_Group_ID 1;
BA_ "U_P702_MY2024_Rx" SG_ 1059 Shed_Feature_Group_ID 1;
BA_ "U_CDX74X_MY2024_Rx" SG_ 1059 Shed_Drain_Eng_Off_B 1;
BA_ "U_V710_MY2023_Rx" SG_ 1059 Shed_Drain_Eng_Off_B 1;
BA_ "U_P708_MY2023_Rx" SG_ 1059 Shed_Drain_Eng_Off_B 1;
BA_ "U_P702_MY2024_Rx" SG_ 1059 Shed_Drain_Eng_Off_B 1;
BA_ "WakeupSignal" SG_ 1059 Shed_Level_Req 1;
BA_ "U_V713N_MY2022_Rx" SG_ 1059 Shed_Level_Req 1;
BA_ "U_V713AV_MY2022_Rx" SG_ 1059 Shed_Level_Req 1;
BA_ "U_P708_MY2023_Rx" SG_ 1059 Shed_Level_Req 1;
BA_ "U_V710_MY2023_Rx" SG_ 1059 Shed_Level_Req 1;
BA_ "U_CDX74X_MY2024_Rx" SG_ 1059 Shed_Level_Req 1;
BA_ "U_P702_MY2024_Rx" SG_ 1059 Shed_Level_Req 1;
BA_ "U_V713N_MY2022_Rx" SG_ 1059 Batt_Lo_SoC_B 1;
BA_ "U_V713AV_MY2022_Rx" SG_ 1059 Batt_Lo_SoC_B 1;
BA_ "U_P708_MY2023_Rx" SG_ 1059 Batt_Lo_SoC_B 1;
BA_ "U_CDX74X_MY2024_Rx" SG_ 1059 Batt_Lo_SoC_B 1;
BA_ "U_V710_MY2023_Rx" SG_ 1059 Batt_Lo_SoC_B 1;
BA_ "U_P702_MY2024_Rx" SG_ 1059 Batt_Lo_SoC_B 1;
BA_ "U_V713N_MY2022_Rx" SG_ 1059 Batt_Crit_SoC_B 1;
BA_ "U_V713AV_MY2022_Rx" SG_ 1059 Batt_Crit_SoC_B 1;
BA_ "U_P708_MY2023_Rx" SG_ 1059 Batt_Crit_SoC_B 1;
BA_ "U_V710_MY2023_Rx" SG_ 1059 Batt_Crit_SoC_B 1;
BA_ "U_CDX74X_MY2024_Rx" SG_ 1059 Batt_Crit_SoC_B 1;
BA_ "U_P702_MY2024_Rx" SG_ 1059 Batt_Crit_SoC_B 1;
BA_ "WakeupSignal" SG_ 131 ElPwAsstSte_B_RqDactv 1;
BA_ "WakeupSignal" SG_ 131 HeadLghtHiCtrl_D_RqAhb 1;
BA_ "U_V713N_MY2022_Rx" SG_ 131 AhbStat_B_Dsply 1;
BA_ "U_V713AV_MY2022_Rx" SG_ 131 AhbStat_B_Dsply 1;
BA_ "U_P708_MY2023_Rx" SG_ 131 AhbStat_B_Dsply 1;
BA_ "U_V710_MY2023_Rx" SG_ 131 AhbStat_B_Dsply 1;
BA_ "U_P702_MY2024_Rx" SG_ 131 AhbStat_B_Dsply 1;
BA_ "GenSigStartValue" SG_ 131 WiprFrontSwtch_D_Stat 9;
BA_ "WakeupSignal" SG_ 131 HeadLghtHiOn_B_StatAhb 1;
BA_ "U_V713N_MY2022_Rx" SG_ 131 HeadLghtHiOn_B_StatAhb 1;
BA_ "U_V713AV_MY2022_Rx" SG_ 131 HeadLghtHiOn_B_StatAhb 1;
BA_ "U_P708_MY2023_Rx" SG_ 131 HeadLghtHiOn_B_StatAhb 1;
BA_ "U_V710_MY2023_Rx" SG_ 131 HeadLghtHiOn_B_StatAhb 1;
BA_ "U_P702_MY2024_Rx" SG_ 131 HeadLghtHiOn_B_StatAhb 1;
BA_ "GenSigStartValue" SG_ 131 WiprFront_D_Stat 15;
BA_ "U_V710_MY2023_Rx" SG_ 131 WiprFront_D_Stat 1;
BA_ "U_P708_MY2023_Rx" SG_ 131 WiprFront_D_Stat 1;
BA_ "U_P702_MY2024_Rx" SG_ 131 WiprFront_D_Stat 1;
BA_ "WakeupSignal" SG_ 131 TurnLghtSwtch_D_Stat 1;
BA_ "U_V713N_MY2022_Rx" SG_ 131 TurnLghtSwtch_D_Stat 1;
BA_ "U_V713AV_MY2022_Rx" SG_ 131 TurnLghtSwtch_D_Stat 1;
BA_ "U_P708_MY2023_Rx" SG_ 131 TurnLghtSwtch_D_Stat 1;
BA_ "U_V710_MY2023_Rx" SG_ 131 TurnLghtSwtch_D_Stat 1;
BA_ "U_P702_MY2024_Rx" SG_ 131 TurnLghtSwtch_D_Stat 1;
BA_ "GenSigStartValue" SG_ 131 LghtAmb_D_Sns 7;
BA_ "U_P708_MY2023_Rx" SG_ 931 VehOnSrc_D_Stat 1;
BA_ "U_V710_MY2023_Rx" SG_ 931 VehOnSrc_D_Stat 1;
BA_ "U_P702_MY2024_Rx" SG_ 931 VehOnSrc_D_Stat 1;
BA_ "MetaData" SG_ 931 StrtrMtrCtlDStat_No_Cs 1;
BA_ "MetaData" SG_ 931 CrnkInhbt_No_Cs 1;
BA_ "MetaData" SG_ 931 CrnkInhbt_No_Cnt 1;
BA_ "GenSigStartValue" SG_ 931 CrnkInhbt_B_Stat 1;
BA_ "WakeupSignal" SG_ 618 PaakLoclzd_D_Stat 1;
BA_ "U_V710_MY2023_Rx" SG_ 618 IgnPsswrdSetup_B_Rq 1;
BA_ "U_P708_MY2023_Rx" SG_ 618 IgnPsswrdSetup_B_Rq 1;
BA_ "U_P702_MY2024_Rx" SG_ 618 IgnPsswrdSetup_B_Rq 1;
BA_ "U_V710_MY2023_Rx" SG_ 618 IgnPsswrdLckout_B_Stat 1;
BA_ "U_P708_MY2023_Rx" SG_ 618 IgnPsswrdLckout_B_Stat 1;
BA_ "U_P702_MY2024_Rx" SG_ 618 IgnPsswrdLckout_B_Stat 1;
BA_ "WakeupSignal" SG_ 618 PaakCtlType_D_Stat 1;
BA_ "WakeupSignal" SG_ 618 PaakCtlRollCode_No_Stat 1;
BA_ "WakeupSignal" SG_ 618 PaakCtlPssvData_No_Actl 1;
BA_ "WakeupSignal" SG_ 618 PaakCtlData_D_Stat 1;
BA_ "U_V710_MY2023_Rx" SG_ 621 IgnPsswrdActv_B_Stat 1;
BA_ "U_P708_MY2023_Rx" SG_ 621 IgnPsswrdActv_B_Stat 1;
BA_ "U_P702_MY2024_Rx" SG_ 621 IgnPsswrdActv_B_Stat 1;
BA_ "U_V710_MY2023_Rx" SG_ 1016 ChrgGoTElement_B_Dsply 1;
BA_ "U_P708_MY2023_Rx" SG_ 1016 ChrgGoTElement_B_Dsply 1;
BA_ "U_P702_MY2024_Rx" SG_ 1016 ChrgGoTElement_B_Dsply 1;
BA_ "U_V710_MY2023_Rx" SG_ 1016 ChrgLocIdCurnt_D_Uns 1;
BA_ "U_P708_MY2023_Rx" SG_ 1016 ChrgLocIdCurnt_D_Uns 1;
BA_ "U_P702_MY2024_Rx" SG_ 1016 ChrgLocIdCurnt_D_Uns 1;
BA_ "U_P702_MY2024_Rx" SG_ 1016 ChrgGoTTouchEnbl_B_Rq 1;
BA_ "U_V710_MY2023_Rx" SG_ 1016 ChrgGoTTouch_B_Stat 1;
BA_ "U_P708_MY2023_Rx" SG_ 1016 ChrgGoTTouch_B_Stat 1;
BA_ "U_P702_MY2024_Rx" SG_ 1016 ChrgGoTTouch_B_Stat 1;
BA_ "U_V710_MY2023_Rx" SG_ 1016 ChrgGoTPrcond_D_Stat 1;
BA_ "U_P708_MY2023_Rx" SG_ 1016 ChrgGoTPrcond_D_Stat 1;
BA_ "U_P702_MY2024_Rx" SG_ 1016 ChrgGoTPrcond_D_Stat 1;
BA_ "MetaData" SG_ 1016 ChrgGoTNext_D_Stat 1;
BA_ "U_V710_MY2023_Rx" SG_ 1016 ChrgGoTNext_D_Stat 1;
BA_ "U_P708_MY2023_Rx" SG_ 1016 ChrgGoTNext_D_Stat 1;
BA_ "U_P702_MY2024_Rx" SG_ 1016 ChrgGoTNext_D_Stat 1;
BA_ "MetaData" SG_ 1016 ChrgGoTMnte_D_Stat 1;
BA_ "U_V710_MY2023_Rx" SG_ 1016 ChrgGoTMnte_D_Stat 1;
BA_ "U_P708_MY2023_Rx" SG_ 1016 ChrgGoTMnte_D_Stat 1;
BA_ "U_P702_MY2024_Rx" SG_ 1016 ChrgGoTMnte_D_Stat 1;
BA_ "GenSigStartValue" SG_ 1016 ChrgGoTHr_T_Stat 30;
BA_ "U_V710_MY2023_Rx" SG_ 1016 ChrgGoTHr_T_Stat 1;
BA_ "U_P708_MY2023_Rx" SG_ 1016 ChrgGoTHr_T_Stat 1;
BA_ "U_P702_MY2024_Rx" SG_ 1016 ChrgGoTHr_T_Stat 1;
BA_ "U_V710_MY2023_Rx" SG_ 1016 ChrgGoTExtHtr_B_Stat 1;
BA_ "U_P708_MY2023_Rx" SG_ 1016 ChrgGoTExtHtr_B_Stat 1;
BA_ "U_P702_MY2024_Rx" SG_ 1016 ChrgGoTExtHtr_B_Stat 1;
BA_ "MetaData" SG_ 1016 ChrgGoTElement_D_Stat 1;
BA_ "U_V710_MY2023_Rx" SG_ 1016 ChrgGoTElement_D_Stat 1;
BA_ "U_P708_MY2023_Rx" SG_ 1016 ChrgGoTElement_D_Stat 1;
BA_ "U_P702_MY2024_Rx" SG_ 1016 ChrgGoTElement_D_Stat 1;
BA_ "U_V710_MY2023_Rx" SG_ 1016 ChrgGoTAllOn_B_Stat 1;
BA_ "U_P708_MY2023_Rx" SG_ 1016 ChrgGoTAllOn_B_Stat 1;
BA_ "U_P702_MY2024_Rx" SG_ 1016 ChrgGoTAllOn_B_Stat 1;
BA_ "U_V710_MY2023_Rx" SG_ 773 StmsScrnPsngrOn_B_Rq 1;
BA_ "U_P708_MY2023_Rx" SG_ 773 StmsScrnPsngrOn_B_Rq 1;
BA_ "U_V710_MY2023_Rx" SG_ 773 SeatScrnPsngrOn_B_Rq 1;
BA_ "U_P708_MY2023_Rx" SG_ 773 SeatScrnPsngrOn_B_Rq 1;
BA_ "U_V713N_MY2022_Rx" SG_ 389 HtrnSrvcRqd_B_Dsply 1;
BA_ "U_V713AV_MY2022_Rx" SG_ 389 HtrnSrvcRqd_B_Dsply 1;
BA_ "U_V710_MY2023_Rx" SG_ 389 HtrnSrvcRqd_B_Dsply 1;
BA_ "U_P708_MY2023_Rx" SG_ 389 HtrnSrvcRqd_B_Dsply 1;
BA_ "U_P702_MY2024_Rx" SG_ 389 HtrnSrvcRqd_B_Dsply 1;
BA_ "U_V713N_MY2022_Rx" SG_ 389 HtrnOvrTeLamp_B_Dsply 1;
BA_ "U_V713AV_MY2022_Rx" SG_ 389 HtrnOvrTeLamp_B_Dsply 1;
BA_ "U_V710_MY2023_Rx" SG_ 389 HtrnOvrTeLamp_B_Dsply 1;
BA_ "U_P708_MY2023_Rx" SG_ 389 HtrnOvrTeLamp_B_Dsply 1;
BA_ "U_P702_MY2024_Rx" SG_ 389 HtrnOvrTeLamp_B_Dsply 1;
BA_ "GenSigStartValue" SG_ 1128 ChrgrPncEnbl_D_Stat 3;
BA_ "U_V713N_MY2022_Rx" SG_ 1128 ChrgrSrvcRqd_B_Rq 1;
BA_ "U_P708_MY2023_Rx" SG_ 1128 ChrgrSrvcRqd_B_Rq 1;
BA_ "U_V710_MY2023_Rx" SG_ 1128 ChrgrSrvcRqd_B_Rq 1;
BA_ "U_P702_MY2024_Rx" SG_ 1128 ChrgrSrvcRqd_B_Rq 1;
BA_ "U_V710_MY2023_Rx" SG_ 1128 ChrgCordLck_D_Stat 1;
BA_ "U_P708_MY2023_Rx" SG_ 1128 ChrgCordLck_D_Stat 1;
BA_ "U_P702_MY2024_Rx" SG_ 1128 ChrgCordLck_D_Stat 1;
BA_ "U_V713N_MY2022_Rx" SG_ 1128 ChrgPortDrOpen_B_Stat 1;
BA_ "U_V713AV_MY2022_Rx" SG_ 1128 ChrgPortDrOpen_B_Stat 1;
BA_ "U_P708_MY2023_Rx" SG_ 1128 ChrgPortDrOpen_B_Stat 1;
BA_ "U_V710_MY2023_Rx" SG_ 1128 ChrgPortDrOpen_B_Stat 1;
BA_ "U_P702_MY2024_Rx" SG_ 1128 ChrgPortDrOpen_B_Stat 1;
BA_ "U_V713N_MY2022_Rx" SG_ 1128 ChrgCrdLck_D_Falt 1;
BA_ "U_V713AV_MY2022_Rx" SG_ 1128 ChrgCrdLck_D_Falt 1;
BA_ "U_P708_MY2023_Rx" SG_ 1128 ChrgCrdLck_D_Falt 1;
BA_ "U_V710_MY2023_Rx" SG_ 1128 ChrgCrdLck_D_Falt 1;
BA_ "U_P702_MY2024_Rx" SG_ 1128 ChrgCrdLck_D_Falt 1;
BA_ "WakeupSignal" SG_ 594 HvacAirFlw_B_RqBatt 1;
BA_ "GenSigStartValue" SG_ 594 BattTracSoc_Pc_Dsply 254;
BA_ "U_V713N_MY2022_Rx" SG_ 594 BattTracSoc_Pc_Dsply 1;
BA_ "U_V713AV_MY2022_Rx" SG_ 594 BattTracSoc_Pc_Dsply 1;
BA_ "U_P708_MY2023_Rx" SG_ 594 BattTracSoc_Pc_Dsply 1;
BA_ "U_V710_MY2023_Rx" SG_ 594 BattTracSoc_Pc_Dsply 1;
BA_ "U_P702_MY2024_Rx" SG_ 594 BattTracSoc_Pc_Dsply 1;
BA_ "GenSigStartValue" SG_ 594 BattTracSoc2_Pc_Actl 16382;
BA_ "GenSigStartValue" SG_ 594 BattTracClntIn_Te_Actl 75;
BA_ "GenSigStartValue" SG_ 594 BattTrac_Te_Actl 150;
BA_ "GenSigStartValue" SG_ 594 HvacRec_D_RqMxBatt 10;
BA_ "GenSigSendType" SG_ 2614099160 SymKeyFuncGWM_ECG 3;
BA_ "U_V713AV_MY2022_Rx" SG_ 2614099160 SymKeyFuncGWM_ECG 1;
BA_ "U_P708_MY2023_Rx" SG_ 2614099160 SymKeyFuncGWM_ECG 1;
BA_ "ECGUsedTxSignal" SG_ 2614099160 SymKeyFuncGWM_ECG 1;
BA_ "U_P708_MY2023_Tx" SG_ 2614099160 SymKeyFuncGWM_ECG 1;
BA_ "U_CDX74X_MY2024_Tx" SG_ 2614099160 SymKeyFuncGWM_ECG 1;
BA_ "U_V710_MY2023_Tx" SG_ 2614099160 SymKeyFuncGWM_ECG 1;
BA_ "GenSigSendType" SG_ 2610117848 OTAPhysGWM_ECGtoESPM 3;
BA_ "U_V713AV_MY2022_Rx" SG_ 2610117848 OTAPhysGWM_ECGtoESPM 1;
BA_ "ECGUsedTxSignal" SG_ 2610117848 OTAPhysGWM_ECGtoESPM 1;
BA_ "GenSigSendType" SG_ 2610127055 OTAPhysESPMtoGWM_ECG 3;
BA_ "ECGUsedRxSignal" SG_ 2610127055 OTAPhysESPMtoGWM_ECG 1;
BA_ "U_V713AV_MY2022_Tx" SG_ 2610127055 OTAPhysESPMtoGWM_ECG 1;
BA_ "GenSigSendType" SG_ 2611175631 PARSEDPhysESPMtoGWM_ECG 3;
BA_ "ECGUsedRxSignal" SG_ 2611175631 PARSEDPhysESPMtoGWM_ECG 1;
BA_ "U_V713AV_MY2022_Tx" SG_ 2611175631 PARSEDPhysESPMtoGWM_ECG 1;
BA_ "GenSigSendType" SG_ 2612215000 PARSEDPushFcGWM_ECGtoESPM 3;
BA_ "U_V713AV_MY2022_Rx" SG_ 2612215000 PARSEDPushFcGWM_ECGtoESPM 1;
BA_ "ECGUsedTxSignal" SG_ 2612215000 PARSEDPushFcGWM_ECGtoESPM 1;
BA_ "GenSigSendType" SG_ 2612224207 PARSEDPushESPMoGWM_ECG 3;
BA_ "U_V713AV_MY2022_Rx" SG_ 2612224207 PARSEDPushESPMoGWM_ECG 1;
BA_ "U_V713AV_MY2022_Tx" SG_ 2612224207 PARSEDPushESPMoGWM_ECG 1;
BA_ "GenSigSendType" SG_ 2613263576 SymKeyPhysGWM_ECGtoESPM 3;
BA_ "U_V713AV_MY2022_Rx" SG_ 2613263576 SymKeyPhysGWM_ECGtoESPM 1;
BA_ "ECGUsedTxSignal" SG_ 2613263576 SymKeyPhysGWM_ECGtoESPM 1;
BA_ "GenSigSendType" SG_ 2613272783 SymKeyPhysESPMtoGWM_ECG 3;
BA_ "ECGUsedRxSignal" SG_ 2613272783 SymKeyPhysESPMtoGWM_ECG 1;
BA_ "U_V713AV_MY2022_Tx" SG_ 2613272783 SymKeyPhysESPMtoGWM_ECG 1;
BA_ "WakeupSignal" SG_ 932 ChildLck_D_Dsply 1;
BA_ "GenSigStartValue" SG_ 932 ChildLck_D_Dsply 1;
BA_ "U_V713AV_MY2022_Rx" SG_ 932 VehStrtInhbt_D_Stat 1;
BA_ "U_V713AV_MY2022_Rx" SG_ 932 VehOnSrc2_D_Stat 1;
BA_ "MetaData" SG_ 932 CanMsg3A4_No_Crc 1;
BA_ "MetaData" SG_ 932 CanMsg3A4_No_Cnt 1;
BA_ "GenSigStartValue" SG_ 1388 ESPM_GWOnBoardTester 255;
BA_ "U_V713AV_MY2022_Tx" SG_ 1388 ESPM_GWOnBoardTester 1;
BA_ "GenSigStartValue" SG_ 1388 ESPM_GWNMProxy 255;
BA_ "U_V713AV_MY2022_Tx" SG_ 1388 ESPM_GWNMProxy 1;
BA_ "GenSigStartValue" SG_ 1388 ESPM_AutoSarNMReserved4 255;
BA_ "U_V713AV_MY2022_Tx" SG_ 1388 ESPM_AutoSarNMReserved4 1;
BA_ "GenSigStartValue" SG_ 1388 ESPM_AutoSarNMReserved3 255;
BA_ "U_V713AV_MY2022_Tx" SG_ 1388 ESPM_AutoSarNMReserved3 1;
BA_ "GenSigStartValue" SG_ 1388 ESPM_AutoSarNMReserved2 255;
BA_ "U_V713AV_MY2022_Tx" SG_ 1388 ESPM_AutoSarNMReserved2 1;
BA_ "GenSigStartValue" SG_ 1388 ESPM_AutoSarNMReserved1 255;
BA_ "U_V713AV_MY2022_Tx" SG_ 1388 ESPM_AutoSarNMReserved1 1;
BA_ "GenSigStartValue" SG_ 1388 ESPM_AutoSarNMNodeId 108;
BA_ "U_V713AV_MY2022_Tx" SG_ 1388 ESPM_AutoSarNMNodeId 1;
BA_ "U_V713AV_MY2022_Tx" SG_ 1388 ESPM_AutoSarNMControl 1;
BA_ "GenSigSendType" SG_ 1769 TesterPhysicalResESPM 3;
BA_ "U_V713AV_MY2022_Tx" SG_ 1769 TesterPhysicalResESPM 1;
BA_ "GenSigSendType" SG_ 1761 TesterPhysicalReqESPM 3;
BA_ "U_V713AV_MY2022_Rx" SG_ 1761 TesterPhysicalReqESPM 1;
BA_ "GenSigStartValue" SG_ 528 TireRear_P_OffRoad2 255;
BA_ "GenSigStartValue" SG_ 528 TireRear_P_OffRoad1 255;
BA_ "GenSigStartValue" SG_ 528 TireFront_P_OffRoad2 255;
BA_ "GenSigStartValue" SG_ 528 TireFront_P_OffRoad1 255;
BA_ "GenSigStartValue" SG_ 591 BattTrac_U_Nom 1022;
BA_ "GenSigStartValue" SG_ 591 BattTrac_E_Nom 4094;
BA_ "U_V710_MY2023_Rx" SG_ 591 BattTrac_E_Nom 1;
BA_ "U_P708_MY2023_Rx" SG_ 591 BattTrac_E_Nom 1;
BA_ "U_P702_MY2024_Rx" SG_ 591 BattTrac_E_Nom 1;
BA_ "GenSigStartValue" SG_ 591 BattTrac_Ah_Nom 4093;
BA_ "GenSigStartValue" SG_ 591 BattTracType_D_Actl 8;
BA_ "GenSigStartValue" SG_ 591 BattChrgRqd_E_Actl 4094;
BA_ "GenSigSendType" SG_ 595 TrakApplActvSet_D_Rq 3;
BA_ "U_P702_MY2024_Tx" SG_ 595 TrakApplActvSet_D_Rq 1;
BA_ "GenSigSendType" SG_ 595 TrakAppl_D_RqMnu 3;
BA_ "U_P702_MY2024_Tx" SG_ 595 TrakAppl_D_RqMnu 1;
BA_ "GenSigSendType" SG_ 595 EngIdlShutDownT_D_Rq 3;
BA_ "U_P702_MY2024_Tx" SG_ 595 EngIdlShutDownT_D_Rq 1;
BA_ "GenSigStartValue" SG_ 595 DrvIdMde_D_Rq 1;
BA_ "GenSigSendType" SG_ 595 DrvIdMde_D_Rq 3;
BA_ "U_V710_MY2023_Tx" SG_ 595 DrvIdMde_D_Rq 1;
BA_ "U_P708_MY2023_Tx" SG_ 595 DrvIdMde_D_Rq 1;
BA_ "U_P702_MY2024_Tx" SG_ 595 DrvIdMde_D_Rq 1;
BA_ "GenSigSendType" SG_ 595 DrvIdDelete_No_Rq 3;
BA_ "U_V710_MY2023_Tx" SG_ 595 DrvIdDelete_No_Rq 1;
BA_ "U_P708_MY2023_Tx" SG_ 595 DrvIdDelete_No_Rq 1;
BA_ "U_P702_MY2024_Tx" SG_ 595 DrvIdDelete_No_Rq 1;
BA_ "U_V710_MY2023_Rx" SG_ 596 DrvIdMde_D_Stat 1;
BA_ "U_P708_MY2023_Rx" SG_ 596 DrvIdMde_D_Stat 1;
BA_ "U_P702_MY2024_Rx" SG_ 596 DrvIdMde_D_Stat 1;
BA_ "U_V710_MY2023_Rx" SG_ 596 DrvIdMatch_No_Actl 1;
BA_ "U_P708_MY2023_Rx" SG_ 596 DrvIdMatch_No_Actl 1;
BA_ "U_P702_MY2024_Rx" SG_ 596 DrvIdMatch_No_Actl 1;
BA_ "U_V710_MY2023_Rx" SG_ 596 DrvIdActn_D_Stat 1;
BA_ "U_P708_MY2023_Rx" SG_ 596 DrvIdActn_D_Stat 1;
BA_ "U_P702_MY2024_Rx" SG_ 596 DrvIdActn_D_Stat 1;
BA_ "MetaData" SG_ 596 DrvId_No_Cs 1;
BA_ "U_V710_MY2023_Rx" SG_ 596 DrvId_No_Cs 1;
BA_ "U_P708_MY2023_Rx" SG_ 596 DrvId_No_Cs 1;
BA_ "U_P702_MY2024_Rx" SG_ 596 DrvId_No_Cs 1;
BA_ "U_V710_MY2023_Rx" SG_ 596 DrvId_D_Stat 1;
BA_ "U_P708_MY2023_Rx" SG_ 596 DrvId_D_Stat 1;
BA_ "U_P702_MY2024_Rx" SG_ 596 DrvId_D_Stat 1;
BA_ "U_V710_MY2023_Rx" SG_ 596 DrvExpression_D_Stat 1;
BA_ "U_P708_MY2023_Rx" SG_ 596 DrvExpression_D_Stat 1;
BA_ "U_P702_MY2024_Rx" SG_ 596 DrvExpression_D_Stat 1;
BA_ "U_P702_MY2024_Rx" SG_ 966 TrnkFrontScnd_B_Falt 1;
BA_ "WakeupSignal" SG_ 966 TrunkFrontOpen_No_Actl 1;
BA_ "WakeupSignal" SG_ 966 TrunkFrontRolCd_No_Actl 1;
BA_ "WakeupSignal" SG_ 966 VehHorn_D_RqAlrt 1;
BA_ "WakeupSignal" SG_ 966 VehHorn_D_Rq 1;
BA_ "WakeupSignal" SG_ 966 ScrtyHornActv_B_Rq 1;
BA_ "MetaData" SG_ 1104 DrvEngageLevel_No_Cs 1;
BA_ "MetaData" SG_ 1104 DrvEngageLevel_No_Cnt 1;
BA_ "U_V710_MY2023_Rx" SG_ 1104 DrvCamPassIR_D_Stat 1;
BA_ "U_P708_MY2023_Rx" SG_ 1104 DrvCamPassIR_D_Stat 1;
BA_ "U_P702_MY2024_Rx" SG_ 1104 DrvCamPassIR_D_Stat 1;
BA_ "U_V710_MY2023_Rx" SG_ 1104 DrvCamera_D_Stat 1;
BA_ "U_P708_MY2023_Rx" SG_ 1104 DrvCamera_D_Stat 1;
BA_ "U_P702_MY2024_Rx" SG_ 1104 DrvCamera_D_Stat 1;
BA_ "U_V710_MY2023_Rx" SG_ 1104 DrvCamDrvIR_D_Stat 1;
BA_ "U_P708_MY2023_Rx" SG_ 1104 DrvCamDrvIR_D_Stat 1;
BA_ "U_P702_MY2024_Rx" SG_ 1104 DrvCamDrvIR_D_Stat 1;
BA_ "MetaData" SG_ 303 CanMsg12F_No_Crc 1;
BA_ "ContentDependant" SG_ 303 CanMsg12F_No_Crc 1;
BA_ "MetaData" SG_ 303 CanMsg12F_No_Cnt 1;
BA_ "ContentDependant" SG_ 303 CanMsg12F_No_Cnt 1;
BA_ "WakeupSignal" SG_ 303 DrStatHood_D2_Actl 1;
BA_ "U_P708_MY2023_Rx" SG_ 303 DrStatHood_D2_Actl 1;
BA_ "U_V710_MY2023_Rx" SG_ 303 DrStatHood_D2_Actl 1;
BA_ "GenSigSendType" SG_ 2612224006 PARSEDPushHUDtoGWM_ECG 3;
BA_ "ECGUsedRxSignal" SG_ 2612224006 PARSEDPushHUDtoGWM_ECG 1;
BA_ "U_P708_MY2023_Rx" SG_ 2612224006 PARSEDPushHUDtoGWM_ECG 1;
BA_ "U_P708_MY2023_Tx" SG_ 2612224006 PARSEDPushHUDtoGWM_ECG 1;
BA_ "U_P702_MY2024_Tx" SG_ 2612224006 PARSEDPushHUDtoGWM_ECG 1;
BA_ "GenSigSendType" SG_ 2612009176 PARSEDPushFcGWM_ECGtoHUD 3;
BA_ "U_P708_MY2023_Rx" SG_ 2612009176 PARSEDPushFcGWM_ECGtoHUD 1;
BA_ "U_P702_MY2024_Rx" SG_ 2612009176 PARSEDPushFcGWM_ECGtoHUD 1;
BA_ "ECGUsedTxSignal" SG_ 2612009176 PARSEDPushFcGWM_ECGtoHUD 1;
BA_ "U_P708_MY2023_Tx" SG_ 2612009176 PARSEDPushFcGWM_ECGtoHUD 1;
BA_ "GenSigSendType" SG_ 2611175430 PARSEDPhysHUDtoGWM_ECG 3;
BA_ "ECGUsedRxSignal" SG_ 2611175430 PARSEDPhysHUDtoGWM_ECG 1;
BA_ "U_P708_MY2023_Rx" SG_ 2611175430 PARSEDPhysHUDtoGWM_ECG 1;
BA_ "U_P708_MY2023_Tx" SG_ 2611175430 PARSEDPhysHUDtoGWM_ECG 1;
BA_ "U_P702_MY2024_Tx" SG_ 2611175430 PARSEDPhysHUDtoGWM_ECG 1;
BA_ "GenSigSendType" SG_ 2610960600 PARSEDPhysGWM_ECGtoHUD 3;
BA_ "U_P708_MY2023_Rx" SG_ 2610960600 PARSEDPhysGWM_ECGtoHUD 1;
BA_ "U_P702_MY2024_Rx" SG_ 2610960600 PARSEDPhysGWM_ECGtoHUD 1;
BA_ "ECGUsedTxSignal" SG_ 2610960600 PARSEDPhysGWM_ECGtoHUD 1;
BA_ "U_P708_MY2023_Tx" SG_ 2610960600 PARSEDPhysGWM_ECGtoHUD 1;
BA_ "GenSigSendType" SG_ 2610126854 OTAPhysHUDtoGWM_ECG 3;
BA_ "ECGUsedRxSignal" SG_ 2610126854 OTAPhysHUDtoGWM_ECG 1;
BA_ "U_P708_MY2023_Rx" SG_ 2610126854 OTAPhysHUDtoGWM_ECG 1;
BA_ "U_P708_MY2023_Tx" SG_ 2610126854 OTAPhysHUDtoGWM_ECG 1;
BA_ "U_P702_MY2024_Tx" SG_ 2610126854 OTAPhysHUDtoGWM_ECG 1;
BA_ "GenSigSendType" SG_ 2609912024 OTAPhysGWM_ECGtoHUD 3;
BA_ "U_P708_MY2023_Rx" SG_ 2609912024 OTAPhysGWM_ECGtoHUD 1;
BA_ "U_P702_MY2024_Rx" SG_ 2609912024 OTAPhysGWM_ECGtoHUD 1;
BA_ "ECGUsedTxSignal" SG_ 2609912024 OTAPhysGWM_ECGtoHUD 1;
BA_ "U_P708_MY2023_Tx" SG_ 2609912024 OTAPhysGWM_ECGtoHUD 1;
VAL_ 685 ElVehChrgMde_D_Stat 3 "NotUsed" 2 "Available" 1 "NotAvailable" 0 "Null" ;
VAL_ 685 BattTracThrml_D_Stat 15 "NotUsed_5" 14 "NotUsed_4" 13 "NotUsed_3" 12 "NotUsed_2" 11 "NotUsed_1" 10 "SysFill" 9 "AirPurge" 8 "VlvCalib" 7 "InActvHeaterCoreClntFlw" 6 "ActvHeaterCoreClntFlw" 5 "MxChlrClntFlw" 4 "ChlrClntFlw" 3 "RadClntFlwFan" 2 "RadClntFlwWoFan" 1 "ClntFlw" 0 "ThrmlSysOff" ;
VAL_ 685 ElVehLaterMde_D_Stat 3 "NotUsed" 2 "Available" 1 "NotAvailable" 0 "Null" ;
VAL_ 685 ElVehNowMde_D_Stat 3 "NotUsed" 2 "Available" 1 "NotAvailable" 0 "Null" ;
VAL_ 685 OnePdlDrvBrk_D_Rq 3 "Active_FbrkStandstillApply" 2 "Active_FbrkStopApply" 1 "Active_NoFbrkAllow" 0 "Inactive" ;
VAL_ 535 WhlRr_W_Meas 32767 "Fault" 32766 "Unknown" ;
VAL_ 535 WhlRl_W_Meas 32767 "Fault" 32766 "Unknown" ;
VAL_ 535 WhlFr_W_Meas 32767 "Fault" 32766 "Unknown" ;
VAL_ 535 WhlFl_W_Meas 32767 "Fault" 32766 "Unknown" ;
VAL_ 573 VehStrtKeyType_D_Stat 3 "NotUsed_1" 2 "User" 1 "Factory" 0 "Null" ;
VAL_ 573 VehStrtKeySrc_D_Stat 7 "NotUsed_4" 6 "NotUsed_3" 5 "NotUsed_2" 4 "NotUsed_1" 3 "Legacy_Paak" 2 "Peps_and_Ikt" 1 "Digital_Key" 0 "Null" ;
VAL_ 573 NfcDevcSearch_B_Rq 1 "Active" 0 "Inactive" ;
VAL_ 1212 PersPrfl_D_Stat 7 "Unused_3" 6 "Unused_2" 5 "Unused_1" 4 "PERS_4" 3 "PERS_3" 2 "PERS_2" 1 "PERS_1" 0 "Null" ;
VAL_ 1212 PersDgtlKey4_D_Stat 255 "Index_255" 254 "Index_254" 253 "Index_253" 252 "Index_252" 251 "Index_251" 250 "Index_250" 249 "Index_249" 248 "Index_248" 247 "Index_247" 246 "Index_246" 245 "Index_245" 244 "Index_244" 243 "Index_243" 242 "Index_242" 241 "Index_241" 240 "Index_240" 239 "Index_239" 238 "Index_238" 237 "Index_237" 236 "Index_236" 235 "Index_235" 234 "Index_234" 233 "Index_233" 232 "Index_232" 231 "Index_231" 230 "Index_230" 229 "Index_229" 228 "Index_228" 227 "Index_227" 226 "Index_226" 225 "Index_225" 224 "Index_224" 223 "Index_223" 222 "Index_222" 221 "Index_221" 220 "Index_220" 219 "Index_219" 218 "Index_218" 217 "Index_217" 216 "Index_216" 215 "Index_215" 214 "Index_214" 213 "Index_213" 212 "Index_212" 211 "Index_211" 210 "Index_210" 209 "Index_209" 208 "Index_208" 207 "Index_207" 206 "Index_206" 205 "Index_205" 204 "Index_204" 203 "Index_203" 202 "Index_202" 201 "Index_201" 200 "Index_200" 199 "Index_199" 198 "Index_198" 197 "Index_197" 196 "Index_196" 195 "Index_195" 194 "Index_194" 193 "Index_193" 192 "Index_192" 191 "Index_191" 190 "Index_190" 189 "Index_189" 188 "Index_188" 187 "Index_187" 186 "Index_186" 185 "Index_185" 184 "Index_184" 183 "Index_183" 182 "Index_182" 181 "Index_181" 180 "Index_180" 179 "Index_179" 178 "Index_178" 177 "Index_177" 176 "Index_176" 175 "Index_175" 174 "Index_174" 173 "Index_173" 172 "Index_172" 171 "Index_171" 170 "Index_170" 169 "Index_169" 168 "Index_168" 167 "Index_167" 166 "Index_166" 165 "Index_165" 164 "Index_164" 163 "Index_163" 162 "Index_162" 161 "Index_161" 160 "Index_160" 159 "Index_159" 158 "Index_158" 157 "Index_157" 156 "Index_156" 155 "Index_155" 154 "Index_154" 153 "Index_153" 152 "Index_152" 151 "Index_151" 150 "Index_150" 149 "Index_149" 148 "Index_148" 147 "Index_147" 146 "Index_146" 145 "Index_145" 144 "Index_144" 143 "Index_143" 142 "Index_142" 141 "Index_141" 140 "Index_140" 139 "Index_139" 138 "Index_138" 137 "Index_137" 136 "Index_136" 135 "Index_135" 134 "Index_134" 133 "Index_133" 132 "Index_132" 131 "Index_131" 130 "Index_130" 129 "Index_129" 128 "Index_128" 127 "Index_127" 126 "Index_126" 125 "Index_125" 124 "Index_124" 123 "Index_123" 122 "Index_122" 121 "Index_121" 120 "Index_120" 119 "Index_119" 118 "Index_118" 117 "Index_117" 116 "Index_116" 115 "Index_115" 114 "Index_114" 113 "Index_113" 112 "Index_112" 111 "Index_111" 110 "Index_110" 109 "Index_109" 108 "Index_108" 107 "Index_107" 106 "Index_106" 105 "Index_105" 104 "Index_104" 103 "Index_103" 102 "Index_102" 101 "Index_101" 100 "Index_100" 99 "Index_99" 98 "Index_98" 97 "Index_97" 96 "Index_96" 95 "Index_95" 94 "Index_94" 93 "Index_93" 92 "Index_92" 91 "Index_91" 90 "Index_90" 89 "Index_89" 88 "Index_88" 87 "Index_87" 86 "Index_86" 85 "Index_85" 84 "Index_84" 83 "Index_83" 82 "Index_82" 81 "Index_81" 80 "Index_80" 79 "Index_79" 78 "Index_78" 77 "Index_77" 76 "Index_76" 75 "Index_75" 74 "Index_74" 73 "Index_73" 72 "Index_72" 71 "Index_71" 70 "Index_70" 69 "Index_69" 68 "Index_68" 67 "Index_67" 66 "Index_66" 65 "Index_65" 64 "Index_64" 63 "Index_63" 62 "Index_62" 61 "Index_61" 60 "Index_60" 59 "Index_59" 58 "Index_58" 57 "Index_57" 56 "Index_56" 55 "Index_55" 54 "Index_54" 53 "Index_53" 52 "Index_52" 51 "Index_51" 50 "Index_50" 49 "Index_49" 48 "Index_48" 47 "Index_47" 46 "Index_46" 45 "Index_45" 44 "Index_44" 43 "Index_43" 42 "Index_42" 41 "Index_41" 40 "Index_40" 39 "Index_39" 38 "Index_38" 37 "Index_37" 36 "Index_36" 35 "Index_35" 34 "Index_34" 33 "Index_33" 32 "Index_32" 31 "Index_31" 30 "Index_30" 29 "Index_29" 28 "Index_28" 27 "Index_27" 26 "Index_26" 25 "Index_25" 24 "Index_24" 23 "Index_23" 22 "Index_22" 21 "Index_21" 20 "Index_20" 19 "Index_19" 18 "Index_18" 17 "Index_17" 16 "Index_16" 15 "Index_15" 14 "Index_14" 13 "Index_13" 12 "Index_12" 11 "Index_11" 10 "Index_10" 9 "Index_9" 8 "Index_8" 7 "Index_7" 6 "Index_6" 5 "Index_5" 4 "Index_4" 3 "Index_3" 2 "Index_2" 1 "Index_1" 0 "Inactive" ;
VAL_ 1212 PersDgtlKey3_D_Stat 255 "Index_255" 254 "Index_254" 253 "Index_253" 252 "Index_252" 251 "Index_251" 250 "Index_250" 249 "Index_249" 248 "Index_248" 247 "Index_247" 246 "Index_246" 245 "Index_245" 244 "Index_244" 243 "Index_243" 242 "Index_242" 241 "Index_241" 240 "Index_240" 239 "Index_239" 238 "Index_238" 237 "Index_237" 236 "Index_236" 235 "Index_235" 234 "Index_234" 233 "Index_233" 232 "Index_232" 231 "Index_231" 230 "Index_230" 229 "Index_229" 228 "Index_228" 227 "Index_227" 226 "Index_226" 225 "Index_225" 224 "Index_224" 223 "Index_223" 222 "Index_222" 221 "Index_221" 220 "Index_220" 219 "Index_219" 218 "Index_218" 217 "Index_217" 216 "Index_216" 215 "Index_215" 214 "Index_214" 213 "Index_213" 212 "Index_212" 211 "Index_211" 210 "Index_210" 209 "Index_209" 208 "Index_208" 207 "Index_207" 206 "Index_206" 205 "Index_205" 204 "Index_204" 203 "Index_203" 202 "Index_202" 201 "Index_201" 200 "Index_200" 199 "Index_199" 198 "Index_198" 197 "Index_197" 196 "Index_196" 195 "Index_195" 194 "Index_194" 193 "Index_193" 192 "Index_192" 191 "Index_191" 190 "Index_190" 189 "Index_189" 188 "Index_188" 187 "Index_187" 186 "Index_186" 185 "Index_185" 184 "Index_184" 183 "Index_183" 182 "Index_182" 181 "Index_181" 180 "Index_180" 179 "Index_179" 178 "Index_178" 177 "Index_177" 176 "Index_176" 175 "Index_175" 174 "Index_174" 173 "Index_173" 172 "Index_172" 171 "Index_171" 170 "Index_170" 169 "Index_169" 168 "Index_168" 167 "Index_167" 166 "Index_166" 165 "Index_165" 164 "Index_164" 163 "Index_163" 162 "Index_162" 161 "Index_161" 160 "Index_160" 159 "Index_159" 158 "Index_158" 157 "Index_157" 156 "Index_156" 155 "Index_155" 154 "Index_154" 153 "Index_153" 152 "Index_152" 151 "Index_151" 150 "Index_150" 149 "Index_149" 148 "Index_148" 147 "Index_147" 146 "Index_146" 145 "Index_145" 144 "Index_144" 143 "Index_143" 142 "Index_142" 141 "Index_141" 140 "Index_140" 139 "Index_139" 138 "Index_138" 137 "Index_137" 136 "Index_136" 135 "Index_135" 134 "Index_134" 133 "Index_133" 132 "Index_132" 131 "Index_131" 130 "Index_130" 129 "Index_129" 128 "Index_128" 127 "Index_127" 126 "Index_126" 125 "Index_125" 124 "Index_124" 123 "Index_123" 122 "Index_122" 121 "Index_121" 120 "Index_120" 119 "Index_119" 118 "Index_118" 117 "Index_117" 116 "Index_116" 115 "Index_115" 114 "Index_114" 113 "Index_113" 112 "Index_112" 111 "Index_111" 110 "Index_110" 109 "Index_109" 108 "Index_108" 107 "Index_107" 106 "Index_106" 105 "Index_105" 104 "Index_104" 103 "Index_103" 102 "Index_102" 101 "Index_101" 100 "Index_100" 99 "Index_99" 98 "Index_98" 97 "Index_97" 96 "Index_96" 95 "Index_95" 94 "Index_94" 93 "Index_93" 92 "Index_92" 91 "Index_91" 90 "Index_90" 89 "Index_89" 88 "Index_88" 87 "Index_87" 86 "Index_86" 85 "Index_85" 84 "Index_84" 83 "Index_83" 82 "Index_82" 81 "Index_81" 80 "Index_80" 79 "Index_79" 78 "Index_78" 77 "Index_77" 76 "Index_76" 75 "Index_75" 74 "Index_74" 73 "Index_73" 72 "Index_72" 71 "Index_71" 70 "Index_70" 69 "Index_69" 68 "Index_68" 67 "Index_67" 66 "Index_66" 65 "Index_65" 64 "Index_64" 63 "Index_63" 62 "Index_62" 61 "Index_61" 60 "Index_60" 59 "Index_59" 58 "Index_58" 57 "Index_57" 56 "Index_56" 55 "Index_55" 54 "Index_54" 53 "Index_53" 52 "Index_52" 51 "Index_51" 50 "Index_50" 49 "Index_49" 48 "Index_48" 47 "Index_47" 46 "Index_46" 45 "Index_45" 44 "Index_44" 43 "Index_43" 42 "Index_42" 41 "Index_41" 40 "Index_40" 39 "Index_39" 38 "Index_38" 37 "Index_37" 36 "Index_36" 35 "Index_35" 34 "Index_34" 33 "Index_33" 32 "Index_32" 31 "Index_31" 30 "Index_30" 29 "Index_29" 28 "Index_28" 27 "Index_27" 26 "Index_26" 25 "Index_25" 24 "Index_24" 23 "Index_23" 22 "Index_22" 21 "Index_21" 20 "Index_20" 19 "Index_19" 18 "Index_18" 17 "Index_17" 16 "Index_16" 15 "Index_15" 14 "Index_14" 13 "Index_13" 12 "Index_12" 11 "Index_11" 10 "Index_10" 9 "Index_9" 8 "Index_8" 7 "Index_7" 6 "Index_6" 5 "Index_5" 4 "Index_4" 3 "Index_3" 2 "Index_2" 1 "Index_1" 0 "Inactive" ;
VAL_ 1212 PersDgtlKey2_D_Stat 255 "Index_255" 254 "Index_254" 253 "Index_253" 252 "Index_252" 251 "Index_251" 250 "Index_250" 249 "Index_249" 248 "Index_248" 247 "Index_247" 246 "Index_246" 245 "Index_245" 244 "Index_244" 243 "Index_243" 242 "Index_242" 241 "Index_241" 240 "Index_240" 239 "Index_239" 238 "Index_238" 237 "Index_237" 236 "Index_236" 235 "Index_235" 234 "Index_234" 233 "Index_233" 232 "Index_232" 231 "Index_231" 230 "Index_230" 229 "Index_229" 228 "Index_228" 227 "Index_227" 226 "Index_226" 225 "Index_225" 224 "Index_224" 223 "Index_223" 222 "Index_222" 221 "Index_221" 220 "Index_220" 219 "Index_219" 218 "Index_218" 217 "Index_217" 216 "Index_216" 215 "Index_215" 214 "Index_214" 213 "Index_213" 212 "Index_212" 211 "Index_211" 210 "Index_210" 209 "Index_209" 208 "Index_208" 207 "Index_207" 206 "Index_206" 205 "Index_205" 204 "Index_204" 203 "Index_203" 202 "Index_202" 201 "Index_201" 200 "Index_200" 199 "Index_199" 198 "Index_198" 197 "Index_197" 196 "Index_196" 195 "Index_195" 194 "Index_194" 193 "Index_193" 192 "Index_192" 191 "Index_191" 190 "Index_190" 189 "Index_189" 188 "Index_188" 187 "Index_187" 186 "Index_186" 185 "Index_185" 184 "Index_184" 183 "Index_183" 182 "Index_182" 181 "Index_181" 180 "Index_180" 179 "Index_179" 178 "Index_178" 177 "Index_177" 176 "Index_176" 175 "Index_175" 174 "Index_174" 173 "Index_173" 172 "Index_172" 171 "Index_171" 170 "Index_170" 169 "Index_169" 168 "Index_168" 167 "Index_167" 166 "Index_166" 165 "Index_165" 164 "Index_164" 163 "Index_163" 162 "Index_162" 161 "Index_161" 160 "Index_160" 159 "Index_159" 158 "Index_158" 157 "Index_157" 156 "Index_156" 155 "Index_155" 154 "Index_154" 153 "Index_153" 152 "Index_152" 151 "Index_151" 150 "Index_150" 149 "Index_149" 148 "Index_148" 147 "Index_147" 146 "Index_146" 145 "Index_145" 144 "Index_144" 143 "Index_143" 142 "Index_142" 141 "Index_141" 140 "Index_140" 139 "Index_139" 138 "Index_138" 137 "Index_137" 136 "Index_136" 135 "Index_135" 134 "Index_134" 133 "Index_133" 132 "Index_132" 131 "Index_131" 130 "Index_130" 129 "Index_129" 128 "Index_128" 127 "Index_127" 126 "Index_126" 125 "Index_125" 124 "Index_124" 123 "Index_123" 122 "Index_122" 121 "Index_121" 120 "Index_120" 119 "Index_119" 118 "Index_118" 117 "Index_117" 116 "Index_116" 115 "Index_115" 114 "Index_114" 113 "Index_113" 112 "Index_112" 111 "Index_111" 110 "Index_110" 109 "Index_109" 108 "Index_108" 107 "Index_107" 106 "Index_106" 105 "Index_105" 104 "Index_104" 103 "Index_103" 102 "Index_102" 101 "Index_101" 100 "Index_100" 99 "Index_99" 98 "Index_98" 97 "Index_97" 96 "Index_96" 95 "Index_95" 94 "Index_94" 93 "Index_93" 92 "Index_92" 91 "Index_91" 90 "Index_90" 89 "Index_89" 88 "Index_88" 87 "Index_87" 86 "Index_86" 85 "Index_85" 84 "Index_84" 83 "Index_83" 82 "Index_82" 81 "Index_81" 80 "Index_80" 79 "Index_79" 78 "Index_78" 77 "Index_77" 76 "Index_76" 75 "Index_75" 74 "Index_74" 73 "Index_73" 72 "Index_72" 71 "Index_71" 70 "Index_70" 69 "Index_69" 68 "Index_68" 67 "Index_67" 66 "Index_66" 65 "Index_65" 64 "Index_64" 63 "Index_63" 62 "Index_62" 61 "Index_61" 60 "Index_60" 59 "Index_59" 58 "Index_58" 57 "Index_57" 56 "Index_56" 55 "Index_55" 54 "Index_54" 53 "Index_53" 52 "Index_52" 51 "Index_51" 50 "Index_50" 49 "Index_49" 48 "Index_48" 47 "Index_47" 46 "Index_46" 45 "Index_45" 44 "Index_44" 43 "Index_43" 42 "Index_42" 41 "Index_41" 40 "Index_40" 39 "Index_39" 38 "Index_38" 37 "Index_37" 36 "Index_36" 35 "Index_35" 34 "Index_34" 33 "Index_33" 32 "Index_32" 31 "Index_31" 30 "Index_30" 29 "Index_29" 28 "Index_28" 27 "Index_27" 26 "Index_26" 25 "Index_25" 24 "Index_24" 23 "Index_23" 22 "Index_22" 21 "Index_21" 20 "Index_20" 19 "Index_19" 18 "Index_18" 17 "Index_17" 16 "Index_16" 15 "Index_15" 14 "Index_14" 13 "Index_13" 12 "Index_12" 11 "Index_11" 10 "Index_10" 9 "Index_9" 8 "Index_8" 7 "Index_7" 6 "Index_6" 5 "Index_5" 4 "Index_4" 3 "Index_3" 2 "Index_2" 1 "Index_1" 0 "Inactive" ;
VAL_ 1212 PersDgtlKey1_D_Stat 255 "Index_255" 254 "Index_254" 253 "Index_253" 252 "Index_252" 251 "Index_251" 250 "Index_250" 249 "Index_249" 248 "Index_248" 247 "Index_247" 246 "Index_246" 245 "Index_245" 244 "Index_244" 243 "Index_243" 242 "Index_242" 241 "Index_241" 240 "Index_240" 239 "Index_239" 238 "Index_238" 237 "Index_237" 236 "Index_236" 235 "Index_235" 234 "Index_234" 233 "Index_233" 232 "Index_232" 231 "Index_231" 230 "Index_230" 229 "Index_229" 228 "Index_228" 227 "Index_227" 226 "Index_226" 225 "Index_225" 224 "Index_224" 223 "Index_223" 222 "Index_222" 221 "Index_221" 220 "Index_220" 219 "Index_219" 218 "Index_218" 217 "Index_217" 216 "Index_216" 215 "Index_215" 214 "Index_214" 213 "Index_213" 212 "Index_212" 211 "Index_211" 210 "Index_210" 209 "Index_209" 208 "Index_208" 207 "Index_207" 206 "Index_206" 205 "Index_205" 204 "Index_204" 203 "Index_203" 202 "Index_202" 201 "Index_201" 200 "Index_200" 199 "Index_199" 198 "Index_198" 197 "Index_197" 196 "Index_196" 195 "Index_195" 194 "Index_194" 193 "Index_193" 192 "Index_192" 191 "Index_191" 190 "Index_190" 189 "Index_189" 188 "Index_188" 187 "Index_187" 186 "Index_186" 185 "Index_185" 184 "Index_184" 183 "Index_183" 182 "Index_182" 181 "Index_181" 180 "Index_180" 179 "Index_179" 178 "Index_178" 177 "Index_177" 176 "Index_176" 175 "Index_175" 174 "Index_174" 173 "Index_173" 172 "Index_172" 171 "Index_171" 170 "Index_170" 169 "Index_169" 168 "Index_168" 167 "Index_167" 166 "Index_166" 165 "Index_165" 164 "Index_164" 163 "Index_163" 162 "Index_162" 161 "Index_161" 160 "Index_160" 159 "Index_159" 158 "Index_158" 157 "Index_157" 156 "Index_156" 155 "Index_155" 154 "Index_154" 153 "Index_153" 152 "Index_152" 151 "Index_151" 150 "Index_150" 149 "Index_149" 148 "Index_148" 147 "Index_147" 146 "Index_146" 145 "Index_145" 144 "Index_144" 143 "Index_143" 142 "Index_142" 141 "Index_141" 140 "Index_140" 139 "Index_139" 138 "Index_138" 137 "Index_137" 136 "Index_136" 135 "Index_135" 134 "Index_134" 133 "Index_133" 132 "Index_132" 131 "Index_131" 130 "Index_130" 129 "Index_129" 128 "Index_128" 127 "Index_127" 126 "Index_126" 125 "Index_125" 124 "Index_124" 123 "Index_123" 122 "Index_122" 121 "Index_121" 120 "Index_120" 119 "Index_119" 118 "Index_118" 117 "Index_117" 116 "Index_116" 115 "Index_115" 114 "Index_114" 113 "Index_113" 112 "Index_112" 111 "Index_111" 110 "Index_110" 109 "Index_109" 108 "Index_108" 107 "Index_107" 106 "Index_106" 105 "Index_105" 104 "Index_104" 103 "Index_103" 102 "Index_102" 101 "Index_101" 100 "Index_100" 99 "Index_99" 98 "Index_98" 97 "Index_97" 96 "Index_96" 95 "Index_95" 94 "Index_94" 93 "Index_93" 92 "Index_92" 91 "Index_91" 90 "Index_90" 89 "Index_89" 88 "Index_88" 87 "Index_87" 86 "Index_86" 85 "Index_85" 84 "Index_84" 83 "Index_83" 82 "Index_82" 81 "Index_81" 80 "Index_80" 79 "Index_79" 78 "Index_78" 77 "Index_77" 76 "Index_76" 75 "Index_75" 74 "Index_74" 73 "Index_73" 72 "Index_72" 71 "Index_71" 70 "Index_70" 69 "Index_69" 68 "Index_68" 67 "Index_67" 66 "Index_66" 65 "Index_65" 64 "Index_64" 63 "Index_63" 62 "Index_62" 61 "Index_61" 60 "Index_60" 59 "Index_59" 58 "Index_58" 57 "Index_57" 56 "Index_56" 55 "Index_55" 54 "Index_54" 53 "Index_53" 52 "Index_52" 51 "Index_51" 50 "Index_50" 49 "Index_49" 48 "Index_48" 47 "Index_47" 46 "Index_46" 45 "Index_45" 44 "Index_44" 43 "Index_43" 42 "Index_42" 41 "Index_41" 40 "Index_40" 39 "Index_39" 38 "Index_38" 37 "Index_37" 36 "Index_36" 35 "Index_35" 34 "Index_34" 33 "Index_33" 32 "Index_32" 31 "Index_31" 30 "Index_30" 29 "Index_29" 28 "Index_28" 27 "Index_27" 26 "Index_26" 25 "Index_25" 24 "Index_24" 23 "Index_23" 22 "Index_22" 21 "Index_21" 20 "Index_20" 19 "Index_19" 18 "Index_18" 17 "Index_17" 16 "Index_16" 15 "Index_15" 14 "Index_14" 13 "Index_13" 12 "Index_12" 11 "Index_11" 10 "Index_10" 9 "Index_9" 8 "Index_8" 7 "Index_7" 6 "Index_6" 5 "Index_5" 4 "Index_4" 3 "Index_3" 2 "Index_2" 1 "Index_1" 0 "Inactive" ;
VAL_ 1211 FrtTe_An_Actl 511 "Faulty" ;
VAL_ 1211 FrtBlwr_An_Actl 511 "Faulty" ;
VAL_ 1211 E_Voice_Blower_Limit 1 "Request" 0 "NoRequest" ;
VAL_ 1211 E_Rr_Btn_Status_2nd 31 "NotUsed15" 30 "NotUsed14" 29 "NotUsed13" 28 "NotUsed12" 27 "NotUsed11" 26 "NotUsed10" 25 "NotUsed9" 24 "Third_Synch_Pressed" 23 "Third_Rr_Pwr_Pressed" 22 "Third_Auto_Pressed" 21 "Third_Pnl_Flr_Pressed" 20 "Third_Floor_Pressed" 19 "Third_Panel_Pressed" 18 "Third_Blwr_Dec_Pressed" 17 "Third_Blwr_Inc_Pressed" 16 "Rear_Lock_Pressed" 15 "RHS_Cld_Seat_Pressed" 14 "LHS_Cld_Seat_Pressed" 13 "RHS_Htd_Seat_Pressed" 12 "LHS_Htd_Seat_Pressed" 11 "Rear_Power_Pressed" 10 "AUTO_Pressed" 9 "Blwr_Dec_Pressed" 8 "Blwr_Inc_Pressed" 7 "RHS_Temp_Dec_Pressed" 6 "RHS_Temp_Inc_Pressed" 5 "LHS_Temp_Dec_Pressed" 4 "LHS_Temp_Inc_Pressed" 3 "Floor_Pressed" 2 "Panel_Floor_Pressed" 1 "Panel_Pressed" 0 "None_Pressed" ;
VAL_ 1211 E_Rr_Btn_Status_1st 31 "NotUsed15" 30 "NotUsed14" 29 "NotUsed13" 28 "NotUsed12" 27 "NotUsed11" 26 "NotUsed10" 25 "NotUsed9" 24 "Third_Synch_Pressed" 23 "Third_Rr_Pwr_Pressed" 22 "Third_Auto_Pressed" 21 "Third_Pnl_Flr_Pressed" 20 "Third_Floor_Pressed" 19 "Third_Panel_Pressed" 18 "Third_Blwr_Dec_Pressed" 17 "Third_Blwr_Inc_Pressed" 16 "Rear_Lock_Pressed" 15 "RHS_Cld_Seat_Pressed" 14 "LHS_Cld_Seat_Pressed" 13 "RHS_Htd_Seat_Pressed" 12 "LHS_Htd_Seat_Pressed" 11 "Rear_Power_Pressed" 10 "AUTO_Pressed" 9 "Blwr_Dec_Pressed" 8 "Blwr_Inc_Pressed" 7 "RHS_Temp_Dec_Pressed" 6 "RHS_Temp_Inc_Pressed" 5 "LHS_Temp_Dec_Pressed" 4 "LHS_Temp_Inc_Pressed" 3 "Floor_Pressed" 2 "Panel_Floor_Pressed" 1 "Panel_Pressed" 0 "None_Pressed" ;
VAL_ 1211 E_Frt_Btn_Status_2nd 63 "NotUsed_5" 62 "NotUsed_4" 61 "NotUsed_3" 60 "NotUsed_2" 59 "NotUsed_1" 58 "AUTO_Dec_Pressed" 57 "AUTO_Inc_Pressed" 56 "AUTO_Hi_Pressed" 55 "AUTO_Med_Pressed" 54 "AUTO_Lo_Pressed" 53 "RHS_Cld_Seat3_Pressed" 52 "RHS_Cld_Seat2_Pressed" 51 "RHS_Cld_Seat1_Pressed" 50 "LHS_Cld_Seat3_Pressed" 49 "LHS_Cld_Seat2_Pressed" 48 "LHS_Cld_Seat1_Pressed" 47 "RHS_Auto_Seat_Pressed" 46 "RHS_Htd_Seat3_Pressed" 45 "RHS_Htd_Seat2_Pressed" 44 "RHS_Htd_Seat1_Pressed" 43 "RHS_Seat_Off_Pressed" 42 "LHS_Auto_Seat_Pressed" 41 "LHS_Htd_Seat3_Pressed" 40 "LHS_Htd_Seat2_Pressed" 39 "LHS_Htd_Seat1_Pressed" 38 "LHS_Seat_Off_Pressed" 37 "DrvrFcsdMde_Pressed" 36 "MdeMnu_Pressed" 35 "AAR_Pressed" 34 "Heat_Pressed" 33 "RearMnu_Pressed" 32 "FrontMnu_Pressed" 31 "Defrost_Pressed" 30 "Htg_Strg_Whl_Pressed" 29 "RHS_Cld_Seat_Pressed" 28 "LHS_Cld_Seat_Pressed" 27 "RHS_Htd_Seat_Pressed" 26 "LHS_Htd_Seat_Pressed" 25 "Max_Defrost_Pressed" 24 "My_Temp_Pressed" 23 "Front_Power_Pressed" 22 "Rear_Defrost_Pressed" 21 "Pnl_Flr_Ws_Pressed" 20 "Pnl_Ws_Pressed" 19 "Windscreen_Pressed" 18 "Htd_Frt_Wsh_Pressed" 17 "Auto_Recirc_Pressed" 16 "Outside_Pressed" 15 "Recirc_Pressed" 14 "Max_AC_Pressed" 13 "Auto_Pressed" 12 "Blwr_Dec_Pressed" 11 "Blwr_Inc_Pressed" 10 "RHS_Temp_Dec_Pressed" 9 "RHS_Temp_Inc_Pressed" 8 "LHS_Temp_Dec_Pressed" 7 "LHS_Temp_Inc_Pressed" 6 "Dual_Pressed" 5 "AC_Pressed" 4 "Floor_Ws_Pressed" 3 "Floor_Pressed" 2 "Panel_Floor_Pressed" 1 "Panel_Pressed" 0 "None_Pressed" ;
VAL_ 1211 E_Frt_Btn_Status_1st 63 "NotUsed_5" 62 "NotUsed_4" 61 "NotUsed_3" 60 "NotUsed_2" 59 "NotUsed_1" 58 "AUTO_Dec_Pressed" 57 "AUTO_Inc_Pressed" 56 "AUTO_Hi_Pressed" 55 "AUTO_Med_Pressed" 54 "AUTO_Lo_Pressed" 53 "RHS_Cld_Seat3_Pressed" 52 "RHS_Cld_Seat2_Pressed" 51 "RHS_Cld_Seat1_Pressed" 50 "LHS_Cld_Seat3_Pressed" 49 "LHS_Cld_Seat2_Pressed" 48 "LHS_Cld_Seat1_Pressed" 47 "RHS_Auto_Seat_Pressed" 46 "RHS_Htd_Seat3_Pressed" 45 "RHS_Htd_Seat2_Pressed" 44 "RHS_Htd_Seat1_Pressed" 43 "RHS_Seat_Off_Pressed" 42 "LHS_Auto_Seat_Pressed" 41 "LHS_Htd_Seat3_Pressed" 40 "LHS_Htd_Seat2_Pressed" 39 "LHS_Htd_Seat1_Pressed" 38 "LHS_Seat_Off_Pressed" 37 "DrvrFcsdMde_Pressed" 36 "MdeMnu_Pressed" 35 "AAR_Pressed" 34 "Heat_Pressed" 33 "RearMnu_Pressed" 32 "FrontMnu_Pressed" 31 "Defrost_Pressed" 30 "Htg_Strg_Whl_Pressed" 29 "RHS_Cld_Seat_Pressed" 28 "LHS_Cld_Seat_Pressed" 27 "RHS_Htd_Seat_Pressed" 26 "LHS_Htd_Seat_Pressed" 25 "Max_Defrost_Pressed" 24 "My_Temp_Pressed" 23 "Front_Power_Pressed" 22 "Rear_Defrost_Pressed" 21 "Pnl_Flr_Ws_Pressed" 20 "Pnl_Ws_Pressed" 19 "Windscreen_Pressed" 18 "Htd_Frt_Wsh_Pressed" 17 "Auto_Recirc_Pressed" 16 "Outside_Pressed" 15 "Recirc_Pressed" 14 "Max_AC_Pressed" 13 "Auto_Pressed" 12 "Blwr_Dec_Pressed" 11 "Blwr_Inc_Pressed" 10 "RHS_Temp_Dec_Pressed" 9 "RHS_Temp_Inc_Pressed" 8 "LHS_Temp_Dec_Pressed" 7 "LHS_Temp_Inc_Pressed" 6 "Dual_Pressed" 5 "AC_Pressed" 4 "Floor_Ws_Pressed" 3 "Floor_Pressed" 2 "Panel_Floor_Pressed" 1 "Panel_Pressed" 0 "None_Pressed" ;
VAL_ 1211 E_Frt_Blwr_Speed 3 "NotUsed" 2 "Max_Blower" 1 "Min_Blower" 0 "No_Request" ;
VAL_ 1211 E_Drv_Set_Temp 31 "HI" 30 "29_5" 29 "29_0" 28 "28_5" 27 "28_0" 26 "27_5" 25 "27_0" 24 "26_5" 23 "26_0" 22 "25_5" 21 "25_0" 20 "24_5" 19 "24_0" 18 "23_5" 17 "23_0" 16 "22_5" 15 "22_0" 14 "21_5" 13 "21_0" 12 "20_5" 11 "20_0" 10 "19_5" 9 "19_0" 8 "18_5" 7 "18_0" 6 "17_5" 5 "17_0" 4 "16_5" 3 "16_0" 2 "15_5" 1 "LO" 0 "No_Request" ;
VAL_ 509 TrakAppl_D_Stat 7 "NotUsed_5" 6 "NotUsed_4" 5 "NotUsed_3" 4 "NotUsed_2" 3 "NotUsed_1" 2 "Deactivated" 1 "Cancelled" 0 "Null" ;
VAL_ 980 BattDcChrg_U_Actl 1023 "Faulty" 1022 "NoDataExists" ;
VAL_ 980 BattChrgMde_D_Actl 3 "NotUsed" 2 "ConstantCurrent" 1 "ConstantVoltage" 0 "NotCharging" ;
VAL_ 980 BattAuxCnnct_B_Cmd 1 "Close" 0 "Open" ;
VAL_ 980 PtWakeupActv2_B_Rq 1 "On" 0 "Off" ;
VAL_ 980 BattChrgCnnct_B_Cmd 1 "Close" 0 "Open" ;
VAL_ 668 SeatMtnRrMsgTxt_D_Rq 15 "NotUsed_11" 14 "NotUsed_10" 13 "NotUsed_9" 12 "NotUsed_8" 11 "NotUsed_7" 10 "NotUsed_6" 9 "NotUsed_5" 8 "NotUsed_4" 7 "NotUsed_3" 6 "NotUsed_2" 5 "NotUsed_1" 4 "SecondRowFnInhbtByVehMovin" 3 "SecondRowFnInhbtByOccupy" 2 "SeatLockReminder" 1 "Malfunction" 0 "NoMessage" ;
VAL_ 668 SeatBckMtn3r_D_Stat 7 "NotUsed_5" 6 "NotUsed_4" 5 "NotUsed_3" 4 "NotUsed_2" 3 "NotUsed_1" 2 "Folding" 1 "Opening" 0 "NotMoving" ;
VAL_ 668 SeatBckMtnRr_D_Stat 7 "NotUsed_5" 6 "NotUsed_4" 5 "NotUsed_3" 4 "NotUsed_2" 3 "NotUsed_1" 2 "Folding" 1 "Opening" 0 "NotMoving" ;
VAL_ 668 SeatBckPos3r_D_Stat 15 "Faulty" 14 "NotUsed_11" 13 "NotUsed_10" 12 "NotUsed_9" 11 "NotUsed_8" 10 "NotUsed_7" 9 "NotUsed_6" 8 "NotUsed_5" 7 "NotUsed_4" 6 "NotUsed_3" 5 "NotUsed_2" 4 "NotUsed_1" 3 "Lifted" 2 "FoldToFlat" 1 "FoldZone" 0 "ComfortZone" ;
VAL_ 668 SeatBckPosRr_D_Stat 15 "Faulty" 14 "NotUsed_11" 13 "NotUsed_10" 12 "NotUsed_9" 11 "NotUsed_8" 10 "NotUsed_7" 9 "NotUsed_6" 8 "NotUsed_5" 7 "NotUsed_4" 6 "NotUsed_3" 5 "NotUsed_2" 4 "NotUsed_1" 3 "Lifted" 2 "FoldToFlat" 1 "FoldZone" 0 "ComfortZone" ;
VAL_ 668 SeatFold3bButtn_D_Stat2 1 "Pressed" 0 "Not_Pressed" ;
VAL_ 668 SeatFold3lButtn_D_Stat2 1 "Pressed" 0 "Not_Pressed" ;
VAL_ 668 SeatFold3rButtn_D_Stat2 1 "Pressed" 0 "Not_Pressed" ;
VAL_ 668 SeatFoldRbButtn_D_Stat2 1 "Pressed" 0 "Not_Pressed" ;
VAL_ 668 SeatFoldRlButtn_D_Stat2 1 "Pressed" 0 "Not_Pressed" ;
VAL_ 668 SeatFoldRrButtn_D_Stat2 1 "Pressed" 0 "Not_Pressed" ;
VAL_ 640 SeatBckPosRl_D_Stat 15 "Faulty" 14 "NotUsed_11" 13 "NotUsed_10" 12 "NotUsed_9" 11 "NotUsed_8" 10 "NotUsed_7" 9 "NotUsed_6" 8 "NotUsed_5" 7 "NotUsed_4" 6 "NotUsed_3" 5 "NotUsed_2" 4 "NotUsed_1" 3 "Lifted" 2 "FoldToFlat" 1 "FoldZone" 0 "ComfortZone" ;
VAL_ 640 SeatBckPos3l_D_Stat 15 "Faulty" 14 "NotUsed_11" 13 "NotUsed_10" 12 "NotUsed_9" 11 "NotUsed_8" 10 "NotUsed_7" 9 "NotUsed_6" 8 "NotUsed_5" 7 "NotUsed_4" 6 "NotUsed_3" 5 "NotUsed_2" 4 "NotUsed_1" 3 "Lifted" 2 "FoldToFlat" 1 "FoldZone" 0 "ComfortZone" ;
VAL_ 640 SeatBckMtnRl_D_Stat 7 "NotUsed_5" 6 "NotUsed_4" 5 "NotUsed_3" 4 "NotUsed_2" 3 "NotUsed_1" 2 "Folding" 1 "Opening" 0 "NotMoving" ;
VAL_ 640 SeatBckMtn3l_D_Stat 7 "NotUsed_5" 6 "NotUsed_4" 5 "NotUsed_3" 4 "NotUsed_2" 3 "NotUsed_1" 2 "Folding" 1 "Opening" 0 "NotMoving" ;
VAL_ 640 SeatFoldRrButtn_D_Stat 1 "Pressed" 0 "Not_Pressed" ;
VAL_ 640 SeatFoldRlButtn_D_Stat 1 "Pressed" 0 "Not_Pressed" ;
VAL_ 640 SeatFoldRbButtn_D_Stat 1 "Pressed" 0 "Not_Pressed" ;
VAL_ 640 SeatFold3rButtn_D_Stat 1 "Pressed" 0 "Not_Pressed" ;
VAL_ 640 SeatFold3lButtn_D_Stat 1 "Pressed" 0 "Not_Pressed" ;
VAL_ 640 SeatFold3bButtn_D_Stat 1 "Pressed" 0 "Not_Pressed" ;
VAL_ 640 SeatMtnRlMsgTxt_D_Rq 15 "NotUsed_11" 14 "NotUsed_10" 13 "NotUsed_9" 12 "NotUsed_8" 11 "NotUsed_7" 10 "NotUsed_6" 9 "NotUsed_5" 8 "NotUsed_4" 7 "NotUsed_3" 6 "NotUsed_2" 5 "NotUsed_1" 4 "SecondRowFnInhbtByVehMovin" 3 "SecondRowFnInhbtByOccupy" 2 "SeatLockReminder" 1 "Malfunction" 0 "NoMessage" ;
VAL_ 1204 DcacElPwScnd_D_Stat 3 "NotUsed" 2 "High" 1 "Low" 0 "Off" ;
VAL_ 1204 DcacEngOnMsgTxt_D2_Rq 15 "NotUsed_10" 14 "NotUsed_9" 13 "NotUsed_8" 12 "NotUsed_7" 11 "NotUsed_6" 10 "NotUsed_5" 9 "NotUsed_4" 8 "NotUsed_3" 7 "NotUsed_2" 6 "NotUsed_1" 5 "AeisFinalMinutesWarning" 4 "AeisDoorAjarWarning" 3 "AeisManualOverrideWarning" 2 "DisplayQuestion" 1 "DisplayWarning" 0 "Ok" ;
VAL_ 1204 DcacOutScnd_Pw_DsplyMx 1023 "Faulty" ;
VAL_ 1204 DcacOutScnd_Pw2_Dsply 8191 "Faulty" 8190 "NoDataExists" ;
VAL_ 1204 DcacZone3Pw_B_Stat 1 "On" 0 "Off" ;
VAL_ 1204 DcacZone2Pw_B_Stat 1 "On" 0 "Off" ;
VAL_ 826 Memory_3_Sw_Stat 1 "Pressed" 0 "Null" ;
VAL_ 826 Memory_2_Sw_Stat 1 "Pressed" 0 "Null" ;
VAL_ 826 Memory_1_Sw_Stat 1 "Pressed" 0 "Null" ;
VAL_ 826 Mirror_Manual_Override 1 "Override" 0 "Null" ;
VAL_ 1159 FourthRowBucklePsngr2 7 "Faulty" 6 "OccupiedBelted" 5 "SeatAbsent" 4 "EmptyUnbelted" 3 "OccupiedUnbelted" 2 "BatteryLow" 1 "NotDetermined" 0 "EmptyBelted" ;
VAL_ 1159 FourthRowBuckleMid2 7 "Faulty" 6 "OccupiedBelted" 5 "SeatAbsent" 4 "EmptyUnbelted" 3 "OccupiedUnbelted" 2 "BatteryLow" 1 "NotDetermined" 0 "EmptyBelted" ;
VAL_ 1159 FourthRowBuckleDriver2 7 "Faulty" 6 "OccupiedBelted" 5 "SeatAbsent" 4 "EmptyUnbelted" 3 "OccupiedUnbelted" 2 "BatteryLow" 1 "NotDetermined" 0 "EmptyBelted" ;
VAL_ 1159 ThirdRowBucklePsngr2 7 "Faulty" 6 "OccupiedBelted" 5 "SeatAbsent" 4 "EmptyUnbelted" 3 "OccupiedUnbelted" 2 "BatteryLow" 1 "NotDetermined" 0 "EmptyBelted" ;
VAL_ 1159 ThirdRowBuckleMid2 7 "Faulty" 6 "OccupiedBelted" 5 "SeatAbsent" 4 "EmptyUnbelted" 3 "OccupiedUnbelted" 2 "BatteryLow" 1 "NotDetermined" 0 "EmptyBelted" ;
VAL_ 1159 ThirdRowBuckleDriver2 7 "Faulty" 6 "OccupiedBelted" 5 "SeatAbsent" 4 "EmptyUnbelted" 3 "OccupiedUnbelted" 2 "BatteryLow" 1 "NotDetermined" 0 "EmptyBelted" ;
VAL_ 1159 SecondRowBucklePsngr2 7 "Faulty" 6 "OccupiedBelted" 5 "SeatAbsent" 4 "EmptyUnbelted" 3 "OccupiedUnbelted" 2 "BatteryLow" 1 "NotDetermined" 0 "EmptyBelted" ;
VAL_ 1159 SecondRowBuckleMid2 7 "Faulty" 6 "OccupiedBelted" 5 "SeatAbsent" 4 "EmptyUnbelted" 3 "OccupiedUnbelted" 2 "BatteryLow" 1 "NotDetermined" 0 "EmptyBelted" ;
VAL_ 1159 SecondRowBuckleDriver2 7 "Faulty" 6 "OccupiedBelted" 5 "SeatAbsent" 4 "EmptyUnbelted" 3 "OccupiedUnbelted" 2 "BatteryLow" 1 "NotDetermined" 0 "EmptyBelted" ;
VAL_ 1258 TrlrCamraCalib_D_Stat 3 "NotUsed_2" 2 "NotUsed_1" 1 "Calibrating" 0 "NotCalibrating" ;
VAL_ 1258 TrlrCamraView_D_Stat 15 "NotUsed_9" 14 "NotUsed_8" 13 "NotUsed_7" 12 "NotUsed_6" 11 "NotUsed_5" 10 "NotUsed_4" 9 "NotUsed_3" 8 "NotUsed_2" 7 "NotUsed_1" 6 "TrailerRightSideView" 5 "TrailerLeftSideView" 4 "TrailerInteriorView2" 3 "TrailerInteriorView1" 2 "TrailerRearNormalView" 1 "Trailer360View" 0 "Off" ;
VAL_ 648 TrlrCamraCalib_D_Rq 3 "NotUsed_2" 2 "NotUsed_1" 1 "CalibrationRequested" 0 "CalibrationNotRequested" ;
VAL_ 1229 TrlrIspCnnct_D_Stat 3 "NotUsed_2" 2 "NotUsed_1" 1 "Connected" 0 "NotConnected" ;
VAL_ 1229 DrOpenPrvntRight_B_Rq 1 "True" 0 "False" ;
VAL_ 1229 DrOpenPrvntLeft_B_Rq 1 "True" 0 "False" ;
VAL_ 1229 ExitNotClrRight_B_Stat 1 "True" 0 "False" ;
VAL_ 1229 ExitNotClrLeft_B_Stat 1 "True" 0 "False" ;
VAL_ 1246 TrlrBrkCtl2_B_Falt 1 "True" 0 "False" ;
VAL_ 1157 SodAltLeft_D2_StatAft 3 "Faulty" 2 "ActiveDetection" 1 "ActiveNoDetection" 0 "Standby" ;
VAL_ 1158 SodAltRight_D2_StatAft 3 "Faulty" 2 "ActiveDetection" 1 "ActiveNoDetection" 0 "Standby" ;
VAL_ 1208 StopStrtImccSel_B_Rq 1 "On" 0 "Off" ;
VAL_ 1208 StopStrtImccTxt_D_Stat 7 "NotUsed_3" 6 "NotUsed_2" 5 "NotUsed_1" 4 "ClosedTimeout" 3 "ClosedYes" 2 "ClosedNo" 1 "ActiveOnDsply" 0 "NotActive" ;
VAL_ 1208 StopStrtImccSel_B_Falt 1 "Yes" 0 "No" ;
VAL_ 1208 Btt_L2_Actl2 127 "Faulty" 126 "NoDataExists" ;
VAL_ 1266 CabnScentCalbType_No_Rq 255 "NotUsed_227" 29 "NotUsed_1" 28 "HighIntnsEffectLifeRemain" 27 "MedIntnsEffectLifeRemain" 26 "LowIntnsEffectLifeRemain" 25 "HotTempEffectLifeRemain" 24 "MldTempEffectLifeRemain" 23 "CoolTempEffectLifeRemain" 22 "VHotTempFanSpdsMultiplier" 21 "HotTempFanSpdsMultiplier" 20 "WarmTempFanSpdsMultiplier" 19 "CoolTempFanSpdsMultiplier" 18 "OldAgeCartrFanMultipl" 17 "MidAgeCartrFanMultipl" 16 "YoungAgeCartrFanMultipl" 15 "MaxShelfLifeChannel3" 14 "MaxShelfLifeChannel2" 13 "MaxShelfLifeChannel1" 12 "MaxHoursRemainChannel3" 11 "MaxHoursRemainChannel2" 10 "MaxHoursRemainChannel1" 9 "DurOfPauseNoseBlndHighIntn" 8 "DurOfPauseNoseBlndMedIntns" 7 "DurOfPauseNoseBlndLowIntns" 6 "RepeatNoseBlindHighInts" 5 "RepeatNoseBlindMedInts" 4 "RepeatNoseBlindLowInts" 3 "HighIntensityBaseFanSpeed" 2 "MedIntensityBaseFanSpeed" 1 "LowIntensityBaseFanSpeed" 0 "GeneralPurpose" ;
VAL_ 1263 ActvButtnRight_D_Stat 15 "NotUsed_6" 14 "NotUsed_5" 13 "NotUsed_4" 12 "NotUsed_3" 11 "NotUsed_2" 10 "NotUsed_1" 9 "Cycle_I_RHS" 8 "Cycle_--_RHS" 7 "Cycle_O_RHS" 6 "Cycle_C_RHS" 5 "Cycle_8_RHS" 4 "PresetTwoRHS" 3 "PresetOneRHS" 2 "OffBodyRHS" 1 "OnBodyRHS" 0 "NonePressed" ;
VAL_ 1263 ActvButtnLeft_D_Stat 15 "NotUsed_6" 14 "NotUsed_5" 13 "NotUsed_4" 12 "NotUsed_3" 11 "NotUsed_2" 10 "NotUsed_1" 9 "Cycle_I_LHS" 8 "Cycle_--_LHS" 7 "Cycle_O_LHS" 6 "Cycle_C_LHS" 5 "Cycle_8_LHS" 4 "PresetTwoLHS" 3 "PresetOneLHS" 2 "OffBodyLHS" 1 "OnBodyLHS" 0 "NonePressed" ;
VAL_ 1263 CabnScentTeMsgTxt_D_Rq 3 "NotUsed" 2 "UnderTemp" 1 "OverTemp" 0 "NormalTemp" ;
VAL_ 1263 CabnScentSplr_D_Stat 15 "Supplier_15" 14 "Supplier_14" 13 "Supplier_13" 12 "Supplier_12" 11 "Supplier_11" 10 "Supplier_10" 9 "Supplier_9" 8 "Supplier_8" 7 "Supplier_7" 6 "Supplier_6" 5 "Supplier_5" 4 "Supplier_4" 3 "Supplier_3" 2 "Supplier_2" 1 "Supplier_1" 0 "NotDetermined" ;
VAL_ 1263 CabnScentMde_D_Stat 1 "AwakeScenting" 0 "AwakeNotScenting" ;
VAL_ 1263 CabnScentIntns_D_Stat 7 "High" 6 "Medium_High" 5 "Medium" 4 "Medium_Low" 3 "Low" 2 "Very_Low" 1 "Off" 0 "NotDetermined" ;
VAL_ 1263 CabnScentChnl_D_Stat 7 "Channel_7" 6 "Channel_6" 5 "Channel_5" 4 "Channel_4" 3 "Channel_3" 2 "Channel_2" 1 "Channel_1" 0 "Off" ;
VAL_ 1040 RoadGrd_Pc_Est 1023 "Faulty" ;
VAL_ 1040 ElCmpr2Enbl_B_Rq 1 "Enable" 0 "Disable" ;
VAL_ 1040 BattTrac_I2_EstVsc 262143 "Faulty" 262142 "NoDataExists" ;
VAL_ 1040 ElCmprEnbl_B_Rq 1 "Enable" 0 "Disable" ;
VAL_ 630 TrfcLghtUturnType_D_St 3 "Faulty" 2 "DirectionalArrow" 1 "RoundBall" 0 "Inactive" ;
VAL_ 630 TrfcLghtUturnOn_D_Stat 7 "Faulty" 6 "NoDataExists" 5 "NotUsed" 4 "FocusedBlink" 3 "FocusedOn" 2 "Blink" 1 "On" 0 "Inactive" ;
VAL_ 630 TrfcLghtUturnColr_D_St 7 "Faulty" 6 "NoDataExists" 5 "NotUsed_2" 4 "NotUsed_1" 3 "Green" 2 "Orange" 1 "Red" 0 "Inactive" ;
VAL_ 630 TrfcLghtUturn_T_Actl 255 "Faulty" 254 "NoDataExists" ;
VAL_ 630 TrfcLghtRightType_D_St 3 "Faulty" 2 "DirectionalArrow" 1 "RoundBall" 0 "Inactive" ;
VAL_ 630 TrfcLghtRightOn_D_Stat 7 "Faulty" 6 "NoDataExists" 5 "NotUsed" 4 "FocusedBlink" 3 "FocusedOn" 2 "Blink" 1 "On" 0 "Inactive" ;
VAL_ 630 TrfcLghtRightColr_D_St 7 "Faulty" 6 "NoDataExists" 5 "NotUsed_2" 4 "NotUsed_1" 3 "Green" 2 "Orange" 1 "Red" 0 "Inactive" ;
VAL_ 630 TrfcLghtRight_T_Actl 255 "Faulty" 254 "NoDataExists" ;
VAL_ 630 TrfcLghtLeftType_D_Stat 3 "Faulty" 2 "DirectionalArrow" 1 "RoundBall" 0 "Inactive" ;
VAL_ 630 TrfcLghtLeftOn_D_Stat 7 "Faulty" 6 "NoDataExists" 5 "NotUsed" 4 "FocusedBlink" 3 "FocusedOn" 2 "Blink" 1 "On" 0 "Inactive" ;
VAL_ 630 TrfcLghtLeftColr_D_Stat 7 "Faulty" 6 "NoDataExists" 5 "NotUsed_2" 4 "NotUsed_1" 3 "Green" 2 "Orange" 1 "Red" 0 "Inactive" ;
VAL_ 630 TrfcLghtLeft_T_Actl 255 "Faulty" 254 "NoDataExists" ;
VAL_ 630 TrfcLghtStrghtType_D_St 3 "Faulty" 2 "DirectionalArrow" 1 "RoundBall" 0 "Inactive" ;
VAL_ 630 TrfcLghtStrghtOn_D_Stat 7 "Faulty" 6 "NoDataExists" 5 "NotUsed" 4 "FocusedBlink" 3 "FocusedOn" 2 "Blink" 1 "On" 0 "Inactive" ;
VAL_ 630 TrfcLghtStrghtColr_D_St 7 "Faulty" 6 "NoDataExists" 5 "NotUsed_2" 4 "NotUsed_1" 3 "Green" 2 "Orange" 1 "Red" 0 "Inactive" ;
VAL_ 630 TrfcLghtStrght_T_Actl 255 "Faulty" 254 "NoDataExists" ;
VAL_ 627 VehToInfrstrctr_D_Stat 3 "SubComponentUnknownError" 2 "LostConnection" 1 "InServiceWithoutV2IData" 0 "InServiceFunctionOK" 7 "Faulty" 6 "NoDataExists" 5 "NotUsed_2" 4 "NotUsed_1" ;
VAL_ 627 RoadStopLineL_B_Avail 1 "On" 0 "Off" ;
VAL_ 627 RoadStopLine_L_Est 65535 "Faulty" 65534 "NoDataExists" ;
VAL_ 627 RoadSignInfo1_D_Dsply 255 "Faulty" 254 "NoDataExists" 253 "NotUsed_219" 35 "NotUsed_1" 34 "DangerRoadAhead" 33 "WaterPipeBreak" 32 "WaterOnRoad" 31 "VehiclesInQue" 30 "VehicleBreak" 29 "TunnelInWaterAhead" 28 "TrafficControlAhead" 27 "TrafficAccidentAhead" 26 "Speedlimit_120" 25 "Speedlimit_110" 24 "Speedlimit_100" 23 "Speedlimit_90" 22 "Speedlimit_80" 21 "Speedlimit_70" 20 "Speedlimit_60" 19 "Speedlimit_50" 18 "Speedlimit_40" 17 "Speedlimit_30" 16 "Speedlimit_20" 15 "Speedlimit_10" 14 "SlipperyRoad" 13 "SandstormAhead" 12 "FrozenRoad" 11 "FireAlarmOnRoad" 10 "RoadCrack" 9 "RainOrSnowRoad" 8 "Pedestrian" 7 "GoodsDrop" 6 "GasPipeLeakWarning" 5 "FogAhead" 4 "DriveWrongWay" 3 "CrossWindAhead" 2 "RoadWorksAhead" 1 "SlowTrafficAhead" 0 "Inactive" ;
VAL_ 627 TrfcLghtWarnActv_B_Stat 1 "On" 0 "Off" ;
VAL_ 627 TrfcLghtVActv_B_Stat 1 "On" 0 "Off" ;
VAL_ 627 TrfcLghtDir_D_Stat 7 "Faulty" 6 "NoDataExists" 5 "NotUsed" 4 "UtrunActivated" 3 "RightActivated" 2 "LeftActivated" 1 "StraightActivated" 0 "Inactive" ;
VAL_ 627 TrfcLghtDecel_A_Dsply 127 "Faulty" 126 "NoDataExists" ;
VAL_ 627 TrfcLght_V_Mx 255 "Faulty" 254 "NoDataExists" ;
VAL_ 627 TrfcLght_V_Mn 255 "Faulty" 254 "NoDataExists" ;
VAL_ 627 TrfcLght_D_Stat 7 "Faulty" 6 "NoDataExists" 5 "NotUsed" 4 "Four" 3 "Three" 2 "Two" 1 "One" 0 "OffOrNoMatchedLight" ;
VAL_ 874 E_Rr_Btn_Status_2nd 31 "NotUsed15" 30 "NotUsed14" 29 "NotUsed13" 28 "NotUsed12" 27 "NotUsed11" 26 "NotUsed10" 25 "NotUsed9" 24 "Third_Synch_Pressed" 23 "Third_Rr_Pwr_Pressed" 22 "Third_Auto_Pressed" 21 "Third_Pnl_Flr_Pressed" 20 "Third_Floor_Pressed" 19 "Third_Panel_Pressed" 18 "Third_Blwr_Dec_Pressed" 17 "Third_Blwr_Inc_Pressed" 16 "Rear_Lock_Pressed" 15 "RHS_Cld_Seat_Pressed" 14 "LHS_Cld_Seat_Pressed" 13 "RHS_Htd_Seat_Pressed" 12 "LHS_Htd_Seat_Pressed" 11 "Rear_Power_Pressed" 10 "AUTO_Pressed" 9 "Blwr_Dec_Pressed" 8 "Blwr_Inc_Pressed" 7 "RHS_Temp_Dec_Pressed" 6 "RHS_Temp_Inc_Pressed" 5 "LHS_Temp_Dec_Pressed" 4 "LHS_Temp_Inc_Pressed" 3 "Floor_Pressed" 2 "Panel_Floor_Pressed" 1 "Panel_Pressed" 0 "None_Pressed" ;
VAL_ 874 E_Rr_Btn_Status_1st 31 "NotUsed15" 30 "NotUsed14" 29 "NotUsed13" 28 "NotUsed12" 27 "NotUsed11" 26 "NotUsed10" 25 "NotUsed9" 24 "Third_Synch_Pressed" 23 "Third_Rr_Pwr_Pressed" 22 "Third_Auto_Pressed" 21 "Third_Pnl_Flr_Pressed" 20 "Third_Floor_Pressed" 19 "Third_Panel_Pressed" 18 "Third_Blwr_Dec_Pressed" 17 "Third_Blwr_Inc_Pressed" 16 "Rear_Lock_Pressed" 15 "RHS_Cld_Seat_Pressed" 14 "LHS_Cld_Seat_Pressed" 13 "RHS_Htd_Seat_Pressed" 12 "LHS_Htd_Seat_Pressed" 11 "Rear_Power_Pressed" 10 "AUTO_Pressed" 9 "Blwr_Dec_Pressed" 8 "Blwr_Inc_Pressed" 7 "RHS_Temp_Dec_Pressed" 6 "RHS_Temp_Inc_Pressed" 5 "LHS_Temp_Dec_Pressed" 4 "LHS_Temp_Inc_Pressed" 3 "Floor_Pressed" 2 "Panel_Floor_Pressed" 1 "Panel_Pressed" 0 "None_Pressed" ;
VAL_ 874 E_Frt_Btn_Status_2nd 63 "NotUsed_5" 62 "NotUsed_4" 61 "NotUsed_3" 60 "NotUsed_2" 59 "NotUsed_1" 58 "AUTO_Dec_Pressed" 57 "AUTO_Inc_Pressed" 56 "AUTO_Hi_Pressed" 55 "AUTO_Med_Pressed" 54 "AUTO_Lo_Pressed" 53 "RHS_Cld_Seat3_Pressed" 52 "RHS_Cld_Seat2_Pressed" 51 "RHS_Cld_Seat1_Pressed" 50 "LHS_Cld_Seat3_Pressed" 49 "LHS_Cld_Seat2_Pressed" 48 "LHS_Cld_Seat1_Pressed" 47 "RHS_Auto_Seat_Pressed" 46 "RHS_Htd_Seat3_Pressed" 45 "RHS_Htd_Seat2_Pressed" 44 "RHS_Htd_Seat1_Pressed" 43 "RHS_Seat_Off_Pressed" 42 "LHS_Auto_Seat_Pressed" 41 "LHS_Htd_Seat3_Pressed" 40 "LHS_Htd_Seat2_Pressed" 39 "LHS_Htd_Seat1_Pressed" 38 "LHS_Seat_Off_Pressed" 37 "DrvrFcsdMde_Pressed" 36 "MdeMnu_Pressed" 35 "AAR_Pressed" 34 "Heat_Pressed" 33 "RearMnu_Pressed" 32 "FrontMnu_Pressed" 31 "Defrost_Pressed" 30 "Htg_Strg_Whl_Pressed" 29 "RHS_Cld_Seat_Pressed" 28 "LHS_Cld_Seat_Pressed" 27 "RHS_Htd_Seat_Pressed" 26 "LHS_Htd_Seat_Pressed" 25 "Max_Defrost_Pressed" 24 "My_Temp_Pressed" 23 "Front_Power_Pressed" 22 "Rear_Defrost_Pressed" 21 "Pnl_Flr_Ws_Pressed" 20 "Pnl_Ws_Pressed" 19 "Windscreen_Pressed" 18 "Htd_Frt_Wsh_Pressed" 17 "Auto_Recirc_Pressed" 16 "Outside_Pressed" 15 "Recirc_Pressed" 14 "Max_AC_Pressed" 13 "Auto_Pressed" 12 "Blwr_Dec_Pressed" 11 "Blwr_Inc_Pressed" 10 "RHS_Temp_Dec_Pressed" 9 "RHS_Temp_Inc_Pressed" 8 "LHS_Temp_Dec_Pressed" 7 "LHS_Temp_Inc_Pressed" 6 "Dual_Pressed" 5 "AC_Pressed" 4 "Floor_Ws_Pressed" 3 "Floor_Pressed" 2 "Panel_Floor_Pressed" 1 "Panel_Pressed" 0 "None_Pressed" ;
VAL_ 874 E_Frt_Btn_Status_1st 63 "NotUsed_5" 62 "NotUsed_4" 61 "NotUsed_3" 60 "NotUsed_2" 59 "NotUsed_1" 58 "AUTO_Dec_Pressed" 57 "AUTO_Inc_Pressed" 56 "AUTO_Hi_Pressed" 55 "AUTO_Med_Pressed" 54 "AUTO_Lo_Pressed" 53 "RHS_Cld_Seat3_Pressed" 52 "RHS_Cld_Seat2_Pressed" 51 "RHS_Cld_Seat1_Pressed" 50 "LHS_Cld_Seat3_Pressed" 49 "LHS_Cld_Seat2_Pressed" 48 "LHS_Cld_Seat1_Pressed" 47 "RHS_Auto_Seat_Pressed" 46 "RHS_Htd_Seat3_Pressed" 45 "RHS_Htd_Seat2_Pressed" 44 "RHS_Htd_Seat1_Pressed" 43 "RHS_Seat_Off_Pressed" 42 "LHS_Auto_Seat_Pressed" 41 "LHS_Htd_Seat3_Pressed" 40 "LHS_Htd_Seat2_Pressed" 39 "LHS_Htd_Seat1_Pressed" 38 "LHS_Seat_Off_Pressed" 37 "DrvrFcsdMde_Pressed" 36 "MdeMnu_Pressed" 35 "AAR_Pressed" 34 "Heat_Pressed" 33 "RearMnu_Pressed" 32 "FrontMnu_Pressed" 31 "Defrost_Pressed" 30 "Htg_Strg_Whl_Pressed" 29 "RHS_Cld_Seat_Pressed" 28 "LHS_Cld_Seat_Pressed" 27 "RHS_Htd_Seat_Pressed" 26 "LHS_Htd_Seat_Pressed" 25 "Max_Defrost_Pressed" 24 "My_Temp_Pressed" 23 "Front_Power_Pressed" 22 "Rear_Defrost_Pressed" 21 "Pnl_Flr_Ws_Pressed" 20 "Pnl_Ws_Pressed" 19 "Windscreen_Pressed" 18 "Htd_Frt_Wsh_Pressed" 17 "Auto_Recirc_Pressed" 16 "Outside_Pressed" 15 "Recirc_Pressed" 14 "Max_AC_Pressed" 13 "Auto_Pressed" 12 "Blwr_Dec_Pressed" 11 "Blwr_Inc_Pressed" 10 "RHS_Temp_Dec_Pressed" 9 "RHS_Temp_Inc_Pressed" 8 "LHS_Temp_Dec_Pressed" 7 "LHS_Temp_Inc_Pressed" 6 "Dual_Pressed" 5 "AC_Pressed" 4 "Floor_Ws_Pressed" 3 "Floor_Pressed" 2 "Panel_Floor_Pressed" 1 "Panel_Pressed" 0 "None_Pressed" ;
VAL_ 663 BptDchrg_Pw_Dsply 1023 "Faulty" 1022 "NoDataExists" ;
VAL_ 663 Bpt_I_Est 1023 "Faulty" 1022 "NoDataExists" ;
VAL_ 663 Bpt_Pw_Allw 65535 "Faulty" 65534 "NoDataExists" ;
VAL_ 663 BptDchrg_T_Rmng 32767 "Faulty" 32766 "NoDataExists" ;
VAL_ 663 BptMnSoc_L_Actl 8191 "Faulty" 8190 "NoDataExists" ;
VAL_ 1161 BattTracUMxArry_No_Actl 31 "Faulty" ;
VAL_ 1161 BattTracCellUMx_No_Actl 255 "Faulty" 254 "NoDataExists" ;
VAL_ 1161 BattChrgUMx_B_Falt 1 "Yes" 0 "No" ;
VAL_ 1161 BattTracCellUMn_No_Actl 255 "Faulty" 254 "NoDataExists" ;
VAL_ 1161 BattTracCellCnt_No_Actl 255 "Faulty" 254 "NoDataExists" ;
VAL_ 1161 BattChrgIsltn_B_Falt 1 "Yes" 0 "No" ;
VAL_ 1161 BattTracCellDiff_B_Falt 1 "Yes" 0 "No" ;
VAL_ 1161 BattChrgSocMx_B_Falt 1 "Yes" 0 "No" ;
VAL_ 1161 BattChrgSocMn_B_Falt 1 "Yes" 0 "No" ;
VAL_ 1161 BattChrgSocErrtc_B_Falt 1 "Yes" 0 "No" ;
VAL_ 1161 BattTracUMx_B_Falt 1 "Yes" 0 "No" ;
VAL_ 1161 BattTracUMn_B_Falt 1 "Yes" 0 "No" ;
VAL_ 1161 BattTracTeMx_No_Actl 255 "Faulty" 254 "NoDataExists" ;
VAL_ 1161 BattTracTeMx_B_Falt 1 "Yes" 0 "No" ;
VAL_ 1161 BattTracTeMn_No_Actl 255 "Faulty" 254 "NoDataExists" ;
VAL_ 1161 BattTracTeDelta_B_Falt 1 "Yes" 0 "No" ;
VAL_ 1161 BattTracTeCnt_No_Actl 255 "Faulty" 254 "NoDataExists" ;
VAL_ 1161 BattTracSoftware_B_Falt 1 "Yes" 0 "No" ;
VAL_ 1121 OffRdSwtch_D_RqMnu 3 "Faulty" 2 "NoRequest" 1 "On" 0 "Off" ;
VAL_ 1121 SelDrvMdeSwtchOk_D_Stat 3 "Faulty" 2 "Pressed" 1 "NotPressed" 0 "Null" ;
VAL_ 1121 AutoHoldSwtch_D_Stat2 3 "Faulty" 2 "NotUsed" 1 "Pressed" 0 "Not_Pressed" ;
VAL_ 1121 PrkAidSwtch_D_RqDrv3 1 "Pressed" 0 "Not_Pressed" ;
VAL_ 1121 ApaSwtch_D_RqDrv3 3 "NotUsed2" 2 "NotUsed1" 1 "Pressed" 0 "Not_Pressed" ;
VAL_ 1121 StopStrtDrvMde_B_RqBtn2 1 "Pressed" 0 "Not_Pressed" ;
VAL_ 1121 SelDrvMdeSwtch_D_Stat 3 "Faulty" 2 "SwitchState2" 1 "SwitchState1" 0 "NotPressed" ;
VAL_ 1121 SelDrvMdeCnt_D_Stat 4 "FourCounts" 3 "ThreeCounts" 2 "TwoCounts" 1 "OneCount" 0 "ZeroCounts" 7 "SevenOrMoreCounts" 6 "SixCounts" 5 "FiveCounts" ;
VAL_ 669 DrHandleOuterRr_D_Stat 7 "NotUsed" 6 "Transition" 5 "FlushFault" 4 "DeployFault2" 3 "DeployFault1" 2 "Flush" 1 "Deploy" 0 "None" ;
VAL_ 669 DrHandleOuterFr_D_Stat 7 "NotUsed" 6 "Transition" 5 "FlushFault" 4 "DeployFault2" 3 "DeployFault1" 2 "Flush" 1 "Deploy" 0 "None" ;
VAL_ 571 VehFalr_Pc_Est 127 "Faulty" 126 "NoDataExists" ;
VAL_ 571 TrlrTngLoad_Pc_Est 127 "Faulty" 126 "NoDataExists" ;
VAL_ 571 TrlrTngLoad_M_Est 2047 "Faulty" 2046 "NoDataExists" ;
VAL_ 571 VehPayloadAdd_M_Est 2047 "Faulty" 2046 "NoDataExists" ;
VAL_ 571 VehPayload_Pc_Est 127 "Faulty" 126 "NoDataExists" ;
VAL_ 571 VehPayload_M_Est 1023 "Faulty" 1022 "NoDataExists" ;
VAL_ 118 BrkCtrFnd_B_Stat 1 "Yes" 0 "No" ;
VAL_ 118 BrkTerrMdeChng_D_Rdy 7 "Fault" 6 "Undefined_2" 5 "Undefined_1" 4 "ModeUnavailDrInputRqd" 3 "SpOpModes_NotSupported" 2 "ModeUnavailDynamicCond" 1 "Module_In_Initialization" 0 "Mode_Change_Available" ;
VAL_ 118 BrkTerrMde_D_Actl 7 "Fail_Safe_Default" 6 "Dynamic_Mode" 5 "Rock_Crawl_Mode" 4 "Mud_Ruts_Mode" 3 "Sand_Mode" 2 "Undefined" 1 "Low_Mu_Mode" 0 "Special_Operating_Mode_Off" ;
VAL_ 118 DrvSte_D_Stat 15 "NotUsed10" 14 "NotUsed9" 13 "NotUsed8" 12 "NotUsed7" 11 "NotUsed6" 10 "NotUsed5" 9 "NotUsed4" 8 "NotUsed3" 7 "NotUsed2" 6 "NotUsed1" 5 "Request_Active" 4 "Ignition_Off" 3 "DSR_in_Normal_Idle_Mode" 2 "EPAS_Comm_Disturbed" 1 "DSR_Request_Not_Applicable" 0 "DSR_Deactivated" ;
VAL_ 118 DrvSte_Tq_Rq 255 "Invalid" 254 "Unknown" ;
VAL_ 118 EmgcyBrkLamp_D_Rq 3 "NotUsed" 2 "Active_at_standstill" 1 "Active_at_speed" 0 "Inactive" ;
VAL_ 118 StopLamp_B_RqBrk 1 "Active" 0 "Inactive" ;
VAL_ 118 SteWhlCompAnEst_D_Qf 3 "OK" 2 "Not_Within_Specifications" 1 "No_Data_Exists" 0 "Faulty" ;
VAL_ 868 Rr_Blower_Indicate_Stat 15 "Display_Blank" 14 "14_Indicators_On" 13 "13_Indicators_On" 12 "12_Indicators_On" 11 "11_Indicators_On" 10 "10_Indicators_On" 9 "9_Indicators_On" 8 "8_Indicators_On" 7 "7_Indicators_On" 6 "6_Indicators_On" 5 "5_Indicators_On" 4 "4_Indicators_On" 3 "3_Indicators_On" 2 "2_Indicators_On" 1 "1_Indicator_On" 0 "Indicators_Off" ;
VAL_ 836 FohFalt_D_Stat 15 "NotUsed4" 14 "NotUsed3" 13 "NotUsed2" 12 "NotUsed1" 11 "FuelTypeDoesNotMatchFOH" 10 "Lifecycle_ModeNotSet" 9 "AuxElectricCoolantPumpInop" 8 "TimeDelayAvoidExcessCycl" 7 "Fuel_Level_OutofRange" 6 "External_Fault" 5 "Internal_Fault" 4 "Voltage_limitation" 3 "Impact_Event" 2 "CoolantTemp_OutofRange" 1 "AmbientTemp_OutofRange" 0 "No_Disable" ;
VAL_ 836 FohEnbl_B_RqDrv 1 "On" 0 "Off" ;
VAL_ 836 FohRqRun_B_Rq 1 "SubmitRequest_toRun" 0 "DoesNotSubmitRequest_toRun" ;
VAL_ 836 HvacPrecondMode_D_Rq 15 "NotUsed4" 14 "NotUsed3" 13 "NotUsed2" 12 "Low_Blower_Auto" 11 "Last_User_Settings" 10 "Auto" 9 "Max_Defrost" 8 "Windshield_Panel_Floor" 7 "Windshield_Panel" 6 "Windshield" 5 "Windshield_Floor" 4 "Floor" 3 "Panel_Floor" 2 "Panel" 1 "MAX_AC" 0 "Off" ;
VAL_ 836 HvacPrecondBlwr_D_Rq 15 "NotUsed6" 14 "NotUsed5" 13 "NotUsed4" 12 "NotUsed3" 11 "NotUsed2" 10 "NotUsed1" 9 "Last_User_Setting" 8 "Auto" 7 "Speed7" 6 "Speed6" 5 "Speed5" 4 "Speed4" 3 "Speed3" 2 "Speed2" 1 "Speed1" 0 "Off" ;
VAL_ 836 Foh_D_Stat 7 "Unused3" 6 "Unused2" 5 "Unused1" 4 "Stopping" 3 "Running" 2 "Starting" 1 "Prestart" 0 "Off" ;
VAL_ 836 EngClnt_Te_ActlFoh 255 "Fault" ;
VAL_ 613 BeltWarnThres_D_Stat 7 "Faulty" 6 "No_Data_Exists" 5 "NotUsed3" 4 "NotUsed2" 3 "NotUsed1" 2 "Over_Threshold" 1 "Under_Threshold" 0 "NotSupported" ;
VAL_ 613 VehicleMYCalibrationId 255 "Invalid" ;
VAL_ 613 VehicleCalibrationId 255 "Invalid" ;
VAL_ 613 OCSSensrDataUpperLim 255 "Invalid" ;
VAL_ 613 OCSSensrDataLowerLim 255 "Invalid" ;
VAL_ 613 OCSLevel2Error 1 "Yes" 0 "No" ;
VAL_ 613 ObjectEntrapped 1 "Yes" 0 "No" ;
VAL_ 613 OCSLevel1Error 1 "Yes" 0 "No" ;
VAL_ 1084 BattULoState_D_Qlty 3 "OK" 2 "Not_Within_Specifications" 1 "Eval_In_Progress" 0 "Fault" ;
VAL_ 1084 BSFault 1 "Fault" 0 "No_Fault" ;
VAL_ 1084 BattULo2_Te_Actl 127 "Fault" ;
VAL_ 1059 EngStrtInhbt_B_RqBatt 1 "Start_Inhibit" 0 "Dont_Care" ;
VAL_ 1059 BattULoChrg_D_Rq 3 "Low_Battery_Temperature" 2 "Charging_Requested" 1 "Chrg_Requested_HighCurrent" 0 "No_Request" ;
VAL_ 1059 PwSysULoFalt_D_Stat 15 "Not_Used_6" 14 "LowBatterySOC" 13 "PSS_Shed2_Contin" 12 "Not_Used_4" 11 "Not_Used_3" 10 "Not_Used_2" 9 "BattMonitoringSensorFault" 8 "LowBattVoltDuringPwSrcOn" 7 "LowBatt2_PowerSaveMode" 6 "LowBatt1_Warning" 5 "Overvoltage" 4 "Fault_NoOutput" 3 "Fault_ReducedOutput" 2 "Fault_Nonspecific" 1 "Cluster_Proveout" 0 "No_Fault" ;
VAL_ 1059 Shed_T_Eng_Off_B 1 "Active" 0 "Inactive" ;
VAL_ 1059 Shed_Feature_Group_ID 16 "PtcHeater" 30 "NotUsed_7" 29 "NotUsed_6" 28 "NotUsed_5" 27 "NotUsed_4" 26 "NotUsed_3" 25 "NotUsed_2" 24 "NotUsed_1" 23 "Dcac" 22 "UpFitter_6" 21 "UpFitter_5" 20 "UpFitter_4" 19 "UpFitter_3" 18 "UpFitter_2" 17 "UpFitter_1" 14 "HtdMirr" 13 "HvacRearBlwr_Third" 12 "HvacRearBlwr_Second" 11 "HvacRearBlwr_First" 31 "All LSHED1 Features" 10 "Htd_Windscrn" 9 "SpltHtdBcklight_HtdMirr" 8 "HtdBcklight_HtdMirr" 7 "HtdCoolSeat_FrtDriver" 6 "HtdCoolSeat_FrtPass" 5 "HtdCoolSeat_RearPass" 4 "HtdCoolSeat_RearDriver" 3 "SmartTrlrTowBattCharge" 2 "Htd_StrWhl" 1 "Htd_Washer_Fluid" 0 "No_LSHED1_Features" 15 "Engine_Coolant_Fan" ;
VAL_ 1059 Shed_Drain_Eng_Off_B 1 "Active" 0 "Inactive" ;
VAL_ 1059 Shed_Level_Req 7 "SHED3" 6 "Loads_On" 5 "SHED_ENG_OFF" 4 "SOON_ENG_OFF" 3 "SHED2_CONTIN" 2 "SHED2_TRANS" 1 "SHED1" 0 "NO_SHED" ;
VAL_ 1059 ULoRgenTestMde_B_Rq 1 "Request" 0 "NoRequest" ;
VAL_ 1059 ChargeMode 7 "Undefined_2" 6 "Undefined_1" 5 "Battery_Identify" 4 "Battery_Refresh" 3 "SlowRegenAllowNoDischarge" 2 "Fast_Regen_Allowed" 1 "Slow_Regen_Allowed" 0 "Conventional_Charging" ;
VAL_ 1059 IdleSpeedIncrease_El 1 "Yes" 0 "No" ;
VAL_ 1059 Batt_Lo_SoC_B 1 "Active" 0 "Inactive" ;
VAL_ 1059 PeriodicElLoad_B_Stat 1 "Active" 0 "Inactive" ;
VAL_ 1059 Batt_Crit_SoC_B 1 "Active" 0 "Inactive" ;
VAL_ 131 ElPwAsstSte_B_RqDactv 1 "Request" 0 "NoRequest" ;
VAL_ 131 HeadLghtHiCtrl_D_RqAhb 7 "NotUsed2" 6 "NotUsed1" 5 "Auto_HiBeam" 4 "Auto_LoBeam" 3 "Flash" 2 "Man_HiBeam" 1 "Man_LoBeam" 0 "Null" ;
VAL_ 131 AhbStat_B_Dsply 1 "On" 0 "Off" ;
VAL_ 131 WiprFrontSwtch_D_Stat 15 "NotUsed6" 14 "NotUsed5" 13 "NotUsed4" 12 "NotUsed3" 11 "NotUsed2" 10 "NotUsed1" 9 "PositionNotDetermined" 8 "High" 7 "Low" 6 "Position6" 5 "Position5" 4 "Position4" 3 "Position3" 2 "Position2" 1 "Position1" 0 "Off" ;
VAL_ 131 HeadLghtHiOn_B_StatAhb 1 "On" 0 "Off" ;
VAL_ 131 HeadLghtHiFlash_D_Actl 3 "NotUsed" 2 "High" 1 "Flash_to_Pass" 0 "Null" ;
VAL_ 131 TjaButtnOnOffPress 1 "Pressed" 0 "Not_Pressed" ;
VAL_ 131 AccButtnGapTogglePress 1 "Pressed" 0 "Not_Pressed" ;
VAL_ 131 WiprFront_D_Stat 15 "NO_DATA_EXISTS" 14 "STALLED" 13 "RESERVED" 12 "AUTO_ADJUST" 11 "COURTESYWIPE" 10 "AUTO_HIGH" 9 "AUTO_LOW" 8 "WASH" 7 "MIST_FLICK" 6 "MAN_HIGH" 5 "MAN_LOW" 4 "MAN_INT_ON" 3 "MAN_INT_OFF" 2 "OFF_MOVING" 1 "AUTO_OFF" 0 "OFF" ;
VAL_ 131 TurnLghtSwtch_D_Stat 3 "Unused_Treat_As_Off" 2 "Right" 1 "Left" 0 "Off" ;
VAL_ 131 LghtAmb_D_Sns 7 "No_Data_Exists" 6 "Unused2" 5 "Unused1" 4 "Tunnel_Off" 3 "Tunnel_On" 2 "Twilight" 1 "Light" 0 "Dark" ;
VAL_ 131 AccButtnGapIncPress 1 "Button_Pressed" 0 "Button_Not_Pressed" ;
VAL_ 131 AccButtnGapDecPress 1 "Button_Pressed" 0 "Button_Not_Pressed" ;
VAL_ 131 AslButtnOnOffPress 1 "Button_Pressed" 0 "Button_Not_Pressed" ;
VAL_ 131 AslButtnOnOffCnclPress 1 "Button_Pressed" 0 "Button_Not_Pressed" ;
VAL_ 131 CcButtnOnPress 1 "Button_Pressed" 0 "Button_Not_Pressed" ;
VAL_ 131 CcButtnOnOffPress 1 "Button_Pressed" 0 "Button_Not_Pressed" ;
VAL_ 131 CcButtnOnOffCnclPress 1 "Button_Pressed" 0 "Button_Not_Pressed" ;
VAL_ 131 CcButtnOffPress 1 "Button_Pressed" 0 "Button_Not_Pressed" ;
VAL_ 131 CcAsllButtnResPress 1 "Button_Pressed" 0 "Button_Not_Pressed" ;
VAL_ 131 CcAslButtnSetPress 1 "Button_Pressed" 0 "Button_Not_Pressed" ;
VAL_ 131 CcAslButtnSetIncPress 1 "Button_Pressed" 0 "Button_Not_Pressed" ;
VAL_ 131 CcAslButtnSetDecPress 1 "Button_Pressed" 0 "Button_Not_Pressed" ;
VAL_ 131 CcAslButtnResIncPress 1 "Button_Pressed" 0 "Button_Not_Pressed" ;
VAL_ 131 CcAslButtnResDecPress 1 "Button_Pressed" 0 "Button_Not_Pressed" ;
VAL_ 131 CcAslButtnOnPress 1 "Button_Pressed" 0 "Button_Not_Pressed" ;
VAL_ 131 CcAslButtnOnOffCncl 1 "Button_Pressed" 0 "Button_Not_Pressed" ;
VAL_ 131 CcAslButtnOffCnclPress 1 "Button_Pressed" 0 "Button_Not_Pressed" ;
VAL_ 131 CcAslButtnIndxIncPress 1 "Button_Pressed" 0 "Button_Not_Pressed" ;
VAL_ 131 CcAslButtnIndxDecPress 1 "Button_Pressed" 0 "Button_Not_Pressed" ;
VAL_ 131 CcAslButtnDeny_B_Actl 1 "Yes" 0 "No" ;
VAL_ 131 CcAslButtnCnclResPress 1 "Button_Pressed" 0 "Button_Not_Pressed" ;
VAL_ 131 CcAslButtnCnclPress 1 "Button_Pressed" 0 "Button_Not_Pressed" ;
VAL_ 131 LaSwtchPos_D_Stat 3 "Fault" 2 "Unused" 1 "Pressed" 0 "Open" ;
VAL_ 931 VehOnSrc_D_Stat 15 "NotUsed_11" 14 "NotUsed_10" 13 "NotUsed_9" 12 "NotUsed_8" 11 "NotUsed_7" 10 "NotUsed_6" 9 "EsclRssd" 8 "AutonomousVehicle" 7 "SecureIdle" 6 "FleetVehicleInhibit" 5 "StolenVehicleInhibit" 4 "OverTheAir" 3 "RemoteParkAssist" 2 "RemoteStart" 1 "Manual" 0 "Off" ;
VAL_ 931 EngStrtActv_B_Stat 1 "Active" 0 "Inactive" ;
VAL_ 931 EngStrt_B_Rq 1 "Request" 0 "NoRequest" ;
VAL_ 931 DrvInCtl_B_Stat 1 "Yes" 0 "No" ;
VAL_ 931 PtWakeReas_D_Stat 15 "NotUsed_9" 14 "NotUsed_8" 13 "NotUsed_7" 12 "NotUsed_6" 11 "NotUsed_5" 10 "NotUsed_4" 9 "NotUsed_3" 8 "NotUsed_2" 7 "NotUsed_1" 6 "ElapsedTime" 5 "ThirdPartyWakeup" 4 "DoorAjar" 3 "EarlyWake" 2 "NonMotiveStart" 1 "MotiveStart" 0 "Null" ;
VAL_ 931 CrnkInhbt_B_Stat 1 "Inhibit" 0 "NoInhibit" ;
VAL_ 931 IgnPreOffActv_B_Stat 1 "Active" 0 "Inactive" ;
VAL_ 618 PaakLoclzd_D_Stat 15 "NotUsed_12" 14 "NotUsed_11" 13 "NotUsed_10" 12 "NotUsed_9" 11 "NotUsed_8" 10 "NotUsed_7" 9 "NotUsed_6" 8 "NotUsed_5" 7 "NotUsed_4" 6 "NotUsed_3" 5 "NotUsed_2" 4 "NotUsed_1" 3 "FullLoc" 2 "PausedLoc" 1 "MaintainLink" 0 "BackgroundScan" ;
VAL_ 618 IgnPsswrdSetup_B_Rq 1 "Active" 0 "Inactive" ;
VAL_ 618 IgnPsswrdLckout_B_Stat 1 "Active" 0 "Inactive" ;
VAL_ 618 PaakCtlType_D_Stat 3 "NotUsed" 2 "Valid" 1 "Invalid" 0 "Null" ;
VAL_ 618 PaakCtlData_D_Stat 7 "NotUsed_3" 6 "NotUsed_2" 5 "NotUsed_1" 4 "Response" 3 "EchoTargetIdBlock1" 2 "RequestTargetIdBlock2" 1 "RequestTargetIdBlock1" 0 "Idle" ;
VAL_ 621 IgnPsswrdActv_B_Stat 1 "Active" 0 "Inactive" ;
VAL_ 621 FobTrgtZone_D_Rq 15 "NotUsed_9" 14 "NotUsed_8" 13 "NotUsed_7" 12 "NotUsed_6" 11 "NotUsed_5" 10 "NotUsed_4" 9 "NotUsed_3" 8 "NotUsed_2" 7 "NotUsed_1" 6 "Approach" 5 "RearInterior" 4 "RearExterior" 3 "Passenger" 2 "Driver" 1 "Interior" 0 "Null" ;
VAL_ 621 FobTrgtType_D_Rq 7 "NotUsed_4" 6 "NotUsed_3" 5 "NotUsed_2" 4 "NotUsed_1" 3 "Polling" 2 "Registry" 1 "Crypto" 0 "Null" ;
VAL_ 621 RmtCtlRjctAutoCfg_B_Rq 1 "Yes" 0 "No" ;
VAL_ 621 RmtCtlSelSlot_D_Rq 7 "NotUsed_3" 6 "NotUsed_2" 5 "NotUsed_1" 4 "Right" 3 "Left" 2 "Rear" 1 "Front" 0 "None" ;
VAL_ 621 RmtCtlSelPrkMde_D_Rq 3 "NotUsed" 2 "FreeDrive" 1 "ParkIn" 0 "None" ;
VAL_ 621 RmtCtlSelMoveDir_D_Rq 3 "NotUsed" 2 "Backward" 1 "Forward" 0 "None" ;
VAL_ 1016 ChrgGoTElement_B_Dsply 1 "Yes" 0 "No" ;
VAL_ 1016 ChrgGoTTouchEnbl_B_Rq 1 "Request" 0 "NoRequest" ;
VAL_ 1016 ChrgGoTTouch_B_Stat 1 "On" 0 "Off" ;
VAL_ 1016 ChrgGoTPrcond_D_Stat 3 "High" 2 "Medium" 1 "Low" 0 "Off" ;
VAL_ 1016 ChrgGoTMnte_D_Stat 15 "NotUsed_4" 14 "NotUsed_3" 13 "NotUsed_2" 12 "NotUsed_1" 11 "Minute_55" 10 "Minute_50" 9 "Minute_45" 8 "Minute_40" 7 "Minute_35" 6 "Minute_30" 5 "Minute_25" 4 "Minute_20" 3 "Minute_15" 2 "Minute_10" 1 "Minute_5" 0 "Minute_0" ;
VAL_ 1016 ChrgGoTHr_T_Stat 31 "Faulty" 30 "NoDataExists" ;
VAL_ 1016 ChrgGoTExtHtrEnbl_B_Rq 1 "Request" 0 "NoRequest" ;
VAL_ 1016 ChrgGoTExtHtr_B_Stat 1 "On" 0 "Off" ;
VAL_ 1016 ChrgGoTAllOn_B_Stat 1 "On" 0 "Off" ;
VAL_ 773 StmsScrnPsngrOn_B_Rq 1 "On" 0 "Off" ;
VAL_ 773 SeatScrnPsngrOn_B_Rq 1 "On" 0 "Off" ;
VAL_ 773 SeatPsngrMem_D_Cmd 15 "NotUsed_7" 14 "NotUsed_6" 13 "NotUsed_5" 12 "NotUsed_4" 11 "NotUsed_3" 10 "NotUsed_2" 9 "NotUsed_1" 8 "RECALL_4" 7 "RECALL_3" 6 "RECALL_2" 5 "RECALL_1" 4 "STORE_4" 3 "STORE_3" 2 "STORE_2" 1 "STORE_1" 0 "Null" ;
VAL_ 773 MemSwtchPsngrFdbck_B_Rq 1 "Yes" 0 "No" ;
VAL_ 389 HtrnSrvcRqd_B_Dsply 1 "On" 0 "Off" ;
VAL_ 389 HtrnOvrTeLamp_B_Dsply 1 "On" 0 "Off" ;
VAL_ 389 HtrnMil_D_Rq 3 "Not_Used" 2 "Flash" 1 "On" 0 "Off" ;
VAL_ 389 HtrnAin_UHi_Actl 1023 "Fault" 1022 "Unknown" ;
VAL_ 389 HtrnHvilOpen_B_Actl 1 "HVIL_is_Open" 0 "Normal_Operation" ;
VAL_ 389 PtWakeupDeltaT_T_Rq 2047 "Fault" 2046 "NoDataExists" ;
VAL_ 389 PreCondActv_B_Actl 1 "On" 0 "Off" ;
VAL_ 389 DrvCondTpRrDefrs_B_Rq 1 "On" 0 "Off" ;
VAL_ 389 BattTrac_I_EstVsc 32767 "Fault" 32766 "NoDataExists" ;
VAL_ 1128 DgtlCommGtwyMde_D_Rq 15 "NotUsed_10" 14 "NotUsed_9" 13 "NotUsed_8" 12 "NotUsed_7" 11 "NotUsed_6" 10 "NotUsed_5" 9 "NotUsed_4" 8 "NotUsed_3" 7 "NotUsed_2" 6 "NotUsed_1" 5 "AcPnC" 4 "AcEIM" 3 "DcPnC" 2 "DcEIM" 1 "AttemptDgtlComm" 0 "NoDgtlComm" ;
VAL_ 1128 ChrgrDcOvrVolt_B_Falt 1 "Yes" 0 "No" ;
VAL_ 1128 ChrgrDcOvrCurnt_B_Falt 1 "Yes" 0 "No" ;
VAL_ 1128 ExtChrgNowButtn_B_Rq 1 "Request" 0 "NoRequest" ;
VAL_ 1128 CoolFanChrgr_D_Rq 3 "High" 2 "Medium" 1 "Low" 0 "Off" ;
VAL_ 1128 ChrgrPncEnbl_D_Stat 3 "NotUsed" 2 "Enable" 1 "Disable" 0 "Null" ;
VAL_ 1128 ChrgrClntFlw_D_Rq 3 "High" 2 "Medium" 1 "Low" 0 "Off" ;
VAL_ 1128 PlgStatEvnt_B_Stat 1 "Active" 0 "Inactive" ;
VAL_ 1128 ChrgrCnnctPwr_B_Stat 1 "Asserted" 0 "NotAsserted" ;
VAL_ 1128 ChrgrAvailEvnt_B_Stat 1 "Active" 0 "Inactive" ;
VAL_ 1128 ChrgrSrvcRqd_B_Rq 1 "On" 0 "Off" ;
VAL_ 1128 ChrgrS2Swtch_B_Stat 1 "Close" 0 "Open" ;
VAL_ 1128 ChrgChngEvnt_B_Stat 1 "Active" 0 "Inactive" ;
VAL_ 1128 ChrgrCc2Cnnct_B_Falt 1 "Yes" 0 "No" ;
VAL_ 1128 ChrgPortDcTeMx_B_Falt 1 "Yes" 0 "No" ;
VAL_ 1128 ChrgCordLck_D_Stat 7 "Faulty" 6 "LockFail" 5 "UnlockFail" 4 "LockInProgress" 3 "UnlockInProgress" 2 "Lock" 1 "Unlock" 0 "Retain" ;
VAL_ 1128 ChrgrInPwMde_D_Actl 15 "NotUsed_5" 14 "NotUsed_4" 13 "NotUsed_3" 12 "NotUsed_2" 11 "NotUsed_1" 10 "DcBpt" 9 "DigitalCommEnd" 8 "EvseFault" 7 "EvseNotCompatible" 6 "IcCharging" 5 "DcCharging" 4 "AcDigital" 3 "AcBasic" 2 "DigitalCommDetected" 1 "EvsePaused" 0 "EvseNotDetected" ;
VAL_ 1128 ChrgPortDrOpen_B_Stat 1 "True" 0 "False" ;
VAL_ 1128 AcChrgRdy_B_Stat 1 "True" 0 "False" ;
VAL_ 1128 BptTgl_B_Complt 1 "Yes" 0 "No" ;
VAL_ 1128 ChrgCrdLck_D_Falt 3 "NotUsed" 2 "HardwareFault" 1 "CsiFault" 0 "NoFault" ;
VAL_ 594 HvacAirFlw_B_RqBatt 1 "Request" 0 "NoRequest" ;
VAL_ 594 BattChrgRdyStat_D_Actl 7 "NotUsed2" 6 "NotUsed1" 5 "Faulted" 4 "ChargeComplete" 3 "Charging" 2 "BatteryChargeReady" 1 "ChargeWait" 0 "NotReady" ;
VAL_ 594 BattTracSoc_Pc_Dsply 255 "Faulty" 254 "NoDataExists" ;
VAL_ 594 BattTracSoc2_Pc_Actl 16383 "Faulty" 16382 "NoDataExists" ;
VAL_ 594 BattTracCool_D_Falt 3 "NotUsed" 2 "CoolSysPartialyOperational" 1 "Cooling_System_Faulted" 0 "Cooling_System_Operational" ;
VAL_ 594 BattTracClntIn_Te_Actl 255 "Fault" ;
VAL_ 594 BattTrac_Te_Actl 1023 "Fault" 1022 "Unknown" ;
VAL_ 594 HvacRec_D_RqMxBatt 15 "NotUsed5" 14 "NotUsed4" 13 "NotUsed3" 12 "NotUsed2" 11 "NotUsed1" 10 "No_Override" 9 "90Percent_RecircMax" 8 "80Percent_RecircMax" 7 "70Percent_RecircMax" 6 "60Percent_RecircMax" 5 "50Percent_RecircMax" 4 "40Percent_RecircMax" 3 "30Percent_RecircMax" 2 "20Percent_RecircMax" 1 "10Percent_RecircMax" 0 "0Percent_RecircFullOpen" ;
VAL_ 594 HvacAir_Flw_EstBatt 255 "Invalid" ;
VAL_ 932 ChildLck_D_Dsply 3 "NOT_SUPPORTED" 2 "ERROR" 1 "CHILD_UNLOCK" 0 "CHILD_LOCK" ;
VAL_ 932 RmtCtlBattMntr_B_Falt 1 "Yes" 0 "No" ;
VAL_ 932 VehStrtInhbt_D_Stat 1 "Inhibit" 0 "NoInhibit" ;
VAL_ 932 VehOnCtl_D_Stat 3 "NotUsed" 2 "On" 1 "Off" 0 "Null" ;
VAL_ 932 VehOnSrc2_D_Stat 15 "NotUsed_11" 14 "NotUsed_10" 13 "NotUsed_9" 12 "NotUsed_8" 11 "NotUsed_7" 10 "NotUsed_6" 9 "EsclRssd" 8 "AutonomousVehicle" 7 "SecureIdle" 6 "FleetVehicleInhibit" 5 "StolenVehicleInhibit" 4 "OverTheAir" 3 "RemoteParkAssist" 2 "RemoteStart" 1 "Manual" 0 "Off" ;
VAL_ 932 VehInhbtMde_D_Stat 7 "NotUsed_3" 6 "NotUsed_2" 5 "NotUsed_1" 4 "FullVehicleOta" 3 "Iviota" 2 "SyncOta" 1 "NoOtaSupport" 0 "Unconfigured" ;
VAL_ 528 TireInflateMsgTxt_B_Rq 1 "Yes" 0 "No" ;
VAL_ 528 OffRoadMde_D_Stat 7 "NotUsed_5" 6 "NotUsed_4" 5 "NotUsed_3" 4 "NotUsed_2" 3 "NotUsed_1" 2 "Off_Road2" 1 "Off_Road1" 0 "On_Road" ;
VAL_ 591 BattTrac_U_Nom 1023 "Faulty" 1022 "NoDataExists" ;
VAL_ 591 BattTrac_E_Nom 4095 "Faulty" 4094 "NoDataExists" ;
VAL_ 591 BattTrac_Ah_Nom 4095 "Faulty" ;
VAL_ 591 BattTracType_D_Actl 15 "NotUsed_7" 14 "NotUsed_6" 13 "NotUsed_5" 12 "NotUsed_4" 11 "NotUsed_3" 10 "NotUsed_2" 9 "NotUsed_1" 8 "Other" 7 "LithiumTitanateOxide" 6 "LithiumIonPolymer" 5 "TernaryMaterial" 4 "LithiumCobaltOxide" 3 "LithiumManganese" 2 "LithiumIronPhosphate" 1 "NickelMetalHydride" 0 "LeadAcid" ;
VAL_ 591 BattChrgRqd_E_Actl 4095 "Faulty" 4094 "NoDataExists" ;
VAL_ 595 TrakApplActvSet_D_Rq 15 "NotUsed_12" 14 "NotUsed_11" 13 "NotUsed_10" 12 "NotUsed_9" 11 "NotUsed_8" 10 "NotUsed_7" 9 "NotUsed_6" 8 "NotUsed_5" 7 "NotUsed_4" 6 "NotUsed_3" 5 "NotUsed_2" 4 "NotUsed_1" 3 "AccTimer_Start_Track" 2 "AccTimer_Start_Drag" 1 "AccTimer_Start_Automatic" 0 "Null" ;
VAL_ 595 TrakAppl_D_RqMnu 31 "NotUsed_15" 30 "NotUsed_14" 29 "NotUsed_13" 28 "NotUsed_12" 27 "NotUsed_11" 26 "NotUsed_10" 25 "NotUsed_9" 24 "NotUsed_8" 23 "NotUsed_7" 22 "NotUsed_6" 21 "NotUsed_5" 20 "NotUsed_4" 19 "NotUsed_3" 18 "NotUsed_2" 17 "NotUsed_1" 16 "Activate_LineLock" 15 "Activate_LapTimer" 14 "Activate_400m" 13 "Activate_200m" 12 "Activate_1/4mile" 11 "Activate_1/8mile" 10 "Activate_0-200kph" 9 "Activate_0-100kph" 8 "Activate_0-50kph" 7 "Activate_0-100mph" 6 "Activate_0-60mph" 5 "Activate_0-30mph" 4 "Activate_200-0kph" 3 "Activate_100-0kph" 2 "Activate_100-0mph" 1 "Activate_60-0mph" 0 "Deactivate_TrackApp" ;
VAL_ 595 EngIdlShutDownT_D_Rq 255 "NotUsed_13" 254 "NotUsed_12" 253 "NotUsed_11" 252 "NotUsed_10" 251 "NotUsed_9" 250 "NotUsed_8" 249 "NotUsed_7" 248 "NotUsed_6" 247 "NotUsed_5" 246 "NotUsed_4" 245 "NotUsed_3" 244 "NotUsed_2" 243 "NotUsed_1" 242 "Indefinite_Idle" 241 "Selectable_Idle_Not_Active" 240 "IdleMinutes_240" 239 "IdleMinutes_239" 238 "IdleMinutes_238" 237 "IdleMinutes_237" 236 "IdleMinutes_236" 235 "IdleMinutes_235" 234 "IdleMinutes_234" 233 "IdleMinutes_233" 232 "IdleMinutes_232" 231 "IdleMinutes_231" 230 "IdleMinutes_230" 229 "IdleMinutes_229" 228 "IdleMinutes_228" 227 "IdleMinutes_227" 226 "IdleMinutes_226" 225 "IdleMinutes_225" 224 "IdleMinutes_224" 223 "IdleMinutes_223" 222 "IdleMinutes_222" 221 "IdleMinutes_221" 220 "IdleMinutes_220" 219 "IdleMinutes_219" 218 "IdleMinutes_218" 217 "IdleMinutes_217" 216 "IdleMinutes_216" 215 "IdleMinutes_215" 214 "IdleMinutes_214" 213 "IdleMinutes_213" 212 "IdleMinutes_212" 211 "IdleMinutes_211" 210 "IdleMinutes_210" 209 "IdleMinutes_209" 208 "IdleMinutes_208" 207 "IdleMinutes_207" 206 "IdleMinutes_206" 205 "IdleMinutes_205" 204 "IdleMinutes_204" 203 "IdleMinutes_203" 202 "IdleMinutes_202" 201 "IdleMinutes_201" 200 "IdleMinutes_200" 199 "IdleMinutes_199" 198 "IdleMinutes_198" 197 "IdleMinutes_197" 196 "IdleMinutes_196" 195 "IdleMinutes_195" 194 "IdleMinutes_194" 193 "IdleMinutes_193" 192 "IdleMinutes_192" 191 "IdleMinutes_191" 190 "IdleMinutes_190" 189 "IdleMinutes_189" 188 "IdleMinutes_188" 187 "IdleMinutes_187" 186 "IdleMinutes_186" 185 "IdleMinutes_185" 184 "IdleMinutes_184" 183 "IdleMinutes_183" 182 "IdleMinutes_182" 181 "IdleMinutes_181" 180 "IdleMinutes_180" 179 "IdleMinutes_179" 178 "IdleMinutes_178" 177 "IdleMinutes_177" 176 "IdleMinutes_176" 175 "IdleMinutes_175" 174 "IdleMinutes_174" 173 "IdleMinutes_173" 172 "IdleMinutes_172" 171 "IdleMinutes_171" 170 "IdleMinutes_170" 169 "IdleMinutes_169" 168 "IdleMinutes_168" 167 "IdleMinutes_167" 166 "IdleMinutes_166" 165 "IdleMinutes_165" 164 "IdleMinutes_164" 163 "IdleMinutes_163" 162 "IdleMinutes_162" 161 "IdleMinutes_161" 160 "IdleMinutes_160" 159 "IdleMinutes_159" 158 "IdleMinutes_158" 157 "IdleMinutes_157" 156 "IdleMinutes_156" 155 "IdleMinutes_155" 154 "IdleMinutes_154" 153 "IdleMinutes_153" 152 "IdleMinutes_152" 151 "IdleMinutes_151" 150 "IdleMinutes_150" 149 "IdleMinutes_149" 148 "IdleMinutes_148" 147 "IdleMinutes_147" 146 "IdleMinutes_146" 145 "IdleMinutes_145" 144 "IdleMinutes_144" 143 "IdleMinutes_143" 142 "IdleMinutes_142" 141 "IdleMinutes_141" 140 "IdleMinutes_140" 139 "IdleMinutes_139" 138 "IdleMinutes_138" 137 "IdleMinutes_137" 136 "IdleMinutes_136" 135 "IdleMinutes_135" 134 "IdleMinutes_134" 133 "IdleMinutes_133" 132 "IdleMinutes_132" 131 "IdleMinutes_131" 130 "IdleMinutes_130" 129 "IdleMinutes_129" 128 "IdleMinutes_128" 127 "IdleMinutes_127" 126 "IdleMinutes_126" 125 "IdleMinutes_125" 124 "IdleMinutes_124" 123 "IdleMinutes_123" 122 "IdleMinutes_122" 121 "IdleMinutes_121" 120 "IdleMinutes_120" 119 "IdleMinutes_119" 118 "IdleMinutes_118" 117 "IdleMinutes_117" 116 "IdleMinutes_116" 115 "IdleMinutes_115" 114 "IdleMinutes_114" 113 "IdleMinutes_113" 112 "IdleMinutes_112" 111 "IdleMinutes_111" 110 "IdleMinutes_110" 109 "IdleMinutes_109" 108 "IdleMinutes_108" 107 "IdleMinutes_107" 106 "IdleMinutes_106" 105 "IdleMinutes_105" 104 "IdleMinutes_104" 103 "IdleMinutes_103" 102 "IdleMinutes_102" 101 "IdleMinutes_101" 100 "IdleMinutes_100" 99 "IdleMinutes_99" 98 "IdleMinutes_98" 97 "IdleMinutes_97" 96 "IdleMinutes_96" 95 "IdleMinutes_95" 94 "IdleMinutes_94" 93 "IdleMinutes_93" 92 "IdleMinutes_92" 91 "IdleMinutes_91" 90 "IdleMinutes_90" 89 "IdleMinutes_89" 88 "IdleMinutes_88" 87 "IdleMinutes_87" 86 "IdleMinutes_86" 85 "IdleMinutes_85" 84 "IdleMinutes_84" 83 "IdleMinutes_83" 82 "IdleMinutes_82" 81 "IdleMinutes_81" 80 "IdleMinutes_80" 79 "IdleMinutes_79" 78 "IdleMinutes_78" 77 "IdleMinutes_77" 76 "IdleMinutes_76" 75 "IdleMinutes_75" 74 "IdleMinutes_74" 73 "IdleMinutes_73" 72 "IdleMinutes_72" 71 "IdleMinutes_71" 70 "IdleMinutes_70" 69 "IdleMinutes_69" 68 "IdleMinutes_68" 67 "IdleMinutes_67" 66 "IdleMinutes_66" 65 "IdleMinutes_65" 64 "IdleMinutes_64" 63 "IdleMinutes_63" 62 "IdleMinutes_62" 61 "IdleMinutes_61" 60 "IdleMinutes_60" 59 "IdleMinutes_59" 58 "IdleMinutes_58" 57 "IdleMinutes_57" 56 "IdleMinutes_56" 55 "IdleMinutes_55" 54 "IdleMinutes_54" 53 "IdleMinutes_53" 52 "IdleMinutes_52" 51 "IdleMinutes_51" 50 "IdleMinutes_50" 49 "IdleMinutes_49" 48 "IdleMinutes_48" 47 "IdleMinutes_47" 46 "IdleMinutes_46" 45 "IdleMinutes_45" 44 "IdleMinutes_44" 43 "IdleMinutes_43" 42 "IdleMinutes_42" 41 "IdleMinutes_41" 40 "IdleMinutes_40" 39 "IdleMinutes_39" 38 "IdleMinutes_38" 37 "IdleMinutes_37" 36 "IdleMinutes_36" 35 "IdleMinutes_35" 34 "IdleMinutes_34" 33 "IdleMinutes_33" 32 "IdleMinutes_32" 31 "IdleMinutes_31" 30 "IdleMinutes_30" 29 "IdleMinutes_29" 28 "IdleMinutes_28" 27 "IdleMinutes_27" 26 "IdleMinutes_26" 25 "IdleMinutes_25" 24 "IdleMinutes_24" 23 "IdleMinutes_23" 22 "IdleMinutes_22" 21 "IdleMinutes_21" 20 "IdleMinutes_20" 19 "IdleMinutes_19" 18 "IdleMinutes_18" 17 "IdleMinutes_17" 16 "IdleMinutes_16" 15 "IdleMinutes_15" 14 "IdleMinutes_14" 13 "IdleMinutes_13" 12 "IdleMinutes_12" 11 "IdleMinutes_11" 10 "IdleMinutes_10" 9 "IdleMinutes_9" 8 "IdleMinutes_8" 7 "IdleMinutes_7" 6 "IdleMinutes_6" 5 "IdleMinutes_5" 4 "IdleMinutes_4" 3 "IdleMinutes_3" 2 "IdleMinutes_2" 1 "IdleMinute_1" 0 "Null" ;
VAL_ 595 DrvIdMde_D_Rq 7 "Faulty" 6 "NotUsed_2" 5 "KeepAwake" 4 "DeleteMid" 3 "ClearAll" 2 "Enroll" 1 "Recognize" 0 "Disable" ;
VAL_ 596 DrvIdMde_D_Stat 7 "Temp_unavailable" 6 "Idle" 5 "DBCorrupt" 4 "DeleteMid" 3 "ClearAll" 2 "Enroll" 1 "Recognize" 0 "Null" ;
VAL_ 596 DrvIdActn_D_Stat 3 "NotUsed" 2 "Success" 1 "Fail" 0 "Null" ;
VAL_ 596 DrvId_D_Stat 7 "NotUsed_3" 6 "NotUsed_2" 5 "NotUsed_1" 4 "FailTimeout" 3 "FailWeakMatch" 2 "OkNoMatch" 1 "OkMatched" 0 "Null" ;
VAL_ 596 DrvExpression_D_Stat 15 "NotUsed_5" 14 "NotUsed_4" 13 "NotUsed_3" 12 "FailMultipleMatches" 11 "FailNoSlot" 10 "HasRegister" 9 "ConstraintsOk" 8 "NotAFace" 7 "PoorTrackingQuality" 6 "EyesNotVisible" 5 "FaceBlockage" 4 "MouthOpen" 3 "OutsidePoseLimits" 2 "TooManyFaces" 1 "FaceNotInView" 0 "Null" ;
VAL_ 966 NfcDevcAuthrzT_B_Rq 1 "Valid" 0 "Null" ;
VAL_ 966 NfcDevc_D_Dsply 15 "Message 15" 14 "Message 14" 13 "Message 13" 12 "Message 12" 11 "Message 11" 10 "Message 10" 9 "Message 9" 8 "Message 8" 7 "Message 7" 6 "Message 6" 5 "Message 5" 4 "Message 4" 3 "Message 3" 2 "Message 2" 1 "Message 1" 0 "No message" ;
VAL_ 966 PwTrnkFrntRelay_B_Stat 1 "Inhibit" 0 "NoInhibit" ;
VAL_ 966 PwTrnkFrontRleas_D_Src 15 "NotUsed_5" 14 "NotUsed_4" 13 "NotUsed_3" 12 "NotUsed_2" 11 "NotUsed_1" 10 "SelfTest" 9 "Diagnostics" 8 "EmergencyReleaseSwitch" 7 "ManualCinch" 6 "ExteriorSwitch" 5 "IpSwitch" 4 "Cpp" 3 "Sync" 2 "Keypad" 1 "Remote" 0 "PowerOff" ;
VAL_ 966 TrnkFrontScnd_B_Falt 1 "Fault" 0 "NoFault" ;
VAL_ 966 ExtLghtRear_D_RqBody 3 "NotUsed" 2 "On" 1 "Off" 0 "Null" ;
VAL_ 966 TrnkFrontInhbt_B_Stat 1 "Inhibit" 0 "NoInhibit" ;
VAL_ 966 TrnkFrontRleas_D_Src 7 "NotUsed_3" 6 "NotUsed_2" 5 "NotUsed_1" 4 "Cpp" 3 "Sync" 2 "Keypad" 1 "Remote" 0 "Null" ;
VAL_ 966 VehHorn_D_RqAlrt 3 "NotUsed" 2 "Null" 1 "On" 0 "Off" ;
VAL_ 966 VehHorn_D_Rq 15 "NotUsed_7" 14 "NotUsed_6" 13 "NotUsed_5" 12 "NotUsed_4" 11 "NotUsed_3" 10 "NotUsed_2" 9 "NotUsed_1" 8 "Chirp_3" 7 "ManualOn" 6 "Honk" 5 "ChirpHonk" 4 "Chirp_2H" 3 "Chirp_2" 2 "Chirp_1" 1 "Null" 0 "Off" ;
VAL_ 966 ScrtyHornActv_B_Rq 1 "Active" 0 "Inactive" ;
VAL_ 1104 DrvEngageLevel_D_Stat 7 "Faulty" 6 "NotUsed_2" 5 "NotUsed_1" 4 "Disengaged" 3 "Distracted" 2 "Attentive" 1 "Invalid" 0 "NotDetermined" ;
VAL_ 1104 DrvImpLvlConfid_D_Stat 7 "Faulty" 6 "NotUsed" 5 "High" 4 "MediumHigh" 3 "Medium" 2 "LowMedium" 1 "Low" 0 "NotDetermined" ;
VAL_ 1104 DrvImpairLvl_D_Stat 15 "Faulty" 14 "NotUsed_5" 13 "NotUsed_4" 12 "NotUsed_3" 11 "NotUsed_2" 10 "NotUsed_1" 9 "Incapacitated" 8 "Asleep" 7 "Microsleep" 6 "MostDrowsy" 5 "Drowsy_4" 4 "Drowsy_3" 3 "Drowsy_2" 2 "LeastDrowsy" 1 "Alert" 0 "NotDetermined" ;
VAL_ 1104 DrvEngLvlConfid_D_Stat 7 "Faulty" 6 "NotUsed" 5 "High" 4 "MediumHigh" 3 "Medium" 2 "LowMedium" 1 "Low" 0 "NotDetermined" ;
VAL_ 1104 DrvCamPassIR_D_Stat 3 "Faulty" 2 "Blocked" 1 "Ok" 0 "TemporaryUnavailable" ;
VAL_ 1104 DrvCamera_D_Stat 3 "Faulty" 2 "Blocked" 1 "Ok" 0 "TemporaryUnavailable" ;
VAL_ 1104 DrvCamDrvIR_D_Stat 3 "Faulty" 2 "Blocked" 1 "Ok" 0 "TemporaryUnavailable" ;
VAL_ 1104 DrvAttentZone_D_Stat 15 "Faulty" 14 "NotUsed_5" 13 "NotUsed_4" 12 "NotUsed_3" 11 "NotConfigured" 10 "DriverLap" 9 "PassengerSideWindow" 8 "DriverSideWindow" 7 "DriverSideMirror" 6 "RearviewMirror" 5 "PassengerSideMirror" 4 "Infotainment" 3 "Cluster" 2 "FrontWindshield" 1 "Other" 0 "NotDetermined" ;
VAL_ 1104 DrvAlertSt_D_Stat 3 "Faulty" 2 "EyesOffRoad" 1 "EyesOnRoad" 0 "NotDetermined" ;
VAL_ 303 DrStatHood_D2_Actl 5 "NotUsed_2" 4 "NotUsed_1" 3 "Disabled" 2 "Ajar" 1 "Closed" 0 "NotDetermined" 7 "Faulty" 6 "NotUsed_3" ;
SIG_GROUP_ 932 Profile1A_SigGroup_FD1_3A4_Copy_ 1 : VehOnSrc2_D_Stat VehOnCtl_D_Stat VehStrtInhbt_D_Stat CanMsg3A4_No_Cnt VehInhbtMde_D_Stat CanMsg3A4_No_Crc;
